VERSION ""

NS_ :

BS_:

BU_:

BO_ 2561146622 AUXIO2: 8 Vector__XXX
 SG_ AuxiliaryIO17 : 6|2@1+ (1,0) [0|3] "" Vector__XXX
 SG_ AuxiliaryIO18 : 4|2@1+ (1,0) [0|3] "" Vector__XXX
 SG_ AuxiliaryIO19 : 2|2@1+ (1,0) [0|3] "" Vector__XXX
 SG_ AuxiliaryIO20 : 0|2@1+ (1,0) [0|3] "" Vector__XXX
 SG_ AuxiliaryIO21 : 14|2@1+ (1,0) [0|3] "" Vector__XXX
 SG_ AuxiliaryIO22 : 12|2@1+ (1,0) [0|3] "" Vector__XXX
 SG_ AuxiliaryIO23 : 10|2@1+ (1,0) [0|3] "" Vector__XXX
 SG_ AuxiliaryIO24 : 8|2@1+ (1,0) [0|3] "" Vector__XXX
 SG_ AuxiliaryIO25 : 22|2@1+ (1,0) [0|3] "" Vector__XXX
 SG_ AuxiliaryIO26 : 20|2@1+ (1,0) [0|3] "" Vector__XXX
 SG_ AuxiliaryIO27 : 18|2@1+ (1,0) [0|3] "" Vector__XXX
 SG_ AuxiliaryIO28 : 16|2@1+ (1,0) [0|3] "" Vector__XXX
 SG_ AuxiliaryIO29 : 30|2@1+ (1,0) [0|3] "" Vector__XXX
 SG_ AuxiliaryIO30 : 28|2@1+ (1,0) [0|3] "" Vector__XXX
 SG_ AuxiliaryIO31 : 26|2@1+ (1,0) [0|3] "" Vector__XXX
 SG_ AuxiliaryIO32 : 24|2@1+ (1,0) [0|3] "" Vector__XXX
 SG_ AuxiliaryIO33 : 38|2@1+ (1,0) [0|3] "" Vector__XXX
 SG_ AuxiliaryIO34 : 36|2@1+ (1,0) [0|3] "" Vector__XXX
 SG_ AuxiliaryIO35 : 34|2@1+ (1,0) [0|3] "" Vector__XXX
 SG_ AuxiliaryIO36 : 32|2@1+ (1,0) [0|3] "" Vector__XXX
 SG_ AuxiliaryIO37 : 46|2@1+ (1,0) [0|3] "" Vector__XXX
 SG_ AuxiliaryIO38 : 44|2@1+ (1,0) [0|3] "" Vector__XXX
 SG_ AuxiliaryIO39 : 42|2@1+ (1,0) [0|3] "" Vector__XXX
 SG_ AuxiliaryIO40 : 40|2@1+ (1,0) [0|3] "" Vector__XXX
 SG_ AuxiliaryIO41 : 54|2@1+ (1,0) [0|3] "" Vector__XXX
 SG_ AuxiliaryIO42 : 52|2@1+ (1,0) [0|3] "" Vector__XXX
 SG_ AuxiliaryIO43 : 50|2@1+ (1,0) [0|3] "" Vector__XXX
 SG_ AuxiliaryIO44 : 48|2@1+ (1,0) [0|3] "" Vector__XXX
 SG_ AuxiliaryIO45 : 62|2@1+ (1,0) [0|3] "" Vector__XXX
 SG_ AuxiliaryIO46 : 60|2@1+ (1,0) [0|3] "" Vector__XXX
 SG_ AuxiliaryIO47 : 58|2@1+ (1,0) [0|3] "" Vector__XXX
 SG_ AuxiliaryIO48 : 56|2@1+ (1,0) [0|3] "" Vector__XXX

BO_ 2561212158 DISP1: 8 Vector__XXX
 SG_ TextDisplayIndex : 16|8@1+ (1,0) [0|250] "count" Vector__XXX
 SG_ TextDisplayInstructions : 0|4@1+ (1,0) [0|15] "" Vector__XXX

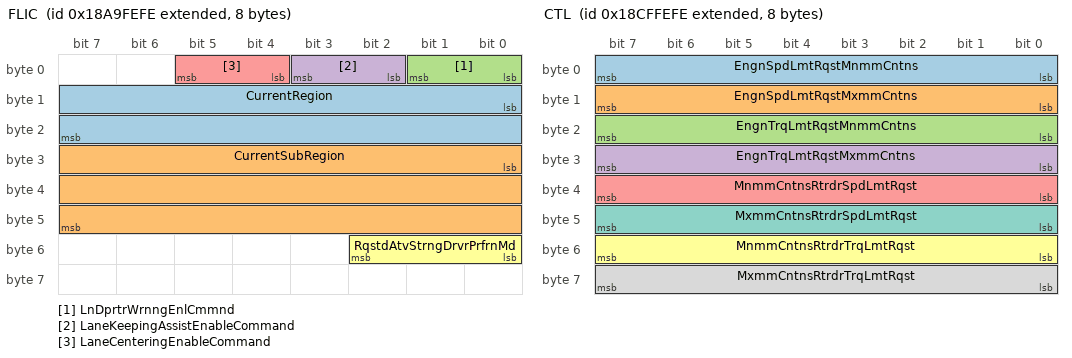
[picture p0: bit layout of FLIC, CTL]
BO_ 2561277694 FLIC: 8 Vector__XXX
 SG_ CurrentRegion : 8|16@1+ (1,0) [0|255] "ASCII" Vector__XXX
 SG_ CurrentSubRegion : 24|24@1+ (1,0) [0|255] "ASCII" Vector__XXX
 SG_ LnDprtrWrnngEnlCmmnd : 0|2@1+ (1,0) [0|3] "" Vector__XXX
 SG_ LaneKeepingAssistEnableCommand : 2|2@1+ (1,0) [0|3] "" Vector__XXX
 SG_ LaneCenteringEnableCommand : 4|2@1+ (1,0) [0|3] "" Vector__XXX
 SG_ RqstdAtvStrngDrvrPrfrnMd : 48|3@1+ (1,0) [0|7] "" Vector__XXX

BO_ 2561605374 TPRS: 8 Vector__XXX
 SG_ ReferenceTirePressureSetting : 8|8@1+ (8,0) [0|2000] "kPa" Vector__XXX
 SG_ TireLocation : 0|8@1+ (1,0) [0|255] "" Vector__XXX

BO_ 2563768062 CTL: 8 Vector__XXX
 SG_ EngnSpdLmtRqstMnmmCntns : 0|8@1+ (32,0) [0|8000] "rpm" Vector__XXX
 SG_ EngnSpdLmtRqstMxmmCntns : 8|8@1+ (32,0) [0|8000] "rpm" Vector__XXX
 SG_ EngnTrqLmtRqstMnmmCntns : 16|8@1+ (1,-125) [-125|125] "%" Vector__XXX
 SG_ EngnTrqLmtRqstMxmmCntns : 24|8@1+ (1,-125) [-125|125] "%" Vector__XXX
 SG_ MnmmCntnsRtrdrSpdLmtRqst : 32|8@1+ (32,0) [0|8000] "rpm" Vector__XXX
 SG_ MnmmCntnsRtrdrTrqLmtRqst : 48|8@1+ (1,-125) [-125|125] "%" Vector__XXX
 SG_ MxmmCntnsRtrdrSpdLmtRqst : 40|8@1+ (32,0) [0|8000] "rpm" Vector__XXX
 SG_ MxmmCntnsRtrdrTrqLmtRqst : 56|8@1+ (1,-125) [-125|125] "%" Vector__XXX

BO_ 2563833598 CL: 8 Vector__XXX
 SG_ IlluminationBrightnessPercent : 0|8@1+ (0.4,0) [0|100] "%" Vector__XXX
 SG_ SwthBklghtIllmntnBrghtnssPrnt : 8|8@1+ (0.4,0) [0|100] "%" Vector__XXX
 SG_ SwthIndtnIllmntnBrghtnssPrnt : 16|8@1+ (0.4,0) [0|100] "%" Vector__XXX

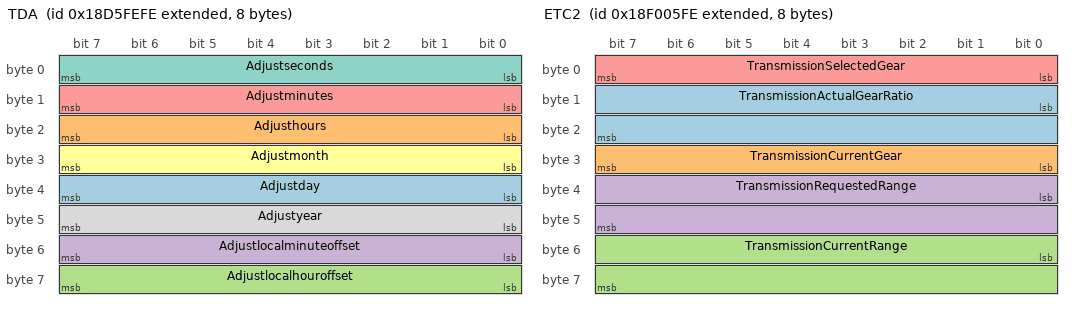
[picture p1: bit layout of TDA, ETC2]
BO_ 2564161278 TDA: 8 Vector__XXX
 SG_ Adjustday : 32|8@1+ (0.25,0) [0|62.5] "days" Vector__XXX
 SG_ Adjusthours : 16|8@1+ (1,0) [0|250] "h" Vector__XXX
 SG_ Adjustlocalhouroffset : 56|8@1+ (1,-125) [-125|125] "h" Vector__XXX
 SG_ Adjustlocalminuteoffset : 48|8@1+ (1,-125) [-125|125] "min" Vector__XXX
 SG_ Adjustminutes : 8|8@1+ (1,0) [0|250] "min" Vector__XXX
 SG_ Adjustmonth : 24|8@1+ (1,0) [0|250] "months" Vector__XXX
 SG_ Adjustseconds : 0|8@1+ (0.25,0) [0|62.5] "s" Vector__XXX
 SG_ Adjustyear : 40|8@1+ (1,1985) [1985|2235] "years" Vector__XXX

BO_ 2564882174 CM1: 8 Vector__XXX
 SG_ AftrtrtmntRgnrtnFrSwth : 42|2@1+ (1,0) [0|3] "" Vector__XXX
 SG_ AftrtrtmntRgnrtnInhtSwth : 40|2@1+ (1,0) [0|3] "" Vector__XXX
 SG_ AtmtGrShftngEnlSwth : 44|2@1+ (1,0) [0|3] "" Vector__XXX
 SG_ AuxiliaryHeaterModeRequest : 48|4@1+ (1,0) [0|15] "" Vector__XXX
 SG_ AxlrHtrClntPmpRqst : 24|2@1+ (1,0) [0|3] "" Vector__XXX
 SG_ BatteryMainSwitchHoldRequest : 26|2@1+ (1,0) [0|3] "" Vector__XXX
 SG_ CabInteriorTemperatureCommand : 8|16@1+ (0.03125,-273) [-273|1734.96875] "degC" Vector__XXX
 SG_ EngineFan1RequestedPercentSpeed : 0|8@1+ (0.4,0) [0|100] "%" Vector__XXX
 SG_ EngnAtmtStrtEnlSwth : 46|2@1+ (1,0) [0|3] "" Vector__XXX
 SG_ OperatorSeatDirectionSwitch : 28|2@1+ (1,0) [0|3] "" Vector__XXX
 SG_ ParkBrakeCommand : 32|2@1+ (1,0) [0|3] "" Vector__XXX
 SG_ RequestCabZoneHeating : 54|2@1+ (1,0) [0|3] "" Vector__XXX
 SG_ RequestEngineZoneHeating : 52|2@1+ (1,0) [0|3] "" Vector__XXX
 SG_ SeatBeltSwitch : 30|2@1+ (1,0) [0|3] "" Vector__XXX
 SG_ SltdMxmmVhlSpdLmt : 56|8@1+ (1,0) [0|250] "count" Vector__XXX
 SG_ VhlLmtngSpdGvrnrDrmntSwth : 34|2@1+ (1,0) [0|3] "" Vector__XXX
 SG_ VhlLmtngSpdGvrnrEnlSwth : 38|2@1+ (1,0) [0|3] "" Vector__XXX
 SG_ VhlLmtngSpdGvrnrInrmntSwth : 36|2@1+ (1,0) [0|3] "" Vector__XXX

BO_ 2565865982 EBC1: 8 Vector__XXX
 SG_ ABSEBSAmrWrnngSgnlPwrdVhl : 44|2@1+ (1,0) [0|3] "" Vector__XXX
 SG_ ABSFullyOperational : 40|2@1+ (1,0) [0|3] "" Vector__XXX
 SG_ ABSOffroadSwitch : 16|2@1+ (1,0) [0|3] "" Vector__XXX
 SG_ AcceleratorInterlockSwitch : 24|2@1+ (1,0) [0|3] "" Vector__XXX
 SG_ AntiLockBrakingABSActive : 4|2@1+ (1,0) [0|3] "" Vector__XXX
 SG_ ASRBrakeControlActive : 2|2@1+ (1,0) [0|3] "" Vector__XXX
 SG_ ASREngineControlActive : 0|2@1+ (1,0) [0|3] "" Vector__XXX
 SG_ ASRHillHolderSwitch : 20|2@1+ (1,0) [0|3] "" Vector__XXX
 SG_ ASROffroadSwitch : 18|2@1+ (1,0) [0|3] "" Vector__XXX
 SG_ ATCASRInformationSignal : 46|2@1+ (1,0) [0|3] "" Vector__XXX
 SG_ BrakePedalPosition : 8|8@1+ (0.4,0) [0|100] "%" Vector__XXX
 SG_ EBSBrakeSwitch : 6|2@1+ (1,0) [0|3] "" Vector__XXX
 SG_ EBSRedWarningSignal : 42|2@1+ (1,0) [0|3] "" Vector__XXX
 SG_ EngineAuxiliaryShutdownSwitch : 28|2@1+ (1,0) [0|3] "" Vector__XXX
 SG_ EngineDerateSwitch : 26|2@1+ (1,0) [0|3] "" Vector__XXX
 SG_ EngineRetarderSelection : 32|8@1+ (0.4,0) [0|100] "%" Vector__XXX
 SG_ Haltbrakeswitch : 58|2@1+ (1,0) [0|3] "" Vector__XXX
 SG_ RailroadModeSwitch : 56|2@1+ (1,0) [0|3] "" Vector__XXX
 SG_ RemoteAcceleratorEnableSwitch : 30|2@1+ (1,0) [0|3] "" Vector__XXX
 SG_ SrAddrssfCntrllngDvfrBrkCntrl : 48|8@1+ (1,0) [0|255] "SA" Vector__XXX
 SG_ TractionControlOverrideSwitch : 22|2@1+ (1,0) [0|3] "" Vector__XXX
 SG_ TrailerABSStatus : 60|2@1+ (1,0) [0|3] "" Vector__XXX
 SG_ TrtrMntdTrlrABSWrnngSgnl : 62|2@1+ (1,0) [0|3] "" Vector__XXX

BO_ 2565867006 ETC2: 8 Vector__XXX
 SG_ TransmissionActualGearRatio : 8|16@1+ (0.001,0) [0|64.255] "Ratio" Vector__XXX
 SG_ TransmissionCurrentGear : 24|8@1+ (1,-125) [-125|125] "gear value" Vector__XXX
 SG_ TransmissionCurrentRange : 48|16@1+ (1,0) [0|255] "ASCII" Vector__XXX
 SG_ TransmissionRequestedRange : 32|16@1+ (1,0) [0|255] "ASCII" Vector__XXX
 SG_ TransmissionSelectedGear : 0|8@1+ (1,-125) [-125|125] "gear value" Vector__XXX

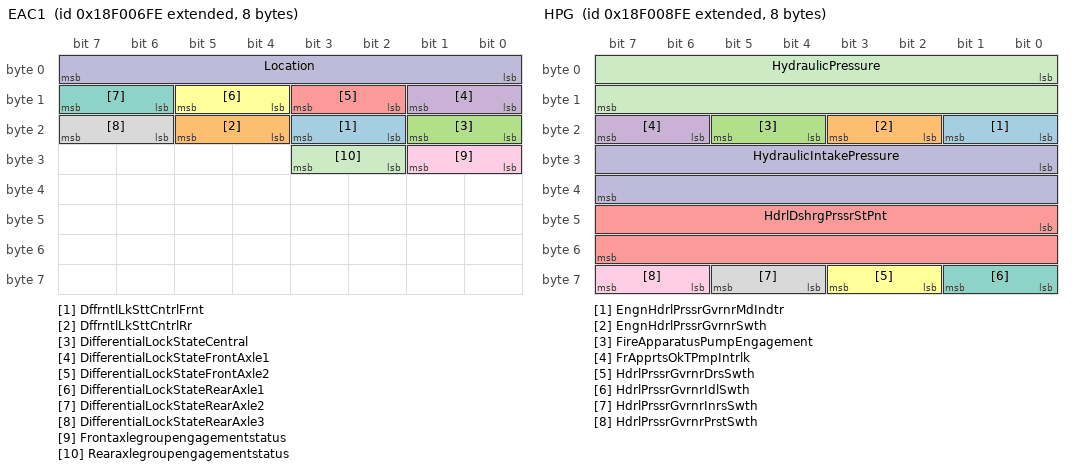
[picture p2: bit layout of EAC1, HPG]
BO_ 2565867262 EAC1: 8 Vector__XXX
 SG_ DffrntlLkSttCntrlFrnt : 18|2@1+ (1,0) [0|3] "" Vector__XXX
 SG_ DffrntlLkSttCntrlRr : 20|2@1+ (1,0) [0|3] "" Vector__XXX
 SG_ DifferentialLockStateCentral : 16|2@1+ (1,0) [0|3] "" Vector__XXX
 SG_ DifferentialLockStateFrontAxle1 : 8|2@1+ (1,0) [0|3] "" Vector__XXX
 SG_ DifferentialLockStateFrontAxle2 : 10|2@1+ (1,0) [0|3] "" Vector__XXX
 SG_ DifferentialLockStateRearAxle1 : 12|2@1+ (1,0) [0|3] "" Vector__XXX
 SG_ DifferentialLockStateRearAxle2 : 14|2@1+ (1,0) [0|3] "" Vector__XXX
 SG_ DifferentialLockStateRearAxle3 : 22|2@1+ (1,0) [0|3] "" Vector__XXX
 SG_ Frontaxlegroupengagementstatus : 24|2@1+ (1,0) [0|3] "" Vector__XXX
 SG_ Location : 0|8@1+ (1,0) [0|255] "" Vector__XXX
 SG_ Rearaxlegroupengagementstatus : 26|2@1+ (1,0) [0|3] "" Vector__XXX

BO_ 2565867774 HPG: 8 Vector__XXX
 SG_ EngnHdrlPrssrGvrnrMdIndtr : 16|2@1+ (1,0) [0|3] "" Vector__XXX
 SG_ EngnHdrlPrssrGvrnrSwth : 18|2@1+ (1,0) [0|3] "" Vector__XXX
 SG_ FireApparatusPumpEngagement : 20|2@1+ (1,0) [0|3] "" Vector__XXX
 SG_ FrApprtsOkTPmpIntrlk : 22|2@1+ (1,0) [0|3] "" Vector__XXX
 SG_ HdrlDshrgPrssrStPnt : 40|16@1+ (2,0) [0|128510] "kPa" Vector__XXX
 SG_ HdrlPrssrGvrnrDrsSwth : 58|2@1+ (1,0) [0|3] "" Vector__XXX
 SG_ HdrlPrssrGvrnrIdlSwth : 56|2@1+ (1,0) [0|3] "" Vector__XXX
 SG_ HdrlPrssrGvrnrInrsSwth : 60|2@1+ (1,0) [0|3] "" Vector__XXX
 SG_ HdrlPrssrGvrnrPrstSwth : 62|2@1+ (1,0) [0|3] "" Vector__XXX
 SG_ HydraulicIntakePressure : 24|16@1+ (0.0001220703125,-1) [-1|6.84362793] "MPa" Vector__XXX
 SG_ HydraulicPressure : 0|16@1+ (2,0) [0|128510] "kPa" Vector__XXX

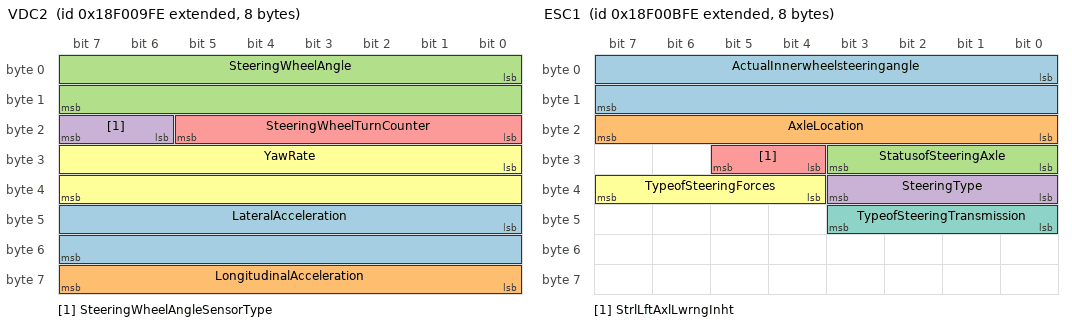
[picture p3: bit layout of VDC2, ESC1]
BO_ 2565868030 VDC2: 8 Vector__XXX
 SG_ LateralAcceleration : 40|16@1+ (0.00048828125,-15.687) [-15.687|15.687] "m/(s*s)" Vector__XXX
 SG_ LongitudinalAcceleration : 56|8@1+ (0.1,-12.5) [-12.5|12.5] "m/(s*s)" Vector__XXX
 SG_ SteeringWheelAngle : 0|16@1+ (0.0009765625,-31.374) [-31.374|31.374] "rad" Vector__XXX
 SG_ SteeringWheelAngleSensorType : 22|2@1+ (1,0) [0|3] "" Vector__XXX
 SG_ SteeringWheelTurnCounter : 16|6@1+ (1,-32) [-32|29] "turns" Vector__XXX
 SG_ YawRate : 24|16@1+ (0.0001220703125,-3.92) [-3.92|3.92] "rad/s" Vector__XXX

BO_ 2565868542 ESC1: 8 Vector__XXX
 SG_ ActualInnerwheelsteeringangle : 0|16@1+ (0.00390625,-125) [-125|125] "deg" Vector__XXX
 SG_ AxleLocation : 16|8@1+ (1,0) [0|255] "" Vector__XXX
 SG_ StatusofSteeringAxle : 24|4@1+ (1,0) [0|15] "" Vector__XXX
 SG_ SteeringType : 32|4@1+ (1,0) [0|15] "" Vector__XXX
 SG_ StrlLftAxlLwrngInht : 28|2@1+ (1,0) [0|3] "" Vector__XXX
 SG_ TypeofSteeringForces : 36|4@1+ (1,0) [0|15] "" Vector__XXX
 SG_ TypeofSteeringTransmission : 40|4@1+ (1,0) [0|15] "" Vector__XXX

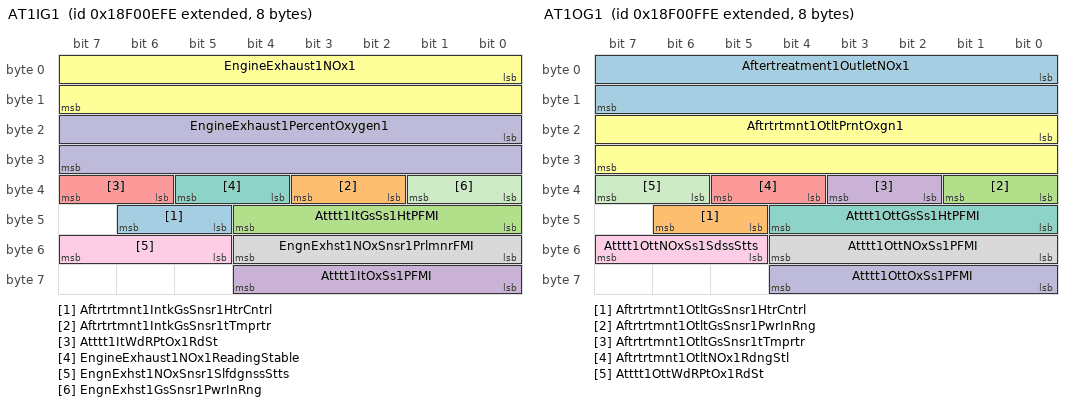
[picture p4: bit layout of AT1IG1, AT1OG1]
BO_ 2565869310 AT1IG1: 8 Vector__XXX
 SG_ Aftrtrtmnt1IntkGsSnsr1HtrCntrl : 45|2@1+ (1,0) [0|3] "" Vector__XXX
 SG_ Aftrtrtmnt1IntkGsSnsr1tTmprtr : 34|2@1+ (1,0) [0|3] "" Vector__XXX
 SG_ Atttt1ItGsSs1HtPFMI : 40|5@1+ (1,0) [0|31] "binary" Vector__XXX
 SG_ Atttt1ItOxSs1PFMI : 56|5@1+ (1,0) [0|31] "binary" Vector__XXX
 SG_ Atttt1ItWdRPtOx1RdSt : 38|2@1+ (1,0) [0|3] "" Vector__XXX
 SG_ EngineExhaust1NOx1 : 0|16@1+ (0.05,-200) [-200|3012.75] "ppm" Vector__XXX
 SG_ EngineExhaust1NOx1ReadingStable : 36|2@1+ (1,0) [0|3] "" Vector__XXX
 SG_ EngnExhst1NOxSnsr1PrlmnrFMI : 48|5@1+ (1,0) [0|31] "binary" Vector__XXX
 SG_ EngnExhst1NOxSnsr1SlfdgnssStts : 53|3@1+ (1,0) [0|7] "" Vector__XXX
 SG_ EngineExhaust1PercentOxygen1 : 16|16@1+ (0.000514,-12) [-12|21.02707] "%" Vector__XXX
 SG_ EngnExhst1GsSnsr1PwrInRng : 32|2@1+ (1,0) [0|3] "" Vector__XXX

BO_ 2565869566 AT1OG1: 8 Vector__XXX
 SG_ Aftertreatment1OutletNOx1 : 0|16@1+ (0.05,-200) [-200|3012.75] "ppm" Vector__XXX
 SG_ Aftrtrtmnt1OtltGsSnsr1HtrCntrl : 45|2@1+ (1,0) [0|3] "" Vector__XXX
 SG_ Aftrtrtmnt1OtltGsSnsr1PwrInRng : 32|2@1+ (1,0) [0|3] "" Vector__XXX
 SG_ Aftrtrtmnt1OtltGsSnsr1tTmprtr : 34|2@1+ (1,0) [0|3] "" Vector__XXX
 SG_ Aftrtrtmnt1OtltNOx1RdngStl : 36|2@1+ (1,0) [0|3] "" Vector__XXX
 SG_ Aftrtrtmnt1OtltPrntOxgn1 : 16|16@1+ (0.000514,-12) [-12|21.02707] "%" Vector__XXX
 SG_ Atttt1OttGsSs1HtPFMI : 40|5@1+ (1,0) [0|31] "binary" Vector__XXX
 SG_ Atttt1OttNOxSs1PFMI : 48|5@1+ (1,0) [0|31] "binary" Vector__XXX
 SG_ Atttt1OttNOxSs1SdssStts : 53|3@1+ (1,0) [0|7] "" Vector__XXX
 SG_ Atttt1OttOxSs1PFMI : 56|5@1+ (1,0) [0|31] "binary" Vector__XXX
 SG_ Atttt1OttWdRPtOx1RdSt : 38|2@1+ (1,0) [0|3] "" Vector__XXX

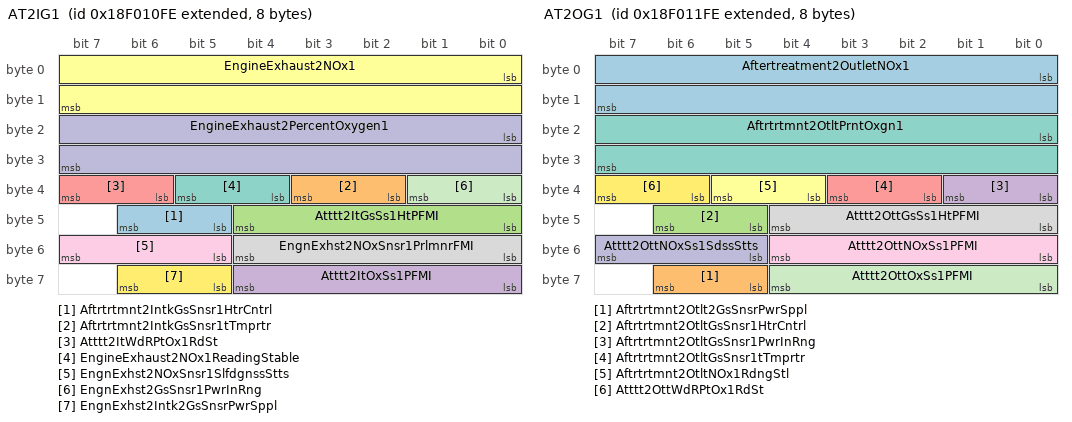
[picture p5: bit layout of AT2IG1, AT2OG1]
BO_ 2565869822 AT2IG1: 8 Vector__XXX
 SG_ Aftrtrtmnt2IntkGsSnsr1HtrCntrl : 45|2@1+ (1,0) [0|3] "" Vector__XXX
 SG_ Aftrtrtmnt2IntkGsSnsr1tTmprtr : 34|2@1+ (1,0) [0|3] "" Vector__XXX
 SG_ Atttt2ItGsSs1HtPFMI : 40|5@1+ (1,0) [0|31] "binary" Vector__XXX
 SG_ Atttt2ItOxSs1PFMI : 56|5@1+ (1,0) [0|31] "binary" Vector__XXX
 SG_ Atttt2ItWdRPtOx1RdSt : 38|2@1+ (1,0) [0|3] "" Vector__XXX
 SG_ EngineExhaust2NOx1 : 0|16@1+ (0.05,-200) [-200|3012.75] "ppm" Vector__XXX
 SG_ EngineExhaust2NOx1ReadingStable : 36|2@1+ (1,0) [0|3] "" Vector__XXX
 SG_ EngnExhst2NOxSnsr1PrlmnrFMI : 48|5@1+ (1,0) [0|31] "binary" Vector__XXX
 SG_ EngnExhst2NOxSnsr1SlfdgnssStts : 53|3@1+ (1,0) [0|7] "" Vector__XXX
 SG_ EngineExhaust2PercentOxygen1 : 16|16@1+ (0.000514,-12) [-12|21.02707] "%" Vector__XXX
 SG_ EngnExhst2GsSnsr1PwrInRng : 32|2@1+ (1,0) [0|3] "" Vector__XXX
 SG_ EngnExhst2Intk2GsSnsrPwrSppl : 61|2@1+ (1,0) [0|3] "" Vector__XXX

BO_ 2565870078 AT2OG1: 8 Vector__XXX
 SG_ Aftertreatment2OutletNOx1 : 0|16@1+ (0.05,-200) [-200|3012.75] "ppm" Vector__XXX
 SG_ Aftrtrtmnt2Otlt2GsSnsrPwrSppl : 61|2@1+ (1,0) [0|3] "" Vector__XXX
 SG_ Aftrtrtmnt2OtltGsSnsr1HtrCntrl : 45|2@1+ (1,0) [0|3] "" Vector__XXX
 SG_ Aftrtrtmnt2OtltGsSnsr1PwrInRng : 32|2@1+ (1,0) [0|3] "" Vector__XXX
 SG_ Aftrtrtmnt2OtltGsSnsr1tTmprtr : 34|2@1+ (1,0) [0|3] "" Vector__XXX
 SG_ Aftrtrtmnt2OtltNOx1RdngStl : 36|2@1+ (1,0) [0|3] "" Vector__XXX
 SG_ Aftrtrtmnt2OtltPrntOxgn1 : 16|16@1+ (0.000514,-12) [-12|21.02707] "%" Vector__XXX
 SG_ Atttt2OttGsSs1HtPFMI : 40|5@1+ (1,0) [0|31] "binary" Vector__XXX
 SG_ Atttt2OttNOxSs1PFMI : 48|5@1+ (1,0) [0|31] "binary" Vector__XXX
 SG_ Atttt2OttNOxSs1SdssStts : 53|3@1+ (1,0) [0|7] "" Vector__XXX
 SG_ Atttt2OttOxSs1PFMI : 56|5@1+ (1,0) [0|31] "binary" Vector__XXX
 SG_ Atttt2OttWdRPtOx1RdSt : 38|2@1+ (1,0) [0|3] "" Vector__XXX

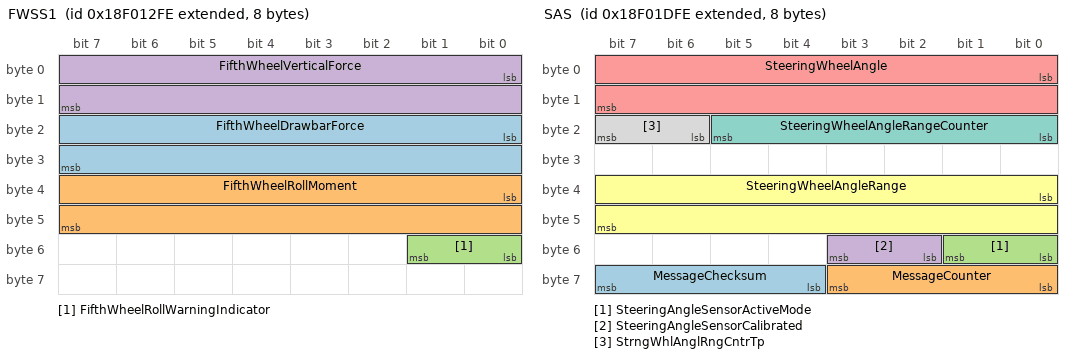
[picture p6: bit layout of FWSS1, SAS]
BO_ 2565870334 FWSS1: 8 Vector__XXX
 SG_ FifthWheelDrawbarForce : 16|16@1+ (10,-320000) [-320000|322550] "N" Vector__XXX
 SG_ FifthWheelRollMoment : 32|16@1+ (10,-320000) [-320000|322550] "N" Vector__XXX
 SG_ FifthWheelRollWarningIndicator : 48|2@1+ (1,0) [0|3] "" Vector__XXX
 SG_ FifthWheelVerticalForce : 0|16@1+ (5,0) [0|321275] "N" Vector__XXX

BO_ 2565873150 SAS: 8 Vector__XXX
 SG_ MessageChecksum : 60|4@1+ (1,0) [0|15] "count" Vector__XXX
 SG_ MessageCounter : 56|4@1+ (1,0) [0|15] "count" Vector__XXX
 SG_ SteeringAngleSensorActiveMode : 48|2@1+ (1,0) [0|3] "" Vector__XXX
 SG_ SteeringAngleSensorCalibrated : 50|2@1+ (1,0) [0|3] "" Vector__XXX
 SG_ SteeringWheelAngle : 0|16@1+ (0.0009765625,-31.374) [-31.374|31.374] "rad" Vector__XXX
 SG_ SteeringWheelAngleRange : 32|16@1+ (0.0009765625,-31.374) [-31.374|31.374] "rad" Vector__XXX
 SG_ SteeringWheelAngleRangeCounter : 16|6@1+ (1,-32) [-32|29] "range" Vector__XXX
 SG_ StrngWhlAnglRngCntrTp : 22|2@1+ (1,0) [0|3] "" Vector__XXX

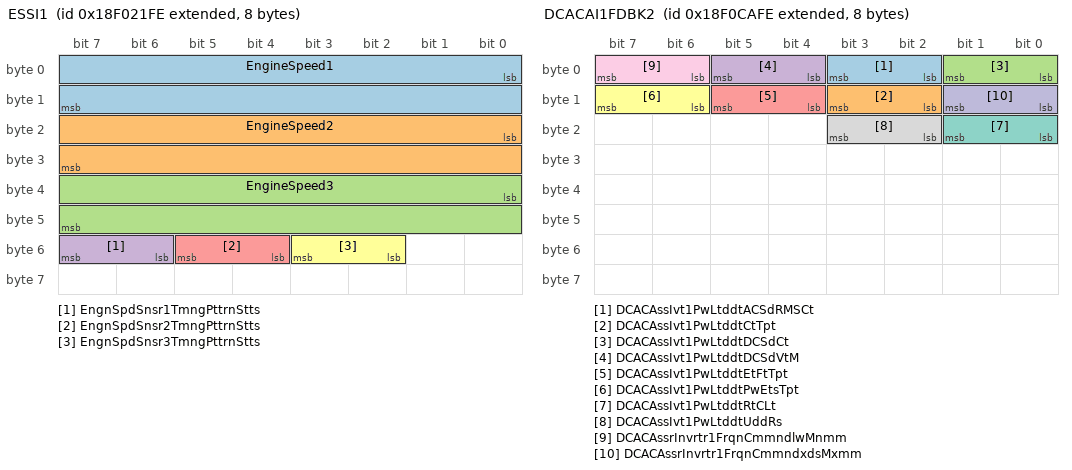
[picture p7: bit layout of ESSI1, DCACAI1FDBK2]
BO_ 2565874174 ESSI1: 8 Vector__XXX
 SG_ EngineSpeed1 : 0|16@1+ (0.5,0) [0|32127.5] "rpm" Vector__XXX
 SG_ EngineSpeed2 : 16|16@1+ (0.5,0) [0|32127.5] "rpm" Vector__XXX
 SG_ EngineSpeed3 : 32|16@1+ (0.5,0) [0|32127.5] "rpm" Vector__XXX
 SG_ EngnSpdSnsr1TmngPttrnStts : 54|2@1+ (1,0) [0|3] "" Vector__XXX
 SG_ EngnSpdSnsr2TmngPttrnStts : 52|2@1+ (1,0) [0|3] "" Vector__XXX
 SG_ EngnSpdSnsr3TmngPttrnStts : 50|2@1+ (1,0) [0|3] "" Vector__XXX

BO_ 2565877502 ETCC: 8 Vector__XXX
 SG_ EExstB1PssRtCtCd : 32|16@1+ (0.0025,0) [0|160.6375] "%" Vector__XXX
 SG_ EngnTrhrgrWstgtAttr1Cmmnd : 0|16@1+ (0.0025,0) [0|160.6375] "%" Vector__XXX
 SG_ EngnTrhrgrWstgtAttr2Cmmnd : 16|16@1+ (0.0025,0) [0|160.6375] "%" Vector__XXX
 SG_ ETCpssBwAtt1Cd : 48|16@1+ (0.0025,0) [0|160.6375] "%" Vector__XXX

BO_ 2565917438 DCACAI1FDBK2: 8 Vector__XXX
 SG_ DCACAssIvt1PwLtddtACSdRMSCt : 2|2@1+ (1,0) [0|3] "" Vector__XXX
 SG_ DCACAssIvt1PwLtddtCtTpt : 10|2@1+ (1,0) [0|3] "" Vector__XXX
 SG_ DCACAssIvt1PwLtddtDCSdCt : 0|2@1+ (1,0) [0|3] "" Vector__XXX
 SG_ DCACAssIvt1PwLtddtDCSdVtM : 4|2@1+ (1,0) [0|3] "" Vector__XXX
 SG_ DCACAssIvt1PwLtddtEtFtTpt : 12|2@1+ (1,0) [0|3] "" Vector__XXX
 SG_ DCACAssIvt1PwLtddtPwEtsTpt : 14|2@1+ (1,0) [0|3] "" Vector__XXX
 SG_ DCACAssIvt1PwLtddtRtCLt : 16|2@1+ (1,0) [0|3] "" Vector__XXX
 SG_ DCACAssIvt1PwLtddtUddRs : 18|2@1+ (1,0) [0|3] "" Vector__XXX
 SG_ DCACAssrInvrtr1FrqnCmmndlwMnmm : 6|2@1+ (1,0) [0|3] "" Vector__XXX
 SG_ DCACAssrInvrtr1FrqnCmmndxdsMxmm : 8|2@1+ (1,0) [0|3] "" Vector__XXX

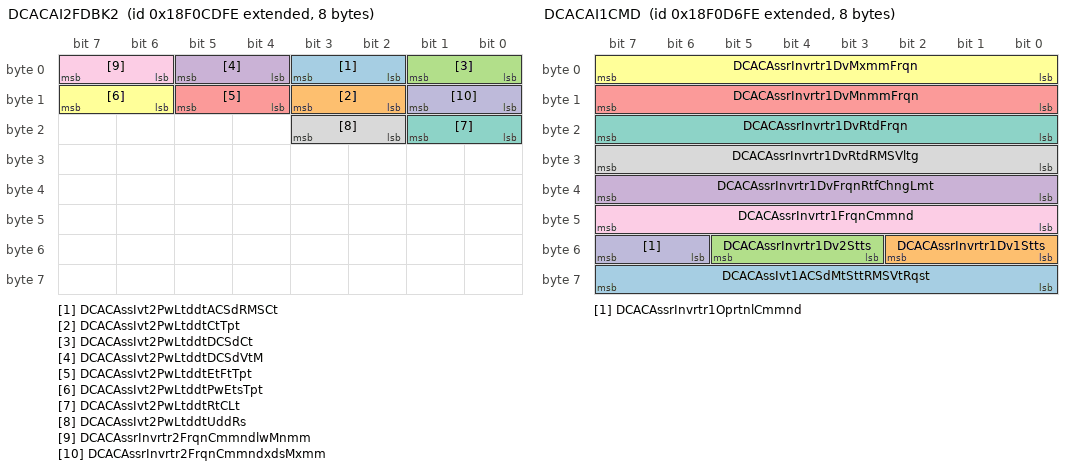
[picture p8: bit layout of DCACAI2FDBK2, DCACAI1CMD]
BO_ 2565918206 DCACAI2FDBK2: 8 Vector__XXX
 SG_ DCACAssIvt2PwLtddtACSdRMSCt : 2|2@1+ (1,0) [0|3] "" Vector__XXX
 SG_ DCACAssIvt2PwLtddtCtTpt : 10|2@1+ (1,0) [0|3] "" Vector__XXX
 SG_ DCACAssIvt2PwLtddtDCSdCt : 0|2@1+ (1,0) [0|3] "" Vector__XXX
 SG_ DCACAssIvt2PwLtddtDCSdVtM : 4|2@1+ (1,0) [0|3] "" Vector__XXX
 SG_ DCACAssIvt2PwLtddtEtFtTpt : 12|2@1+ (1,0) [0|3] "" Vector__XXX
 SG_ DCACAssIvt2PwLtddtPwEtsTpt : 14|2@1+ (1,0) [0|3] "" Vector__XXX
 SG_ DCACAssIvt2PwLtddtRtCLt : 16|2@1+ (1,0) [0|3] "" Vector__XXX
 SG_ DCACAssIvt2PwLtddtUddRs : 18|2@1+ (1,0) [0|3] "" Vector__XXX
 SG_ DCACAssrInvrtr2FrqnCmmndlwMnmm : 6|2@1+ (1,0) [0|3] "" Vector__XXX
 SG_ DCACAssrInvrtr2FrqnCmmndxdsMxmm : 8|2@1+ (1,0) [0|3] "" Vector__XXX

BO_ 2565920510 DCACAI1CMD: 8 Vector__XXX
 SG_ DCACAssIvt1ACSdMtSttRMSVtRqst : 56|8@1+ (2,0) [0|500] "Vrms" Vector__XXX
 SG_ DCACAssrInvrtr1Dv1Stts : 48|3@1+ (1,0) [0|7] "" Vector__XXX
 SG_ DCACAssrInvrtr1Dv2Stts : 51|3@1+ (1,0) [0|7] "" Vector__XXX
 SG_ DCACAssrInvrtr1DvFrqnRtfChngLmt : 32|8@1+ (2,0) [0|500] "Hz/s" Vector__XXX
 SG_ DCACAssrInvrtr1DvMnmmFrqn : 8|8@1+ (1,0) [0|250] "Hz" Vector__XXX
 SG_ DCACAssrInvrtr1DvMxmmFrqn : 0|8@1+ (1,0) [0|250] "Hz" Vector__XXX
 SG_ DCACAssrInvrtr1DvRtdFrqn : 16|8@1+ (1,0) [0|250] "Hz" Vector__XXX
 SG_ DCACAssrInvrtr1DvRtdRMSVltg : 24|8@1+ (2,0) [0|500] "Vrms" Vector__XXX
 SG_ DCACAssrInvrtr1FrqnCmmnd : 40|8@1+ (1,0) [0|250] "Hz" Vector__XXX
 SG_ DCACAssrInvrtr1OprtnlCmmnd : 54|2@1+ (1,0) [0|3] "" Vector__XXX

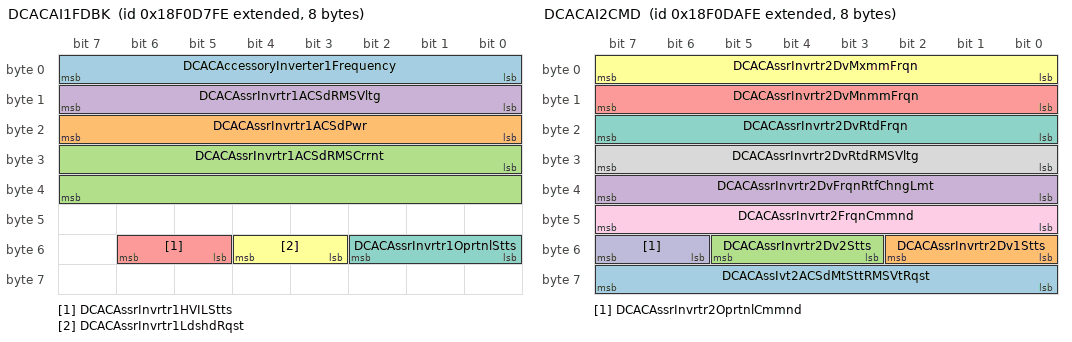
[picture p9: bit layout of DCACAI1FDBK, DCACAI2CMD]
BO_ 2565920766 DCACAI1FDBK: 8 Vector__XXX
 SG_ DCACAccessoryInverter1Frequency : 0|8@1+ (1,0) [0|250] "Hz" Vector__XXX
 SG_ DCACAssrInvrtr1ACSdPwr : 16|8@1+ (0.1,0) [0|25] "kW" Vector__XXX
 SG_ DCACAssrInvrtr1ACSdRMSCrrnt : 24|16@1+ (0.03125,0) [0|2007.96875] "Arms" Vector__XXX
 SG_ DCACAssrInvrtr1ACSdRMSVltg : 8|8@1+ (2,0) [0|500] "Vrms" Vector__XXX
 SG_ DCACAssrInvrtr1HVILStts : 53|2@1+ (1,0) [0|3] "" Vector__XXX
 SG_ DCACAssrInvrtr1LdshdRqst : 51|2@1+ (1,0) [0|3] "" Vector__XXX
 SG_ DCACAssrInvrtr1OprtnlStts : 48|3@1+ (1,0) [0|7] "" Vector__XXX

BO_ 2565921534 DCACAI2CMD: 8 Vector__XXX
 SG_ DCACAssIvt2ACSdMtSttRMSVtRqst : 56|8@1+ (2,0) [0|500] "Vrms" Vector__XXX
 SG_ DCACAssrInvrtr2Dv1Stts : 48|3@1+ (1,0) [0|7] "" Vector__XXX
 SG_ DCACAssrInvrtr2Dv2Stts : 51|3@1+ (1,0) [0|7] "" Vector__XXX
 SG_ DCACAssrInvrtr2DvFrqnRtfChngLmt : 32|8@1+ (2,0) [0|500] "Hz/s" Vector__XXX
 SG_ DCACAssrInvrtr2DvMnmmFrqn : 8|8@1+ (1,0) [0|250] "Hz" Vector__XXX
 SG_ DCACAssrInvrtr2DvMxmmFrqn : 0|8@1+ (1,0) [0|250] "Hz" Vector__XXX
 SG_ DCACAssrInvrtr2DvRtdFrqn : 16|8@1+ (1,0) [0|250] "Hz" Vector__XXX
 SG_ DCACAssrInvrtr2DvRtdRMSVltg : 24|8@1+ (2,0) [0|500] "Vrms" Vector__XXX
 SG_ DCACAssrInvrtr2FrqnCmmnd : 40|8@1+ (1,0) [0|250] "Hz" Vector__XXX
 SG_ DCACAssrInvrtr2OprtnlCmmnd : 54|2@1+ (1,0) [0|3] "" Vector__XXX

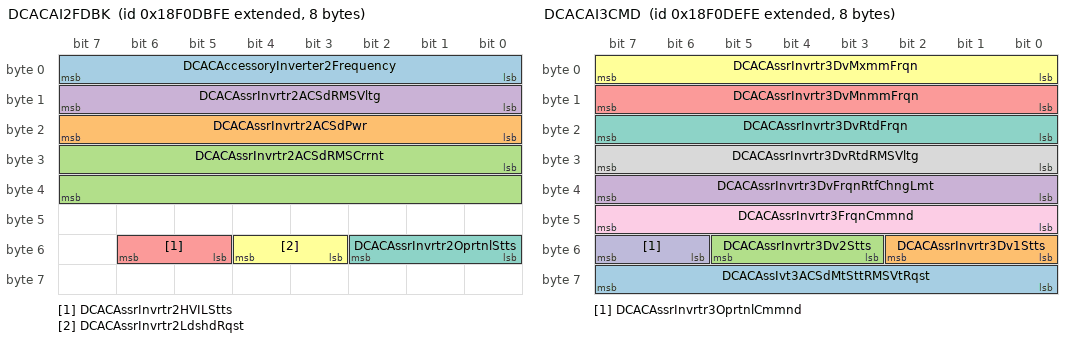
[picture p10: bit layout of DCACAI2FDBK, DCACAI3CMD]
BO_ 2565921790 DCACAI2FDBK: 8 Vector__XXX
 SG_ DCACAccessoryInverter2Frequency : 0|8@1+ (1,0) [0|250] "Hz" Vector__XXX
 SG_ DCACAssrInvrtr2ACSdPwr : 16|8@1+ (0.1,0) [0|25] "kW" Vector__XXX
 SG_ DCACAssrInvrtr2ACSdRMSCrrnt : 24|16@1+ (0.03125,0) [0|2007.96875] "Arms" Vector__XXX
 SG_ DCACAssrInvrtr2ACSdRMSVltg : 8|8@1+ (2,0) [0|500] "Vrms" Vector__XXX
 SG_ DCACAssrInvrtr2HVILStts : 53|2@1+ (1,0) [0|3] "" Vector__XXX
 SG_ DCACAssrInvrtr2LdshdRqst : 51|2@1+ (1,0) [0|3] "" Vector__XXX
 SG_ DCACAssrInvrtr2OprtnlStts : 48|3@1+ (1,0) [0|7] "" Vector__XXX

BO_ 2565922558 DCACAI3CMD: 8 Vector__XXX
 SG_ DCACAssIvt3ACSdMtSttRMSVtRqst : 56|8@1+ (2,0) [0|500] "Vrms" Vector__XXX
 SG_ DCACAssrInvrtr3Dv1Stts : 48|3@1+ (1,0) [0|7] "" Vector__XXX
 SG_ DCACAssrInvrtr3Dv2Stts : 51|3@1+ (1,0) [0|7] "" Vector__XXX
 SG_ DCACAssrInvrtr3DvFrqnRtfChngLmt : 32|8@1+ (2,0) [0|500] "Hz/s" Vector__XXX
 SG_ DCACAssrInvrtr3DvMnmmFrqn : 8|8@1+ (1,0) [0|250] "Hz" Vector__XXX
 SG_ DCACAssrInvrtr3DvMxmmFrqn : 0|8@1+ (1,0) [0|250] "Hz" Vector__XXX
 SG_ DCACAssrInvrtr3DvRtdFrqn : 16|8@1+ (1,0) [0|250] "Hz" Vector__XXX
 SG_ DCACAssrInvrtr3DvRtdRMSVltg : 24|8@1+ (2,0) [0|500] "Vrms" Vector__XXX
 SG_ DCACAssrInvrtr3FrqnCmmnd : 40|8@1+ (1,0) [0|250] "Hz" Vector__XXX
 SG_ DCACAssrInvrtr3OprtnlCmmnd : 54|2@1+ (1,0) [0|3] "" Vector__XXX

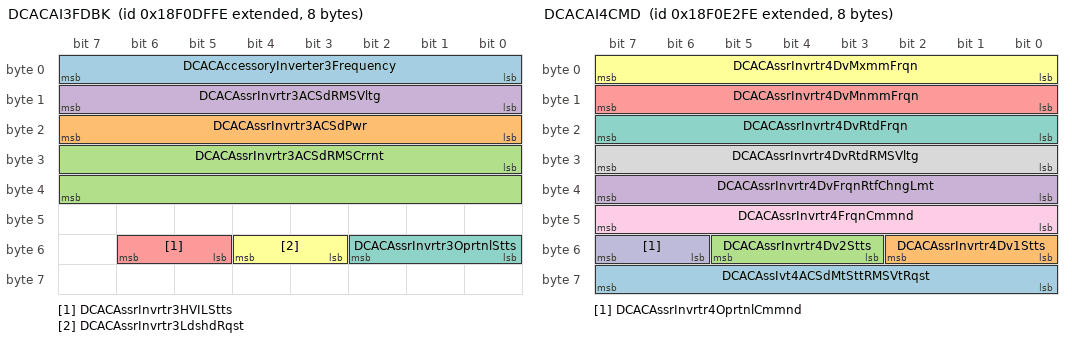
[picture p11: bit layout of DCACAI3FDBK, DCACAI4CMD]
BO_ 2565922814 DCACAI3FDBK: 8 Vector__XXX
 SG_ DCACAccessoryInverter3Frequency : 0|8@1+ (1,0) [0|250] "Hz" Vector__XXX
 SG_ DCACAssrInvrtr3ACSdPwr : 16|8@1+ (0.1,0) [0|25] "kW" Vector__XXX
 SG_ DCACAssrInvrtr3ACSdRMSCrrnt : 24|16@1+ (0.03125,0) [0|2007.96875] "Arms" Vector__XXX
 SG_ DCACAssrInvrtr3ACSdRMSVltg : 8|8@1+ (2,0) [0|500] "Vrms" Vector__XXX
 SG_ DCACAssrInvrtr3HVILStts : 53|2@1+ (1,0) [0|3] "" Vector__XXX
 SG_ DCACAssrInvrtr3LdshdRqst : 51|2@1+ (1,0) [0|3] "" Vector__XXX
 SG_ DCACAssrInvrtr3OprtnlStts : 48|3@1+ (1,0) [0|7] "" Vector__XXX

BO_ 2565923582 DCACAI4CMD: 8 Vector__XXX
 SG_ DCACAssIvt4ACSdMtSttRMSVtRqst : 56|8@1+ (2,0) [0|500] "Vrms" Vector__XXX
 SG_ DCACAssrInvrtr4Dv1Stts : 48|3@1+ (1,0) [0|7] "" Vector__XXX
 SG_ DCACAssrInvrtr4Dv2Stts : 51|3@1+ (1,0) [0|7] "" Vector__XXX
 SG_ DCACAssrInvrtr4DvFrqnRtfChngLmt : 32|8@1+ (2,0) [0|500] "Hz/s" Vector__XXX
 SG_ DCACAssrInvrtr4DvMnmmFrqn : 8|8@1+ (1,0) [0|250] "Hz" Vector__XXX
 SG_ DCACAssrInvrtr4DvMxmmFrqn : 0|8@1+ (1,0) [0|250] "Hz" Vector__XXX
 SG_ DCACAssrInvrtr4DvRtdFrqn : 16|8@1+ (1,0) [0|250] "Hz" Vector__XXX
 SG_ DCACAssrInvrtr4DvRtdRMSVltg : 24|8@1+ (2,0) [0|500] "Vrms" Vector__XXX
 SG_ DCACAssrInvrtr4FrqnCmmnd : 40|8@1+ (1,0) [0|250] "Hz" Vector__XXX
 SG_ DCACAssrInvrtr4OprtnlCmmnd : 54|2@1+ (1,0) [0|3] "" Vector__XXX

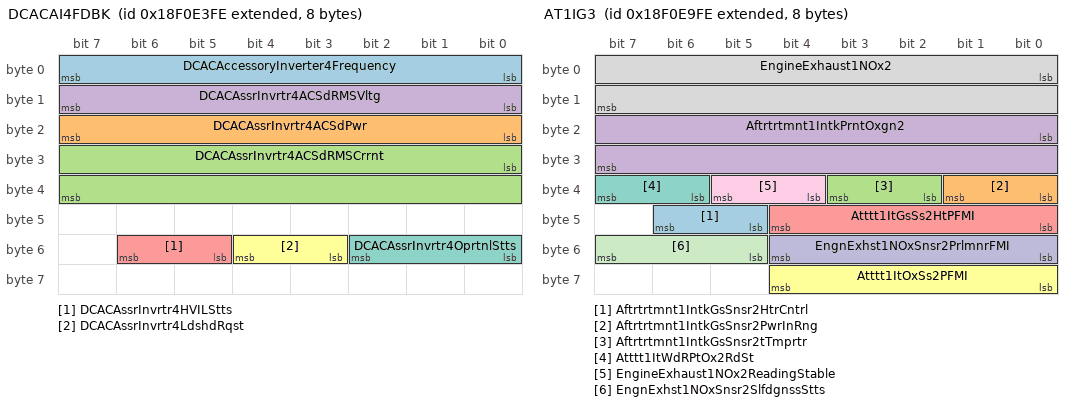
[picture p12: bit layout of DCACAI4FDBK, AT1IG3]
BO_ 2565923838 DCACAI4FDBK: 8 Vector__XXX
 SG_ DCACAccessoryInverter4Frequency : 0|8@1+ (1,0) [0|250] "Hz" Vector__XXX
 SG_ DCACAssrInvrtr4ACSdPwr : 16|8@1+ (0.1,0) [0|25] "kW" Vector__XXX
 SG_ DCACAssrInvrtr4ACSdRMSCrrnt : 24|16@1+ (0.03125,0) [0|2007.96875] "Arms" Vector__XXX
 SG_ DCACAssrInvrtr4ACSdRMSVltg : 8|8@1+ (2,0) [0|500] "Vrms" Vector__XXX
 SG_ DCACAssrInvrtr4HVILStts : 53|2@1+ (1,0) [0|3] "" Vector__XXX
 SG_ DCACAssrInvrtr4LdshdRqst : 51|2@1+ (1,0) [0|3] "" Vector__XXX
 SG_ DCACAssrInvrtr4OprtnlStts : 48|3@1+ (1,0) [0|7] "" Vector__XXX

BO_ 2565925374 AT1IG3: 8 Vector__XXX
 SG_ Aftrtrtmnt1IntkGsSnsr2HtrCntrl : 45|2@1+ (1,0) [0|3] "" Vector__XXX
 SG_ Aftrtrtmnt1IntkGsSnsr2PwrInRng : 32|2@1+ (1,0) [0|3] "" Vector__XXX
 SG_ Aftrtrtmnt1IntkGsSnsr2tTmprtr : 34|2@1+ (1,0) [0|3] "" Vector__XXX
 SG_ Aftrtrtmnt1IntkPrntOxgn2 : 16|16@1+ (0.000514,-12) [-12|21.02707] "%" Vector__XXX
 SG_ Atttt1ItGsSs2HtPFMI : 40|5@1+ (1,0) [0|31] "binary" Vector__XXX
 SG_ Atttt1ItOxSs2PFMI : 56|5@1+ (1,0) [0|31] "binary" Vector__XXX
 SG_ Atttt1ItWdRPtOx2RdSt : 38|2@1+ (1,0) [0|3] "" Vector__XXX
 SG_ EngineExhaust1NOx2 : 0|16@1+ (0.05,-200) [-200|3012.75] "ppm" Vector__XXX
 SG_ EngineExhaust1NOx2ReadingStable : 36|2@1+ (1,0) [0|3] "" Vector__XXX
 SG_ EngnExhst1NOxSnsr2PrlmnrFMI : 48|5@1+ (1,0) [0|31] "binary" Vector__XXX
 SG_ EngnExhst1NOxSnsr2SlfdgnssStts : 53|3@1+ (1,0) [0|7] "" Vector__XXX

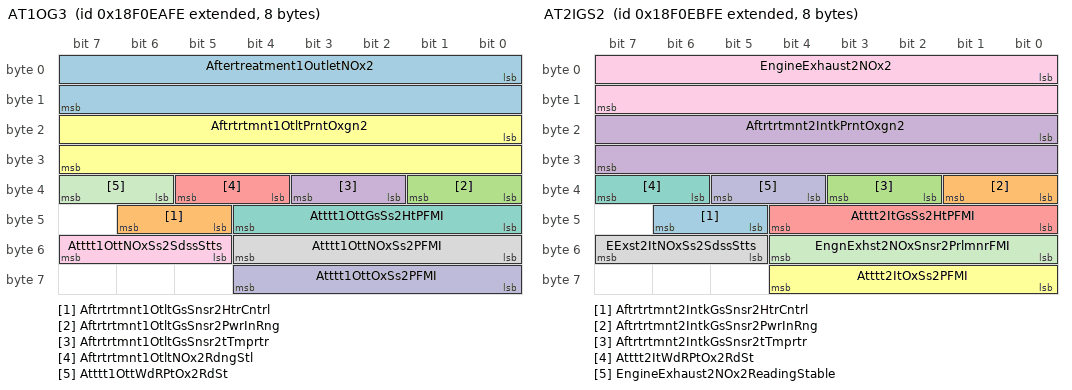
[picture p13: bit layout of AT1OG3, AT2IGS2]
BO_ 2565925630 AT1OG3: 8 Vector__XXX
 SG_ Aftertreatment1OutletNOx2 : 0|16@1+ (0.05,-200) [-200|3012.75] "ppm" Vector__XXX
 SG_ Aftrtrtmnt1OtltGsSnsr2HtrCntrl : 45|2@1+ (1,0) [0|3] "" Vector__XXX
 SG_ Aftrtrtmnt1OtltGsSnsr2PwrInRng : 32|2@1+ (1,0) [0|3] "" Vector__XXX
 SG_ Aftrtrtmnt1OtltGsSnsr2tTmprtr : 34|2@1+ (1,0) [0|3] "" Vector__XXX
 SG_ Aftrtrtmnt1OtltNOx2RdngStl : 36|2@1+ (1,0) [0|3] "" Vector__XXX
 SG_ Aftrtrtmnt1OtltPrntOxgn2 : 16|16@1+ (0.000514,-12) [-12|21.02707] "%" Vector__XXX
 SG_ Atttt1OttGsSs2HtPFMI : 40|5@1+ (1,0) [0|31] "binary" Vector__XXX
 SG_ Atttt1OttNOxSs2PFMI : 48|5@1+ (1,0) [0|31] "binary" Vector__XXX
 SG_ Atttt1OttNOxSs2SdssStts : 53|3@1+ (1,0) [0|7] "" Vector__XXX
 SG_ Atttt1OttOxSs2PFMI : 56|5@1+ (1,0) [0|31] "binary" Vector__XXX
 SG_ Atttt1OttWdRPtOx2RdSt : 38|2@1+ (1,0) [0|3] "" Vector__XXX

BO_ 2565925886 AT2IGS2: 8 Vector__XXX
 SG_ Aftrtrtmnt2IntkGsSnsr2HtrCntrl : 45|2@1+ (1,0) [0|3] "" Vector__XXX
 SG_ Aftrtrtmnt2IntkGsSnsr2PwrInRng : 32|2@1+ (1,0) [0|3] "" Vector__XXX
 SG_ Aftrtrtmnt2IntkGsSnsr2tTmprtr : 34|2@1+ (1,0) [0|3] "" Vector__XXX
 SG_ Aftrtrtmnt2IntkPrntOxgn2 : 16|16@1+ (0.000514,-12) [-12|21.02707] "%" Vector__XXX
 SG_ Atttt2ItGsSs2HtPFMI : 40|5@1+ (1,0) [0|31] "binary" Vector__XXX
 SG_ Atttt2ItOxSs2PFMI : 56|5@1+ (1,0) [0|31] "binary" Vector__XXX
 SG_ Atttt2ItWdRPtOx2RdSt : 38|2@1+ (1,0) [0|3] "" Vector__XXX
 SG_ EExst2ItNOxSs2SdssStts : 53|3@1+ (1,0) [0|7] "" Vector__XXX
 SG_ EngineExhaust2NOx2 : 0|16@1+ (0.05,-200) [-200|3012.75] "ppm" Vector__XXX
 SG_ EngineExhaust2NOx2ReadingStable : 36|2@1+ (1,0) [0|3] "" Vector__XXX
 SG_ EngnExhst2NOxSnsr2PrlmnrFMI : 48|5@1+ (1,0) [0|31] "binary" Vector__XXX

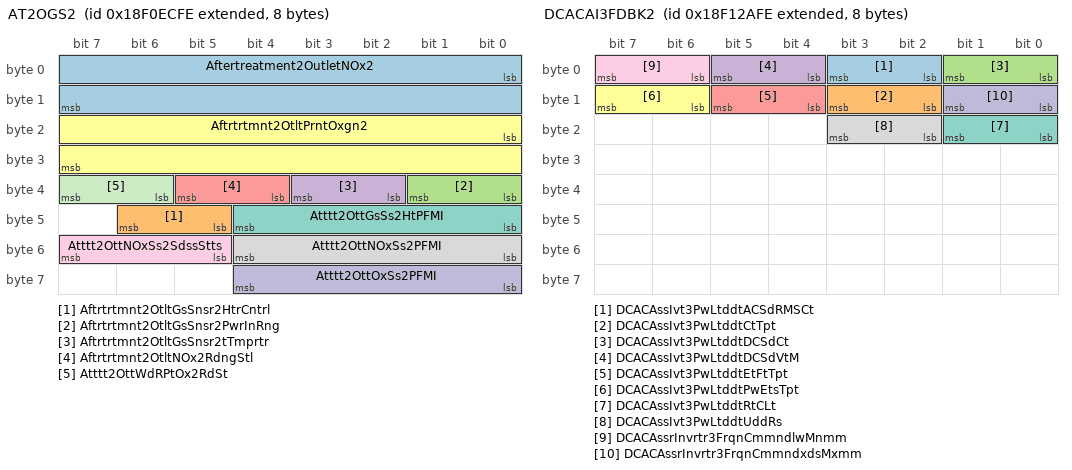
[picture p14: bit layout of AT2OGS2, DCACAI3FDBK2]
BO_ 2565926142 AT2OGS2: 8 Vector__XXX
 SG_ Aftertreatment2OutletNOx2 : 0|16@1+ (0.05,-200) [-200|3012.75] "ppm" Vector__XXX
 SG_ Aftrtrtmnt2OtltGsSnsr2HtrCntrl : 45|2@1+ (1,0) [0|3] "" Vector__XXX
 SG_ Aftrtrtmnt2OtltGsSnsr2PwrInRng : 32|2@1+ (1,0) [0|3] "" Vector__XXX
 SG_ Aftrtrtmnt2OtltGsSnsr2tTmprtr : 34|2@1+ (1,0) [0|3] "" Vector__XXX
 SG_ Aftrtrtmnt2OtltNOx2RdngStl : 36|2@1+ (1,0) [0|3] "" Vector__XXX
 SG_ Aftrtrtmnt2OtltPrntOxgn2 : 16|16@1+ (0.000514,-12) [-12|21.02707] "%" Vector__XXX
 SG_ Atttt2OttGsSs2HtPFMI : 40|5@1+ (1,0) [0|31] "binary" Vector__XXX
 SG_ Atttt2OttNOxSs2PFMI : 48|5@1+ (1,0) [0|31] "binary" Vector__XXX
 SG_ Atttt2OttNOxSs2SdssStts : 53|3@1+ (1,0) [0|7] "" Vector__XXX
 SG_ Atttt2OttOxSs2PFMI : 56|5@1+ (1,0) [0|31] "binary" Vector__XXX
 SG_ Atttt2OttWdRPtOx2RdSt : 38|2@1+ (1,0) [0|3] "" Vector__XXX

BO_ 2565932286 ESSI2: 8 Vector__XXX
 SG_ EngineSpeed4 : 0|16@1+ (0.5,0) [0|32127.5] "rpm" Vector__XXX

BO_ 2565932798 WSP1: 8 Vector__XXX
 SG_ WllStmltnPmpDshrgPrssr : 16|16@1+ (5,0) [0|321275] "kPa" Vector__XXX
 SG_ WllStmltnPmpStnPrssr : 0|16@1+ (0.1,-3212.7) [-3212.7|3212.8] "kPa" Vector__XXX

BO_ 2565933054 WSP2: 8 Vector__XXX
 SG_ WellStimulationPumpSpeed : 24|16@1+ (0.125,0) [0|8031.875] "rpm" Vector__XXX
 SG_ WllStmltnPmpGrBxOlPrssr : 0|16@1+ (0.1,0) [0|6425.5] "kPa" Vector__XXX
 SG_ WllStmltnPmpGrBxOlTmprtr : 16|8@1+ (1,-40) [-40|210] "degC" Vector__XXX

BO_ 2565934590 GFI6: 8 Vector__XXX
 SG_ EngnFlVlv2DffrntlPrssr : 0|16@1+ (0.1,0) [0|6425.5] "kPa" Vector__XXX

BO_ 2565942014 DCACAI3FDBK2: 8 Vector__XXX
 SG_ DCACAssIvt3PwLtddtACSdRMSCt : 2|2@1+ (1,0) [0|3] "" Vector__XXX
 SG_ DCACAssIvt3PwLtddtCtTpt : 10|2@1+ (1,0) [0|3] "" Vector__XXX
 SG_ DCACAssIvt3PwLtddtDCSdCt : 0|2@1+ (1,0) [0|3] "" Vector__XXX
 SG_ DCACAssIvt3PwLtddtDCSdVtM : 4|2@1+ (1,0) [0|3] "" Vector__XXX
 SG_ DCACAssIvt3PwLtddtEtFtTpt : 12|2@1+ (1,0) [0|3] "" Vector__XXX
 SG_ DCACAssIvt3PwLtddtPwEtsTpt : 14|2@1+ (1,0) [0|3] "" Vector__XXX
 SG_ DCACAssIvt3PwLtddtRtCLt : 16|2@1+ (1,0) [0|3] "" Vector__XXX
 SG_ DCACAssIvt3PwLtddtUddRs : 18|2@1+ (1,0) [0|3] "" Vector__XXX
 SG_ DCACAssrInvrtr3FrqnCmmndlwMnmm : 6|2@1+ (1,0) [0|3] "" Vector__XXX
 SG_ DCACAssrInvrtr3FrqnCmmndxdsMxmm : 8|2@1+ (1,0) [0|3] "" Vector__XXX

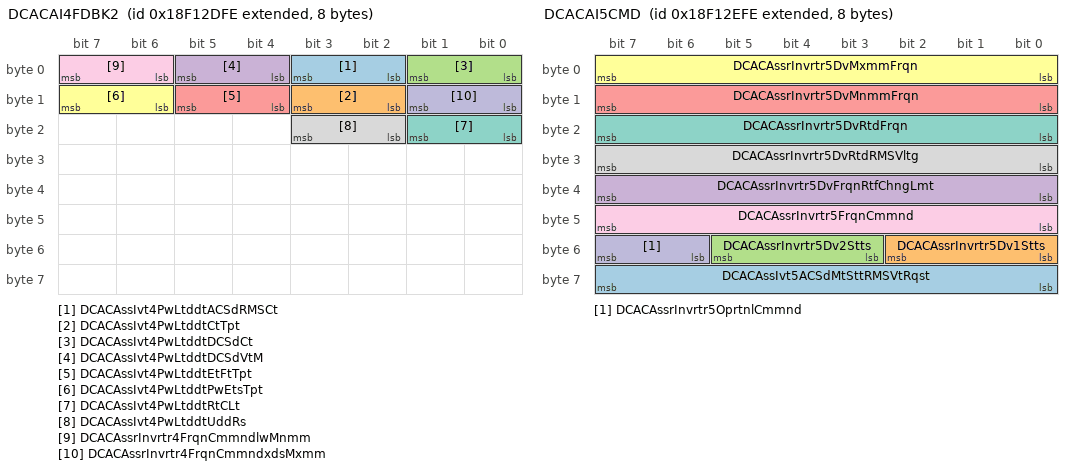
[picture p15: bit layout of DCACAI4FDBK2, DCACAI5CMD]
BO_ 2565942782 DCACAI4FDBK2: 8 Vector__XXX
 SG_ DCACAssIvt4PwLtddtACSdRMSCt : 2|2@1+ (1,0) [0|3] "" Vector__XXX
 SG_ DCACAssIvt4PwLtddtCtTpt : 10|2@1+ (1,0) [0|3] "" Vector__XXX
 SG_ DCACAssIvt4PwLtddtDCSdCt : 0|2@1+ (1,0) [0|3] "" Vector__XXX
 SG_ DCACAssIvt4PwLtddtDCSdVtM : 4|2@1+ (1,0) [0|3] "" Vector__XXX
 SG_ DCACAssIvt4PwLtddtEtFtTpt : 12|2@1+ (1,0) [0|3] "" Vector__XXX
 SG_ DCACAssIvt4PwLtddtPwEtsTpt : 14|2@1+ (1,0) [0|3] "" Vector__XXX
 SG_ DCACAssIvt4PwLtddtRtCLt : 16|2@1+ (1,0) [0|3] "" Vector__XXX
 SG_ DCACAssIvt4PwLtddtUddRs : 18|2@1+ (1,0) [0|3] "" Vector__XXX
 SG_ DCACAssrInvrtr4FrqnCmmndlwMnmm : 6|2@1+ (1,0) [0|3] "" Vector__XXX
 SG_ DCACAssrInvrtr4FrqnCmmndxdsMxmm : 8|2@1+ (1,0) [0|3] "" Vector__XXX

BO_ 2565943038 DCACAI5CMD: 8 Vector__XXX
 SG_ DCACAssIvt5ACSdMtSttRMSVtRqst : 56|8@1+ (2,0) [0|500] "Vrms" Vector__XXX
 SG_ DCACAssrInvrtr5Dv1Stts : 48|3@1+ (1,0) [0|7] "" Vector__XXX
 SG_ DCACAssrInvrtr5Dv2Stts : 51|3@1+ (1,0) [0|7] "" Vector__XXX
 SG_ DCACAssrInvrtr5DvFrqnRtfChngLmt : 32|8@1+ (2,0) [0|500] "Hz/s" Vector__XXX
 SG_ DCACAssrInvrtr5DvMnmmFrqn : 8|8@1+ (1,0) [0|250] "Hz" Vector__XXX
 SG_ DCACAssrInvrtr5DvMxmmFrqn : 0|8@1+ (1,0) [0|250] "Hz" Vector__XXX
 SG_ DCACAssrInvrtr5DvRtdFrqn : 16|8@1+ (1,0) [0|250] "Hz" Vector__XXX
 SG_ DCACAssrInvrtr5DvRtdRMSVltg : 24|8@1+ (2,0) [0|500] "Vrms" Vector__XXX
 SG_ DCACAssrInvrtr5FrqnCmmnd : 40|8@1+ (1,0) [0|250] "Hz" Vector__XXX
 SG_ DCACAssrInvrtr5OprtnlCmmnd : 54|2@1+ (1,0) [0|3] "" Vector__XXX

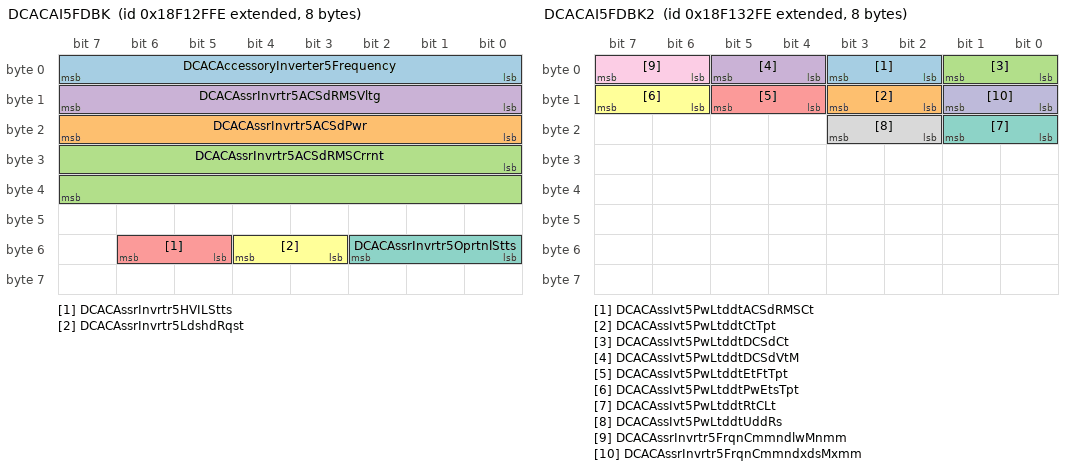
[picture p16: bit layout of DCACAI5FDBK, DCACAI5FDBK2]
BO_ 2565943294 DCACAI5FDBK: 8 Vector__XXX
 SG_ DCACAccessoryInverter5Frequency : 0|8@1+ (1,0) [0|250] "Hz" Vector__XXX
 SG_ DCACAssrInvrtr5ACSdPwr : 16|8@1+ (0.1,0) [0|25] "kW" Vector__XXX
 SG_ DCACAssrInvrtr5ACSdRMSCrrnt : 24|16@1+ (0.03125,0) [0|2007.96875] "Arms" Vector__XXX
 SG_ DCACAssrInvrtr5ACSdRMSVltg : 8|8@1+ (2,0) [0|500] "Vrms" Vector__XXX
 SG_ DCACAssrInvrtr5HVILStts : 53|2@1+ (1,0) [0|3] "" Vector__XXX
 SG_ DCACAssrInvrtr5LdshdRqst : 51|2@1+ (1,0) [0|3] "" Vector__XXX
 SG_ DCACAssrInvrtr5OprtnlStts : 48|3@1+ (1,0) [0|7] "" Vector__XXX

BO_ 2565944062 DCACAI5FDBK2: 8 Vector__XXX
 SG_ DCACAssIvt5PwLtddtACSdRMSCt : 2|2@1+ (1,0) [0|3] "" Vector__XXX
 SG_ DCACAssIvt5PwLtddtCtTpt : 10|2@1+ (1,0) [0|3] "" Vector__XXX
 SG_ DCACAssIvt5PwLtddtDCSdCt : 0|2@1+ (1,0) [0|3] "" Vector__XXX
 SG_ DCACAssIvt5PwLtddtDCSdVtM : 4|2@1+ (1,0) [0|3] "" Vector__XXX
 SG_ DCACAssIvt5PwLtddtEtFtTpt : 12|2@1+ (1,0) [0|3] "" Vector__XXX
 SG_ DCACAssIvt5PwLtddtPwEtsTpt : 14|2@1+ (1,0) [0|3] "" Vector__XXX
 SG_ DCACAssIvt5PwLtddtRtCLt : 16|2@1+ (1,0) [0|3] "" Vector__XXX
 SG_ DCACAssIvt5PwLtddtUddRs : 18|2@1+ (1,0) [0|3] "" Vector__XXX
 SG_ DCACAssrInvrtr5FrqnCmmndlwMnmm : 6|2@1+ (1,0) [0|3] "" Vector__XXX
 SG_ DCACAssrInvrtr5FrqnCmmndxdsMxmm : 8|2@1+ (1,0) [0|3] "" Vector__XXX

BO_ 2566624510 EEC22: 8 Vector__XXX
 SG_ EngnExhstGsRrltn1ClrIntkPrssr : 0|16@1+ (5,0) [0|321275] "kPa" Vector__XXX

BO_ 2566624766 HOURS2: 8 Vector__XXX
 SG_ EngnIdlMngmntAtvTtlTm : 0|32@1+ (0.05,0) [0|210554060.75] "h" Vector__XXX

BO_ 2566625022 EI3: 8 Vector__XXX
 SG_ InstntnsEstmtdEngnPwrRtLmt : 0|16@1+ (0.125,0) [0|8031.875] "kW/s" Vector__XXX

BO_ 2566625278 VEP15: 8 Vector__XXX
 SG_ SLIBttrPk1Bttr1CptSttng : 0|16@1+ (1,0) [0|64255] "Ah" Vector__XXX
 SG_ SLIBttrPk1Bttr2CptSttng : 16|16@1+ (1,0) [0|64255] "Ah" Vector__XXX
 SG_ SLIBttrPk1Bttr3CptSttng : 32|16@1+ (1,0) [0|64255] "Ah" Vector__XXX
 SG_ SLIBttrPk1Bttr4CptSttng : 48|16@1+ (1,0) [0|64255] "Ah" Vector__XXX

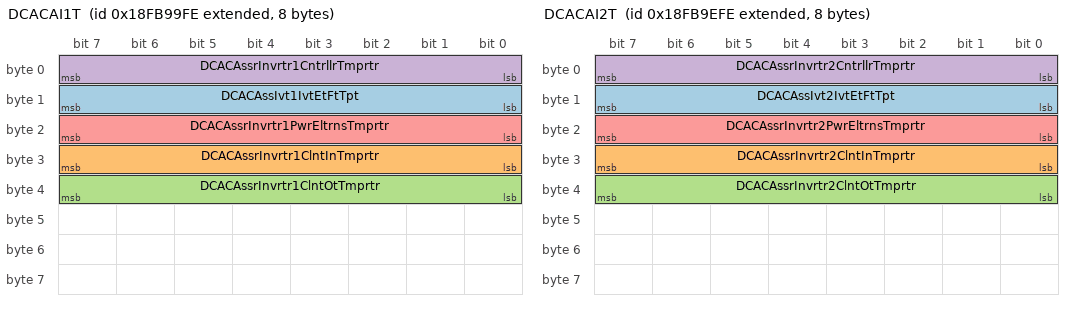
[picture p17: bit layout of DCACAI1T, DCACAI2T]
BO_ 2566625790 DCACAI1T: 8 Vector__XXX
 SG_ DCACAssIvt1IvtEtFtTpt : 8|8@1+ (1,-40) [-40|210] "degC" Vector__XXX
 SG_ DCACAssrInvrtr1ClntInTmprtr : 24|8@1+ (1,-40) [-40|210] "degC" Vector__XXX
 SG_ DCACAssrInvrtr1ClntOtTmprtr : 32|8@1+ (1,-40) [-40|210] "degC" Vector__XXX
 SG_ DCACAssrInvrtr1CntrllrTmprtr : 0|8@1+ (1,-40) [-40|210] "degC" Vector__XXX
 SG_ DCACAssrInvrtr1PwrEltrnsTmprtr : 16|8@1+ (1,-40) [-40|210] "degC" Vector__XXX

BO_ 2566626558 DCACAI1CFG1: 13 Vector__XXX
 SG_ DCACAssIvt1ACSdDtFqCdStt : 96|8@1+ (1,0) [0|250] "Hz" Vector__XXX
 SG_ DCACAssIvt1ACSdRMSCtMxLtStt : 48|16@1+ (0.03125,0) [0|2007.96875] "Arms" Vector__XXX
 SG_ DCACAssIvt1ACSdRMSVtMxLtStt : 32|16@1+ (0.03125,0) [0|2007.96875] "Vrms" Vector__XXX
 SG_ DCACAssIvt1DCSdCtMLtStt : 80|16@1+ (0.05,-3212.75) [-3212.75|0] "A" Vector__XXX
 SG_ DCACAssIvt1DCSdCtMxLtStt : 16|16@1+ (0.05,0) [0|3212.75] "A" Vector__XXX
 SG_ DCACAssIvt1DCSdVtMLtStt : 0|16@1+ (0.05,0) [0|3212.75] "V" Vector__XXX
 SG_ DCACAssIvt1DCSdVtMxLtStt : 64|16@1+ (0.05,0) [0|3212.75] "V" Vector__XXX

BO_ 2566626814 DCACAI1LD: 8 Vector__XXX
 SG_ DCACAssrInvrtr1TtlDCInptChrg : 0|32@1+ (100,0) [0|4E+11] "Ah" Vector__XXX
 SG_ DCACAssrInvrtr1TtlDCInptEnrg : 32|32@1+ (100,0) [0|4E+11] "Watt-hour" Vector__XXX

BO_ 2566627070 DCACAI2T: 8 Vector__XXX
 SG_ DCACAssIvt2IvtEtFtTpt : 8|8@1+ (1,-40) [-40|210] "degC" Vector__XXX
 SG_ DCACAssrInvrtr2ClntInTmprtr : 24|8@1+ (1,-40) [-40|210] "degC" Vector__XXX
 SG_ DCACAssrInvrtr2ClntOtTmprtr : 32|8@1+ (1,-40) [-40|210] "degC" Vector__XXX
 SG_ DCACAssrInvrtr2CntrllrTmprtr : 0|8@1+ (1,-40) [-40|210] "degC" Vector__XXX
 SG_ DCACAssrInvrtr2PwrEltrnsTmprtr : 16|8@1+ (1,-40) [-40|210] "degC" Vector__XXX

BO_ 2566627838 DCACAI2CFG1: 13 Vector__XXX
 SG_ DCACAssIvt2ACSdDtFqCdStt : 96|8@1+ (1,0) [0|250] "Hz" Vector__XXX
 SG_ DCACAssIvt2ACSdRMSCtMxLtStt : 48|16@1+ (0.03125,0) [0|2007.96875] "Arms" Vector__XXX
 SG_ DCACAssIvt2ACSdRMSVtMxLtStt : 32|16@1+ (0.03125,0) [0|2007.96875] "Vrms" Vector__XXX
 SG_ DCACAssIvt2DCSdCtMLtStt : 80|16@1+ (0.05,-3212.75) [-3212.75|0] "A" Vector__XXX
 SG_ DCACAssIvt2DCSdCtMxLtStt : 16|16@1+ (0.05,0) [0|3212.75] "A" Vector__XXX
 SG_ DCACAssIvt2DCSdVtMLtStt : 0|16@1+ (0.05,0) [0|3212.75] "V" Vector__XXX
 SG_ DCACAssIvt2DCSdVtMxLtStt : 64|16@1+ (0.05,0) [0|3212.75] "V" Vector__XXX

BO_ 2566628094 DCACAI2LD: 8 Vector__XXX
 SG_ DCACAssrInvrtr2TtlDCInptChrg : 0|32@1+ (100,0) [0|4E+11] "Ah" Vector__XXX
 SG_ DCACAssrInvrtr2TtlDCInptEnrg : 32|32@1+ (100,0) [0|4E+11] "Watt-hour" Vector__XXX

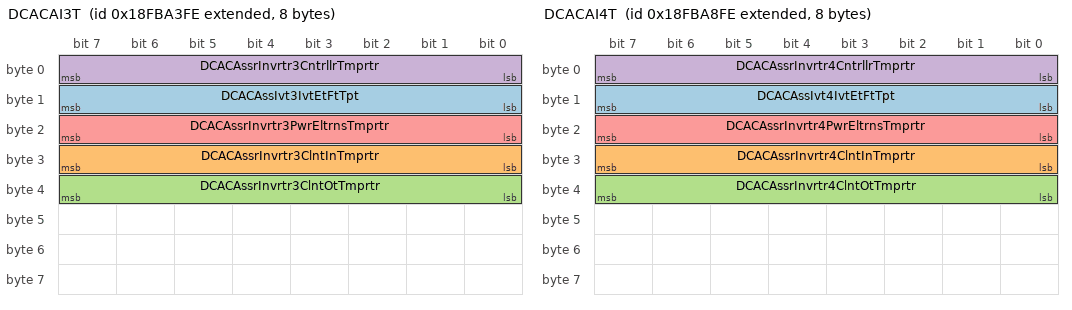
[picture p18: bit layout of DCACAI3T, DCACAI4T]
BO_ 2566628350 DCACAI3T: 8 Vector__XXX
 SG_ DCACAssIvt3IvtEtFtTpt : 8|8@1+ (1,-40) [-40|210] "degC" Vector__XXX
 SG_ DCACAssrInvrtr3ClntInTmprtr : 24|8@1+ (1,-40) [-40|210] "degC" Vector__XXX
 SG_ DCACAssrInvrtr3ClntOtTmprtr : 32|8@1+ (1,-40) [-40|210] "degC" Vector__XXX
 SG_ DCACAssrInvrtr3CntrllrTmprtr : 0|8@1+ (1,-40) [-40|210] "degC" Vector__XXX
 SG_ DCACAssrInvrtr3PwrEltrnsTmprtr : 16|8@1+ (1,-40) [-40|210] "degC" Vector__XXX

BO_ 2566629118 DCACAI3CFG1: 13 Vector__XXX
 SG_ DCACAssIvt3ACSdDtFqCdStt : 96|8@1+ (1,0) [0|250] "Hz" Vector__XXX
 SG_ DCACAssIvt3ACSdRMSCtMxLtStt : 48|16@1+ (0.03125,0) [0|2007.96875] "Arms" Vector__XXX
 SG_ DCACAssIvt3ACSdRMSVtMxLtStt : 32|16@1+ (0.03125,0) [0|2007.96875] "Vrms" Vector__XXX
 SG_ DCACAssIvt3DCSdCtMLtStt : 80|16@1+ (0.05,-3212.75) [-3212.75|0] "A" Vector__XXX
 SG_ DCACAssIvt3DCSdCtMxLtStt : 16|16@1+ (0.05,0) [0|3212.75] "A" Vector__XXX
 SG_ DCACAssIvt3DCSdVtMLtStt : 0|16@1+ (0.05,0) [0|3212.75] "V" Vector__XXX
 SG_ DCACAssIvt3DCSdVtMxLtStt : 64|16@1+ (0.05,0) [0|3212.75] "V" Vector__XXX

BO_ 2566629374 DCACAI3LD: 8 Vector__XXX
 SG_ DCACAssrInvrtr3TtlDCInptChrg : 0|32@1+ (100,0) [0|4E+11] "Ah" Vector__XXX
 SG_ DCACAssrInvrtr3TtlDCInptEnrg : 32|32@1+ (100,0) [0|4E+11] "Watt-hour" Vector__XXX

BO_ 2566629630 DCACAI4T: 8 Vector__XXX
 SG_ DCACAssIvt4IvtEtFtTpt : 8|8@1+ (1,-40) [-40|210] "degC" Vector__XXX
 SG_ DCACAssrInvrtr4ClntInTmprtr : 24|8@1+ (1,-40) [-40|210] "degC" Vector__XXX
 SG_ DCACAssrInvrtr4ClntOtTmprtr : 32|8@1+ (1,-40) [-40|210] "degC" Vector__XXX
 SG_ DCACAssrInvrtr4CntrllrTmprtr : 0|8@1+ (1,-40) [-40|210] "degC" Vector__XXX
 SG_ DCACAssrInvrtr4PwrEltrnsTmprtr : 16|8@1+ (1,-40) [-40|210] "degC" Vector__XXX

BO_ 2566630398 DCACAI4CFG1: 13 Vector__XXX
 SG_ DCACAssIvt4ACSdDtFqCdStt : 96|8@1+ (1,0) [0|250] "Hz" Vector__XXX
 SG_ DCACAssIvt4ACSdRMSCtMxLtStt : 48|16@1+ (0.03125,0) [0|2007.96875] "Arms" Vector__XXX
 SG_ DCACAssIvt4ACSdRMSVtMxLtStt : 32|16@1+ (0.03125,0) [0|2007.96875] "Vrms" Vector__XXX
 SG_ DCACAssIvt4DCSdCtMLtStt : 80|16@1+ (0.05,-3212.75) [-3212.75|0] "A" Vector__XXX
 SG_ DCACAssIvt4DCSdCtMxLtStt : 16|16@1+ (0.05,0) [0|3212.75] "A" Vector__XXX
 SG_ DCACAssIvt4DCSdVtMLtStt : 0|16@1+ (0.05,0) [0|3212.75] "V" Vector__XXX
 SG_ DCACAssIvt4DCSdVtMxLtStt : 64|16@1+ (0.05,0) [0|3212.75] "V" Vector__XXX

BO_ 2566630654 DCACAI4LD: 8 Vector__XXX
 SG_ DCACAssrInvrtr4TtlDCInptChrg : 0|32@1+ (100,0) [0|4E+11] "Ah" Vector__XXX
 SG_ DCACAssrInvrtr4TtlDCInptEnrg : 32|32@1+ (100,0) [0|4E+11] "Watt-hour" Vector__XXX

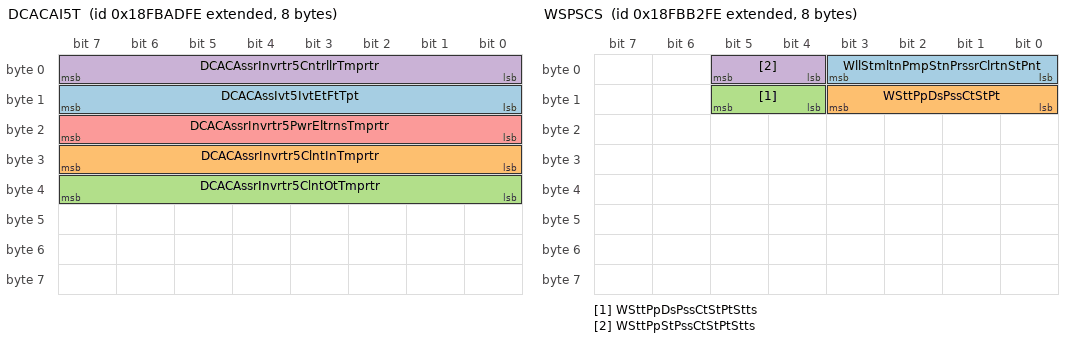
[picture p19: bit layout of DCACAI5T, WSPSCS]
BO_ 2566630910 DCACAI5T: 8 Vector__XXX
 SG_ DCACAssIvt5IvtEtFtTpt : 8|8@1+ (1,-40) [-40|210] "degC" Vector__XXX
 SG_ DCACAssrInvrtr5ClntInTmprtr : 24|8@1+ (1,-40) [-40|210] "degC" Vector__XXX
 SG_ DCACAssrInvrtr5ClntOtTmprtr : 32|8@1+ (1,-40) [-40|210] "degC" Vector__XXX
 SG_ DCACAssrInvrtr5CntrllrTmprtr : 0|8@1+ (1,-40) [-40|210] "degC" Vector__XXX
 SG_ DCACAssrInvrtr5PwrEltrnsTmprtr : 16|8@1+ (1,-40) [-40|210] "degC" Vector__XXX

BO_ 2566631678 DCACAI5CFG1: 13 Vector__XXX
 SG_ DCACAssIvt5ACSdDtFqCdStt : 96|8@1+ (1,0) [0|250] "Hz" Vector__XXX
 SG_ DCACAssIvt5ACSdRMSCtMxLtStt : 48|16@1+ (0.03125,0) [0|2007.96875] "Arms" Vector__XXX
 SG_ DCACAssIvt5ACSdRMSVtMxLtStt : 32|16@1+ (0.03125,0) [0|2007.96875] "Vrms" Vector__XXX
 SG_ DCACAssIvt5DCSdCtMLtStt : 80|16@1+ (0.05,-3212.75) [-3212.75|0] "A" Vector__XXX
 SG_ DCACAssIvt5DCSdCtMxLtStt : 16|16@1+ (0.05,0) [0|3212.75] "A" Vector__XXX
 SG_ DCACAssIvt5DCSdVtMLtStt : 0|16@1+ (0.05,0) [0|3212.75] "V" Vector__XXX
 SG_ DCACAssIvt5DCSdVtMxLtStt : 64|16@1+ (0.05,0) [0|3212.75] "V" Vector__XXX

BO_ 2566631934 DCACAI5LD: 8 Vector__XXX
 SG_ DCACAssrInvrtr5TtlDCInptChrg : 0|32@1+ (100,0) [0|4E+11] "Ah" Vector__XXX
 SG_ DCACAssrInvrtr5TtlDCInptEnrg : 32|32@1+ (100,0) [0|4E+11] "Watt-hour" Vector__XXX

BO_ 2566632190 WSPSCS: 8 Vector__XXX
 SG_ WllStmltnPmpStnPrssrClrtnStPnt : 0|4@1+ (1,0) [0|15] "" Vector__XXX
 SG_ WSttPpDsPssCtStPt : 8|4@1+ (1,0) [0|15] "" Vector__XXX
 SG_ WSttPpDsPssCtStPtStts : 12|2@1+ (1,0) [0|3] "" Vector__XXX
 SG_ WSttPpStPssCtStPtStts : 4|2@1+ (1,0) [0|3] "" Vector__XXX

BO_ 2566632446 WSPFV: 8 Vector__XXX
 SG_ WllStmltnPmpTrpFldPmpd : 32|32@1+ (0.5,0) [0|2105540607.5] "l" Vector__XXX
 SG_ WllStmltnPmpTtlFldPmpd : 0|32@1+ (0.5,0) [0|2105540607.5] "l" Vector__XXX

BO_ 2566632702 WSPSN: 200 Vector__XXX
 SG_ WllStmltnPmpFldEndSrlNmr : 8|8@1+ (1,0) [0|255] "ASCII" Vector__XXX
 SG_ WllStmltnPmpPwrEndSrlNmr : 0|8@1+ (1,0) [0|255] "ASCII" Vector__XXX

BO_ 2566632958 WSPH2: 8 Vector__XXX
 SG_ WllStmltnPmpFldEndTrpHrs : 0|32@1+ (1,0) [0|4.21108E+09] "s" Vector__XXX
 SG_ WllStmltnPmpPwrEndTrpHrs : 32|32@1+ (1,0) [0|4.21108E+09] "s" Vector__XXX

BO_ 2566633214 AT1OG4: 8 Vector__XXX
 SG_ Aftrtrtmnt1OtltOxgnPmpngCrrnt : 0|16@1+ (0.001,-32.127) [-32.127|32.128] "mA" Vector__XXX

BO_ 2566633470 AT1IG4: 8 Vector__XXX
 SG_ Aftrtrtmnt1IntkOxgnPmpngCrrnt : 0|16@1+ (0.001,-32.127) [-32.127|32.128] "mA" Vector__XXX

BO_ 2566633726 DCDC4LD: 16 Vector__XXX
 SG_ DCDC4TotalHighSideCharge : 64|32@1+ (100,0) [0|4E+11] "Ah" Vector__XXX
 SG_ DCDC4TotalHighSideEnergy : 0|32@1+ (100,0) [0|4E+11] "Watt-hour" Vector__XXX
 SG_ DCDC4TotalLowSideCharge : 96|32@1+ (100,0) [0|4E+11] "Ah" Vector__XXX
 SG_ DCDC4TotalLowSideEnergy : 32|32@1+ (100,0) [0|4E+11] "Watt-hour" Vector__XXX

BO_ 2566633982 DCDC4CFG1: 19 Vector__XXX
 SG_ DCDC4HghSdCrrntMxmmLmtSttng : 32|16@1+ (0.05,0) [0|3212.75] "A" Vector__XXX
 SG_ DCDC4HghSdVltgMnmmLmtSttng : 0|16@1+ (0.05,0) [0|3212.75] "V" Vector__XXX
 SG_ DCDC4HghSdVltgMxmmLmtSttng : 16|16@1+ (0.05,0) [0|3212.75] "V" Vector__XXX
 SG_ DCDC4LwSdCrrntMxmmLmtSttng : 80|16@1+ (0.05,0) [0|3212.75] "A" Vector__XXX
 SG_ DCDC4LwSdVltgBkDfltSttng : 136|16@1+ (0.01,0) [0|642.55] "V" Vector__XXX
 SG_ DCDC4LwSdVltgMnmmLmtSttng : 48|16@1+ (0.01,0) [0|642.55] "V" Vector__XXX
 SG_ DCDC4LwSdVltgMxmmLmtSttng : 64|16@1+ (0.01,0) [0|642.55] "V" Vector__XXX
 SG_ DCDC4SLIBttrTmprtrMxmmLmtSttng : 128|8@1+ (1,-40) [-40|210] "degC" Vector__XXX
 SG_ DCDC4SLIBttTCCtMxLtStt : 112|16@1+ (0.05,0) [0|3212.75] "A" Vector__XXX
 SG_ DCDC4SLIBttTVtMxLtStt : 96|16@1+ (0.01,0) [0|642.55] "V" Vector__XXX

BO_ 2566635262 DCDC3LD: 16 Vector__XXX
 SG_ DCDC3TotalHighSideCharge : 64|32@1+ (100,0) [0|4E+11] "Ah" Vector__XXX
 SG_ DCDC3TotalHighSideEnergy : 0|32@1+ (100,0) [0|4E+11] "Watt-hour" Vector__XXX
 SG_ DCDC3TotalLowSideCharge : 96|32@1+ (100,0) [0|4E+11] "Ah" Vector__XXX
 SG_ DCDC3TotalLowSideEnergy : 32|32@1+ (100,0) [0|4E+11] "Watt-hour" Vector__XXX

BO_ 2566635518 DCDC3CFG1: 19 Vector__XXX
 SG_ DCDC3HghSdCrrntMxmmLmtSttng : 32|16@1+ (0.05,0) [0|3212.75] "A" Vector__XXX
 SG_ DCDC3HghSdVltgMnmmLmtSttng : 0|16@1+ (0.05,0) [0|3212.75] "V" Vector__XXX
 SG_ DCDC3HghSdVltgMxmmLmtSttng : 16|16@1+ (0.05,0) [0|3212.75] "V" Vector__XXX
 SG_ DCDC3LwSdCrrntMxmmLmtSttng : 80|16@1+ (0.05,0) [0|3212.75] "A" Vector__XXX
 SG_ DCDC3LwSdVltgBkDfltSttng : 136|16@1+ (0.01,0) [0|642.55] "V" Vector__XXX
 SG_ DCDC3LwSdVltgMnmmLmtSttng : 48|16@1+ (0.01,0) [0|642.55] "V" Vector__XXX
 SG_ DCDC3LwSdVltgMxmmLmtSttng : 64|16@1+ (0.01,0) [0|642.55] "V" Vector__XXX
 SG_ DCDC3SLIBttrTmprtrMxmmLmtSttng : 128|8@1+ (1,-40) [-40|210] "degC" Vector__XXX
 SG_ DCDC3SLIBttTCCtMxLtStt : 112|16@1+ (0.05,0) [0|3212.75] "A" Vector__XXX
 SG_ DCDC3SLIBttTVtMxLtStt : 96|16@1+ (0.01,0) [0|642.55] "V" Vector__XXX

BO_ 2566636798 DCDC2LD: 16 Vector__XXX
 SG_ DCDC2TotalHighSideCharge : 64|32@1+ (100,0) [0|4E+11] "Ah" Vector__XXX
 SG_ DCDC2TotalHighSideEnergy : 0|32@1+ (100,0) [0|4E+11] "Watt-hour" Vector__XXX
 SG_ DCDC2TotalLowSideCharge : 96|32@1+ (100,0) [0|4E+11] "Ah" Vector__XXX
 SG_ DCDC2TotalLowSideEnergy : 32|32@1+ (100,0) [0|4E+11] "Watt-hour" Vector__XXX

BO_ 2566637054 DCDC2CFG1: 19 Vector__XXX
 SG_ DCDC2HghSdCrrntMxmmLmtSttng : 32|16@1+ (0.05,0) [0|3212.75] "A" Vector__XXX
 SG_ DCDC2HghSdVltgMnmmLmtSttng : 0|16@1+ (0.05,0) [0|3212.75] "V" Vector__XXX
 SG_ DCDC2HghSdVltgMxmmLmtSttng : 16|16@1+ (0.05,0) [0|3212.75] "V" Vector__XXX
 SG_ DCDC2LwSdCrrntMxmmLmtSttng : 80|16@1+ (0.05,0) [0|3212.75] "A" Vector__XXX
 SG_ DCDC2LwSdVltgBkDfltSttng : 136|16@1+ (0.01,0) [0|642.55] "V" Vector__XXX
 SG_ DCDC2LwSdVltgMnmmLmtSttng : 48|16@1+ (0.01,0) [0|642.55] "V" Vector__XXX
 SG_ DCDC2LwSdVltgMxmmLmtSttng : 64|16@1+ (0.01,0) [0|642.55] "V" Vector__XXX
 SG_ DCDC2SLIBttrTmprtrMxmmLmtSttng : 128|8@1+ (1,-40) [-40|210] "degC" Vector__XXX
 SG_ DCDC2SLIBttTCCtMxLtStt : 112|16@1+ (0.05,0) [0|3212.75] "A" Vector__XXX
 SG_ DCDC2SLIBttTVtMxLtStt : 96|16@1+ (0.01,0) [0|642.55] "V" Vector__XXX

BO_ 2566638590 EEPCSI: 8 Vector__XXX
 SG_ ExhstPrtltCntrlSstmDgnstCnt : 32|32@1+ (1,0) [0|4.21108E+09] "count" Vector__XXX
 SG_ ExhstPrtltCntrlSstmDgnstTm : 0|32@1+ (1,0) [0|4.21108E+09] "s" Vector__XXX

BO_ 2566638846 WSPH: 16 Vector__XXX
 SG_ WllStmltnPmpMntnnIntrvlHrs : 0|32@1+ (1,0) [0|4.21108E+09] "s" Vector__XXX
 SG_ WllStmltnPmpPkngOprtnHrs : 64|32@1+ (1,0) [0|4.21108E+09] "s" Vector__XXX
 SG_ WllStmltnPmpVlvOprtnHrs : 32|32@1+ (1,0) [0|4.21108E+09] "s" Vector__XXX
 SG_ WllStmltnPmpVlvStOprtnHrs : 96|32@1+ (1,0) [0|4.21108E+09] "s" Vector__XXX

BO_ 2566639102 WSPT2: 19 Vector__XXX
 SG_ WllStmltnPmpPlngrFrngOrdrSttng : 144|4@1+ (1,0) [0|15] "" Vector__XXX
 SG_ WllStmltnPmpRdLdHghThrshldSttng : 128|16@1+ (5,0) [0|321275] "kN" Vector__XXX
 SG_ WSttPpCstSpdHTsdStt : 112|16@1+ (0.125,0) [0|8031.875] "rpm" Vector__XXX
 SG_ WSttPpCstSpdLwTsdStt : 96|16@1+ (0.125,0) [0|8031.875] "rpm" Vector__XXX
 SG_ WSttPpDsPssHTsdStt : 80|16@1+ (5,0) [0|321275] "kPa" Vector__XXX
 SG_ WSttPpGBxOPssHTsdStt : 16|16@1+ (0.1,0) [0|6425.5] "kPa" Vector__XXX
 SG_ WSttPpGBxOPssLwTsdStt : 0|16@1+ (0.1,0) [0|6425.5] "kPa" Vector__XXX
 SG_ WSttPpGBxOTptHTsdStt : 40|8@1+ (1,-40) [-40|210] "degC" Vector__XXX
 SG_ WSttPpGBxOTptLwTsdStt : 32|8@1+ (1,-40) [-40|210] "degC" Vector__XXX
 SG_ WSttPpStPssHTsdStt : 64|16@1+ (0.1,-3212.7) [-3212.7|3212.8] "kPa" Vector__XXX
 SG_ WSttPpStPssLwTsdStt : 48|16@1+ (0.1,-3212.7) [-3212.7|3212.8] "kPa" Vector__XXX

BO_ 2566639614 DCDC1LD: 16 Vector__XXX
 SG_ DCDC1TotalHighSideCharge : 64|32@1+ (100,0) [0|4E+11] "Ah" Vector__XXX
 SG_ DCDC1TotalHighSideEnergy : 0|32@1+ (100,0) [0|4E+11] "Watt-hour" Vector__XXX
 SG_ DCDC1TotalLowSideCharge : 96|32@1+ (100,0) [0|4E+11] "Ah" Vector__XXX
 SG_ DCDC1TotalLowSideEnergy : 32|32@1+ (100,0) [0|4E+11] "Watt-hour" Vector__XXX

BO_ 2566639870 DCDC1CFG1: 19 Vector__XXX
 SG_ DCDC1HghSdCrrntMxmmLmtSttng : 32|16@1+ (0.05,0) [0|3212.75] "A" Vector__XXX
 SG_ DCDC1HghSdVltgMnmmLmtSttng : 0|16@1+ (0.05,0) [0|3212.75] "V" Vector__XXX
 SG_ DCDC1HghSdVltgMxmmLmtSttng : 16|16@1+ (0.05,0) [0|3212.75] "V" Vector__XXX
 SG_ DCDC1LwSdCrrntMxmmLmtSttng : 80|16@1+ (0.05,0) [0|3212.75] "A" Vector__XXX
 SG_ DCDC1LwSdVltgBkDfltSttng : 136|16@1+ (0.01,0) [0|642.55] "V" Vector__XXX
 SG_ DCDC1LwSdVltgMnmmLmtSttng : 48|16@1+ (0.01,0) [0|642.55] "V" Vector__XXX
 SG_ DCDC1LwSdVltgMxmmLmtSttng : 64|16@1+ (0.01,0) [0|642.55] "V" Vector__XXX
 SG_ DCDC1SLIBttrTmprtrMxmmLmtSttng : 128|8@1+ (1,-40) [-40|210] "degC" Vector__XXX
 SG_ DCDC1SLIBttTCCtMxLtStt : 112|16@1+ (0.05,0) [0|3212.75] "A" Vector__XXX
 SG_ DCDC1SLIBttTVtMxLtStt : 96|16@1+ (0.01,0) [0|642.55] "V" Vector__XXX

BO_ 2566640382 POM: 8 Vector__XXX
 SG_ WellStimulationPumpOilDensity : 16|16@1+ (0.00003052,0) [0|1.961] "g/cc" Vector__XXX
 SG_ WellStimulationPumpOilViscosity : 0|16@1+ (0.015625,0) [0|1003.984375] "Cp" Vector__XXX
 SG_ WllStmltnPmpOlRltvDltrt : 32|16@1+ (0.0001220703125,0) [0|7.844] "" Vector__XXX
 SG_ WllStmltnPmpOlTmprtr : 48|16@1+ (0.03125,-273) [-273|1734.96875] "degC" Vector__XXX

BO_ 2566641150 ACOCF2: 8 Vector__XXX
 SG_ AltrntrBrngHdrIntkPrssr : 0|8@1+ (2,0) [0|500] "kPa" Vector__XXX
 SG_ AltrntrOlClrDshrgPmpPrssr : 8|8@1+ (2,0) [0|500] "kPa" Vector__XXX
 SG_ EngnOlClrDshrgPmpPrssr : 16|8@1+ (2,0) [0|500] "kPa" Vector__XXX
 SG_ EngnOlClrIntkTmprtr : 24|8@1+ (1,-40) [-40|210] "degC" Vector__XXX

BO_ 2566641406 EEC21: 8 Vector__XXX
 SG_ EngnExhstMnfldAsltPrssr1 : 0|16@1+ (0.1,0) [0|6425.5] "kPa" Vector__XXX
 SG_ EngnExhstMnfldAsltPrssr2 : 16|16@1+ (0.1,0) [0|6425.5] "kPa" Vector__XXX

CM_ BO_ 2561146622 "Auxiliary Input/Output Status 2";
CM_ SG_ 2561146622 AuxiliaryIO17 "Identifies the current status of auxiliary input/output functions that are configured uniquely per application.00b = Auxiliary channel off01b = Auxiliary channe…";
CM_ SG_ 2561146622 AuxiliaryIO18 "Identifies the current status of auxiliary input/output functions that are configured uniquely per application.00b = Auxiliary channel off01b = Auxiliary channe…";
CM_ SG_ 2561146622 AuxiliaryIO19 "Identifies the current status of auxiliary input/output functions that are configured uniquely per application.00b = Auxiliary channel off01b = Auxiliary channe…";
CM_ SG_ 2561146622 AuxiliaryIO20 "Identifies the current status of auxiliary input/output functions that are configured uniquely per application.00b = Auxiliary channel off01b = Auxiliary channe…";
CM_ SG_ 2561146622 AuxiliaryIO21 "Identifies the current status of auxiliary input/output functions that are configured uniquely per application.00b = Auxiliary channel off01b = Auxiliary channe…";
CM_ SG_ 2561146622 AuxiliaryIO22 "Identifies the current status of auxiliary input/output functions that are configured uniquely per application.00b = Auxiliary channel off01b = Auxiliary channe…";
CM_ SG_ 2561146622 AuxiliaryIO23 "Identifies the current status of auxiliary input/output functions that are configured uniquely per application.00b = Auxiliary channel off01b = Auxiliary channe…";
CM_ SG_ 2561146622 AuxiliaryIO24 "Identifies the current status of auxiliary input/output functions that are configured uniquely per application.00b = Auxiliary channel off01b = Auxiliary channe…";
CM_ SG_ 2561146622 AuxiliaryIO25 "Identifies the current status of auxiliary input/output functions that are configured uniquely per application.00b = Auxiliary channel off01b = Auxiliary channe…";
CM_ SG_ 2561146622 AuxiliaryIO26 "Identifies the current status of auxiliary input/output functions that are configured uniquely per application.00b = Auxiliary channel off01b = Auxiliary channe…";
CM_ SG_ 2561146622 AuxiliaryIO27 "Identifies the current status of auxiliary input/output functions that are configured uniquely per application.00b = Auxiliary channel off01b = Auxiliary channe…";
CM_ SG_ 2561146622 AuxiliaryIO28 "Identifies the current status of auxiliary input/output functions that are configured uniquely per application.00b = Auxiliary channel off01b = Auxiliary channe…";
CM_ SG_ 2561146622 AuxiliaryIO29 "Identifies the current status of auxiliary input/output functions that are configured uniquely per application.00b = Auxiliary channel off01b = Auxiliary channe…";
CM_ SG_ 2561146622 AuxiliaryIO30 "Identifies the current status of auxiliary input/output functions that are configured uniquely per application.00b = Auxiliary channel off01b = Auxiliary channe…";
CM_ SG_ 2561146622 AuxiliaryIO31 "Identifies the current status of auxiliary input/output functions that are configured uniquely per application.00b = Auxiliary channel off01b = Auxiliary channe…";
CM_ SG_ 2561146622 AuxiliaryIO32 "Identifies the current status of auxiliary input/output functions that are configured uniquely per application.00b = Auxiliary channel off01b = Auxiliary channe…";
CM_ SG_ 2561146622 AuxiliaryIO33 "Identifies the current status of auxiliary input/output functions that are configured uniquely per application.00b = Auxiliary channel off01b = Auxiliary channe…";
CM_ SG_ 2561146622 AuxiliaryIO34 "Identifies the current status of auxiliary input/output functions that are configured uniquely per application.00b = Auxiliary channel off01b = Auxiliary channe…";
CM_ SG_ 2561146622 AuxiliaryIO35 "Identifies the current status of auxiliary input/output functions that are configured uniquely per application.00b = Auxiliary channel off01b = Auxiliary channe…";
CM_ SG_ 2561146622 AuxiliaryIO36 "Identifies the current status of auxiliary input/output functions that are configured uniquely per application.00b = Auxiliary channel off01b = Auxiliary channe…";
CM_ SG_ 2561146622 AuxiliaryIO37 "Identifies the current status of auxiliary input/output functions that are configured uniquely per application.00b = Auxiliary channel off01b = Auxiliary channe…";
CM_ SG_ 2561146622 AuxiliaryIO38 "Identifies the current status of auxiliary input/output functions that are configured uniquely per application.00b = Auxiliary channel off01b = Auxiliary channe…";
CM_ SG_ 2561146622 AuxiliaryIO39 "Identifies the current status of auxiliary input/output functions that are configured uniquely per application.00b = Auxiliary channel off01b = Auxiliary channe…";
CM_ SG_ 2561146622 AuxiliaryIO40 "Identifies the current status of auxiliary input/output functions that are configured uniquely per application.00b = Auxiliary channel off01b = Auxiliary channe…";
CM_ SG_ 2561146622 AuxiliaryIO41 "Identifies the current status of auxiliary input/output functions that are configured uniquely per application.00b = Auxiliary channel off01b = Auxiliary channe…";
CM_ SG_ 2561146622 AuxiliaryIO42 "Identifies the current status of auxiliary input/output functions that are configured uniquely per application.00b = Auxiliary channel off01b = Auxiliary channe…";
CM_ SG_ 2561146622 AuxiliaryIO43 "Identifies the current status of auxiliary input/output functions that are configured uniquely per application.00b = Auxiliary channel off01b = Auxiliary channe…";
CM_ SG_ 2561146622 AuxiliaryIO44 "Identifies the current status of auxiliary input/output functions that are configured uniquely per application.00b = Auxiliary channel off01b = Auxiliary channe…";
CM_ SG_ 2561146622 AuxiliaryIO45 "Identifies the current status of auxiliary input/output functions that are configured uniquely per application.00b = Auxiliary channel off01b = Auxiliary channe…";
CM_ SG_ 2561146622 AuxiliaryIO46 "Identifies the current status of auxiliary input/output functions that are configured uniquely per application.00b = Auxiliary channel off01b = Auxiliary channe…";
CM_ SG_ 2561146622 AuxiliaryIO47 "Identifies the current status of auxiliary input/output functions that are configured uniquely per application.00b = Auxiliary channel off01b = Auxiliary channe…";
CM_ SG_ 2561146622 AuxiliaryIO48 "Identifies the current status of auxiliary input/output functions that are configured uniquely per application.00b = Auxiliary channel off01b = Auxiliary channe…";
CM_ BO_ 2561212158 "Text Display";
CM_ SG_ 2561212158 TextDisplayIndex "Used for overwriting consecutive bytes of a displayed string when byte 1 Text Display Instructions state is set for overwrite substring mode.  When used, this b…";
CM_ SG_ 2561212158 TextDisplayInstructions "This parameter describes the status for the display how to show the information.0000b = Clear display - The displayed information should be deleted or not displ…";
CM_ BO_ 2561277694 "Forward Lane Image Command";
CM_ SG_ 2561277694 CurrentRegion "Command sent to forward imager which specifies the operator's desired region to assist with object recognition.Message shall use the 2-character string country …";
CM_ SG_ 2561277694 CurrentSubRegion "Command sent to all Forward Imager which specifies the operator's desired sub-region to assist with object recognition.This signal will be dependent on Current …";
CM_ SG_ 2561277694 LnDprtrWrnngEnlCmmnd "Command to enable/disable Lane Departure Indication00b = Disable Lane Departure Warning01b = Enable Lane Departure Warning10b = Reserved11b = Don´t care…";
CM_ SG_ 2561277694 LaneKeepingAssistEnableCommand "Command to enable/disable lane keeping assist system.00b = Disable lane keeping assist01b = Enable lane keeping assist10b = Reserved11b = Don´t care…";
CM_ SG_ 2561277694 LaneCenteringEnableCommand "Command to enable/disable lane centering system.00b = Disable lane centering01b = Enable lane centering10b = Reserved11b = Don´t care…";
CM_ SG_ 2561277694 RqstdAtvStrngDrvrPrfrnMd "The requested active steering mode to the active steering system from the operators interface. This parameter is the driver's request, the state is shown in SPN…";
CM_ BO_ 2561605374 "Tire Pressure Reference Setting";
CM_ SG_ 2561605374 ReferenceTirePressureSetting "Reference value of the tire pressure setting as basis for the tire pressure monitoring…";
CM_ SG_ 2561605374 TireLocation "Identifies which tire is associated with the parametric data in this PGN.The low order 4 bits represent a position number, counting left to right when facing in…";
CM_ BO_ 2563768062 "Continuous Torque & Speed Limit Request";
CM_ SG_ 2563768062 EngnSpdLmtRqstMnmmCntns "Requested minimum continuous engine speed…";
CM_ SG_ 2563768062 EngnSpdLmtRqstMxmmCntns "Requested maximum continuous engine speed…";
CM_ SG_ 2563768062 EngnTrqLmtRqstMnmmCntns "Requested minimum continuous engine torque (operating range: 0 to 125%)…";
CM_ SG_ 2563768062 EngnTrqLmtRqstMxmmCntns "Requested maximum continuous engine torque (operating range: 0 to 125%)…";
CM_ SG_ 2563768062 MnmmCntnsRtrdrSpdLmtRqst "Requested minimum continuous retarder speed…";
CM_ SG_ 2563768062 MnmmCntnsRtrdrTrqLmtRqst "Requested minimum continuous retarder torque (operating range: -125 to 0%)…";
CM_ SG_ 2563768062 MxmmCntnsRtrdrSpdLmtRqst "Requested maximum continuous retarder speed…";
CM_ SG_ 2563768062 MxmmCntnsRtrdrTrqLmtRqst "Requested maximum continuous retarder torque (operating range: -125 to 0%)…";
CM_ BO_ 2563833598 "Cab Illumination Message";
CM_ SG_ 2563833598 IlluminationBrightnessPercent "Commanded backlight brightness level for all cab displays.  Note:  If a separate device is used to independently control the switch backlight brightness level, …";
CM_ SG_ 2563833598 SwthBklghtIllmntnBrghtnssPrnt "Commanded switch backlight brightness level for all operator control switches.  This is separate from the cab display illumination Brightness Percent parameter.…";
CM_ SG_ 2563833598 SwthIndtnIllmntnBrghtnssPrnt "Commanded switch indication illumination brightness level for all operator control switches. This is separate from the cab display illumination Brightness Perce…";
CM_ BO_ 2564161278 "Time/Date Adjust";
CM_ SG_ 2564161278 Adjustday "The day component for setting the current calendar date.  This should be reported as the day component of the current date according to the calendar date standa…";
CM_ SG_ 2564161278 Adjusthours "The hours component for setting the current time of day.  This should be reported as the hours component of the current time according to the time of day standa…";
CM_ SG_ 2564161278 Adjustlocalhouroffset "The hour component for setting the offset between the UTC (Universal Time Coordinate) time and date and a the local time zone time and date.  This is the number…";
CM_ SG_ 2564161278 Adjustlocalminuteoffset "The minute component for setting the offset between the UTC (Universal Time Coordinate) time and date and a the local time zone time and date.  This is the numb…";
CM_ SG_ 2564161278 Adjustminutes "The minutes component for setting the current time of day.  This should be reported as the minutes component of the current time according to the time of day st…";
CM_ SG_ 2564161278 Adjustmonth "The month component for setting the current calendar date.  This should be reported as the month component of the current date according to the calendar date st…";
CM_ SG_ 2564161278 Adjustseconds "The seconds component for setting the current time of day.  This should be reported as the seconds component of the current time according to the time of day st…";
CM_ SG_ 2564161278 Adjustyear "The year component for setting the current calendar date.  This should be reported as the year component of the current date according to the calendar date stan…";
CM_ BO_ 2564882174 "Cab Message 1";
CM_ SG_ 2564882174 AftrtrtmntRgnrtnFrSwth "Indicates the state of a switch available to the operator that forces aftertreatment regeneration. 00b = not active 01b = active 10b = error 11b = not available…";
CM_ SG_ 2564882174 AftrtrtmntRgnrtnInhtSwth "Indicates the state of a switch available to the operator that inhibits aftertreatment regeneration. 00b = not active 01b = active 10b = error 11b = not availab…";
CM_ SG_ 2564882174 AtmtGrShftngEnlSwth "Indicates that automated gear shifting is enabled via a switch00b = Automated Gear Shifting is disabled01b = Automated Gear Shifting is enabled10b = Error11b = …";
CM_ SG_ 2564882174 AuxiliaryHeaterModeRequest "Request to activate the auxiliary heater.0000b = De-activate auxiliary heater0001b = Off due to ADR per European Regulations for Transport of hazardous material…";
CM_ SG_ 2564882174 AxlrHtrClntPmpRqst "Indicates whether to activate the auxiliary heater coolant water pump.00b = Deactivate water pump01b = Activate water pump10b = Reserved11b = Don't care/take no…";
CM_ SG_ 2564882174 BatteryMainSwitchHoldRequest "Request to hold the battery main switch.00b = Release Battery Main Switch01b = Hold Battery Main Switch10b = undefined11b = Don't care/take no action…";
CM_ SG_ 2564882174 CabInteriorTemperatureCommand "Parameter used to command a certain cab interior temperature.Note: See also SPN 170.  SPN 1662 is an additional diagnostic SPN associated with cab temperature.…";
CM_ SG_ 2564882174 EngineFan1RequestedPercentSpeed "Fan speed of the first or only fan in the system as a ratio of the actual fan drive (current speed) to the fully engaged fan drive (maximum fan speed). A two st…";
CM_ SG_ 2564882174 EngnAtmtStrtEnlSwth "Switch signal which enables the idle management system to be enabled. When this system is enabled with the engine in an idle mode and safe operating conditions …";
CM_ SG_ 2564882174 OperatorSeatDirectionSwitch "Senses whether the operator seat is in the forward driving position00b = Operator seat not facing forward01b = Operator seat is facing forward10b = Error11b = N…";
CM_ SG_ 2564882174 ParkBrakeCommand "Request by a secondary device to command the Park Brake.  The Park Brake controller should treat this as a request and should apply the Park Brake as determined…";
CM_ SG_ 2564882174 RequestCabZoneHeating "Request to activate cab zone heating.00b = Do not heat cab engine zone01b = Heat cab zone10b = Reserved11b = Don't care/take no action…";
CM_ SG_ 2564882174 RequestEngineZoneHeating "Request to activate engine zone heating.00b = Do not heat engine zone01b = Heat engine zone10b = Reserved11b = Don't care/take no action…";
CM_ SG_ 2564882174 SeatBeltSwitch "State of switch used to determine if Seat Belt is buckled00b = NOT Buckled01b = OK - Seat Belt is buckled10b = Error - Switch state cannot be determined11b = No…";
CM_ SG_ 2564882174 SltdMxmmVhlSpdLmt "User selected maximum vehicle speed.  If one is selected, then this SPN must equal one of the maximum vehicle speeds #1-#7 from PGN 64997 - Maximum Vehicle Spee…";
CM_ SG_ 2564882174 VhlLmtngSpdGvrnrDrmntSwth "Switch signal which decreases the Vehicle Limiting Speed Governor (VLSG).00b = Switch in the off state01b = Switch in the on state - decrease10b = Error11b = No…";
CM_ SG_ 2564882174 VhlLmtngSpdGvrnrEnlSwth "Switch signal which enables the Vehicle Limiting Speed Governor (VLSG) such that the vehicle speed may be either increased or decreased when the engine is off i…";
CM_ SG_ 2564882174 VhlLmtngSpdGvrnrInrmntSwth "Switch signal which increases the Vehicle Limiting Speed Governor (VLSG).00b = Switch in the off state01b = Switch in the on state - increase10b = Error11b = No…";
CM_ BO_ 2565865982 "Electronic Brake Controller 1";
CM_ SG_ 2565865982 ABSEBSAmrWrnngSgnlPwrdVhl "This parameter commands the ABS/EBS amber/yellow optical warning signal00b = Off01b = On10b = Reserved11b = Take no action…";
CM_ SG_ 2565865982 ABSFullyOperational "Signal which indicates whether an ABS system is fully operational or whether its functionality is reduced by a defect or by an intended action (e.g., by activat…";
CM_ SG_ 2565865982 ABSOffroadSwitch "Switch signal which indicates the position of the ABS off-road switch.00b = ABS off-road switch passive01b = ABS off-road switch active10b = Error11b = Not avai…";
CM_ SG_ 2565865982 AcceleratorInterlockSwitch "Switch signal used to disable the accelerator and remote accelerator inputs, causing the engine to return to idle.00b = Off01b = On10b = Error11b = Not availabl…";
CM_ SG_ 2565865982 AntiLockBrakingABSActive "State signal which indicates that the ABS is active.  The signal is set active when wheel brake pressure actually starts to be modulated by ABS and is reset to …";
CM_ SG_ 2565865982 ASRBrakeControlActive "State signal which indicates that ASR brake control is active. Active means that ASR actually controls wheel brake pressure at one or more wheels of the driven …";
CM_ SG_ 2565865982 ASREngineControlActive "State signal which indicates that ASR engine control has been commanded to be active. Active means that ASR actually tries to control the engine. This state sig…";
CM_ SG_ 2565865982 ASRHillHolderSwitch "Switch signal which indicates the position of the ASR hill holder switch.00b = ASR hill holder switch passive01b = ASR hill holder switch active10b = Error11b =…";
CM_ SG_ 2565865982 ASROffroadSwitch "Switch signal which indicates the position of the ASR off-road switch.00b = ASR off-road switch passive01b = ASR off-road switch active10b = Error11b = Not avai…";
CM_ SG_ 2565865982 ATCASRInformationSignal "This parameter commands the ATC/ASR driver information signal, for example a dash lamp.00b = Off01b = On 10b = Reserved11b = Take no action…";
CM_ SG_ 2565865982 BrakePedalPosition "Ratio of brake pedal position to maximum pedal position.  Used for electric brake applications. 0% means no braking. Also when there are two brake pedals on the…";
CM_ SG_ 2565865982 EBSBrakeSwitch "Switch signal which indicates that the brake pedal is being pressed.  The EBS brake switch is independent of the brake light switch and has no provisions for ex…";
CM_ SG_ 2565865982 EBSRedWarningSignal "This parameter commands the EBS red optical warning signal00b = Off01b = On10b = Reserved11b = Take no action…";
CM_ SG_ 2565865982 EngineAuxiliaryShutdownSwitch "Switch signal which requests that all engine fueling stop.00b = Off01b = On10b = Error11b = Not available…";
CM_ SG_ 2565865982 EngineDerateSwitch "Switch signal used to activate the torque limiting feature of the engine.  The specific nature of torque limiting should be verified with the manufacturer.00b =…";
CM_ SG_ 2565865982 EngineRetarderSelection "The position of the operator controlled selector, expressed as a percentage and determined by the ratio of the current position of the selector to its maximum p…";
CM_ SG_ 2565865982 Haltbrakeswitch "Switch signal which indicates the position of the halt brake switch.00b = Halt brake switch passive01b = Halt brake switch active10b = Error11b = Not available…";
CM_ SG_ 2565865982 RailroadModeSwitch "Switch signal which indicates the position of the Railroad mode switch.00b = Railroad mode switch passive (City/Highway mode)01b = Railroad mode switch active (…";
CM_ SG_ 2565865982 RemoteAcceleratorEnableSwitch "Switch signal which indicates that the remote accelerator has been enabled and controls the engine.  00b = Off01b = On10b = Error11b = Not availableNOTE—The acc…";
CM_ SG_ 2565865982 SrAddrssfCntrllngDvfrBrkCntrl "The source address of the SAE J1939 device currently controlling the brake system. Its value may be the source address of the ECU transmitting the message (whic…";
CM_ SG_ 2565865982 TractionControlOverrideSwitch "Switch signal which indicates the position of the traction control override switch.  The traction control override signal disables the automatic traction contro…";
CM_ SG_ 2565865982 TrailerABSStatus "State signal which indicates that ABS in the trailer is actively controlling the brakes.  A message is sent to the tractor from the trailer (i.e. by PLC). The r…";
CM_ SG_ 2565865982 TrtrMntdTrlrABSWrnngSgnl "This parameter commands the tractor-mounted trailer ABS optical warning signal.00b = Off01b = On 10b = Reserved11b = Take no action…";
CM_ BO_ 2565867006 "Electronic Transmission Controller 2";
CM_ SG_ 2565867006 TransmissionActualGearRatio "Actual ratio of input shaft speed to output shaft speed.…";
CM_ SG_ 2565867006 TransmissionCurrentGear "The gear currently engaged in the transmission or the last gear engaged while the transmission is in the process of shifting to the new or selected gear.  Trans…";
CM_ SG_ 2565867006 TransmissionCurrentRange "Range currently being commanded by the transmission control system. Characters may include P, Rx, Rx-1...R2, R1, R, Nx, Nx-1...N2, N1, N, D, D1, D2..., Dx, L, L…";
CM_ SG_ 2565867006 TransmissionRequestedRange "Range selected by the operator.  Characters may include P, Rx, Rx-1...R2, R1, R, Nx, Nx-1...N2, N1, N, D, D1, D2..., Dx, L, L1, L2..., Lx-1, 1, 2, 3,...  If onl…";
CM_ SG_ 2565867006 TransmissionSelectedGear "The gear that the transmission will attempt to achieve during the current shift if a shift is in progress, or the next shift if one is pending (i.e., waiting fo…";
CM_ BO_ 2565867262 "Electronic Axle Controller 1";
CM_ SG_ 2565867262 DffrntlLkSttCntrlFrnt "State used which indicates the condition of the central front differential lock.  The differential locks are located as defined in figure SPN564_A.00b = Differe…";
CM_ SG_ 2565867262 DffrntlLkSttCntrlRr "State used which indicates the condition of the central rear differential lock.  The differential locks are located as defined in figure SPN564_A.00b = Differen…";
CM_ SG_ 2565867262 DifferentialLockStateCentral "State used which indicates the condition of the central differential lock.  The differential locks are located as defined in attached figure SPN564_A.00b = Diff…";
CM_ SG_ 2565867262 DifferentialLockStateFrontAxle1 "State used which indicates the condition of the front axle 1 differential lock.  The differential locks are located as defined in figure SPN564_A.00b = Differen…";
CM_ SG_ 2565867262 DifferentialLockStateFrontAxle2 "State used which indicates the condition of the front axle 2 differential lock. The differential locks are located as defined in figure SPN 564_A.00b = Differen…";
CM_ SG_ 2565867262 DifferentialLockStateRearAxle1 "State used which indicates the condition of the rear axle 1 differential lock.  The differential locks are located as defined in figure SPN 564_A.00b = Differen…";
CM_ SG_ 2565867262 DifferentialLockStateRearAxle2 "State used which indicates the condition of the rear axle 2 differential lock.  The differential locks are located as defined in figure SPN 564_A.00b = Differen…";
CM_ SG_ 2565867262 DifferentialLockStateRearAxle3 "State used which indicates the condition of the rear axle 3 differential lock. The differential locks are located as defined in figure SPN 564_A.00b = Different…";
CM_ SG_ 2565867262 Frontaxlegroupengagementstatus "Front axle group engagement status 00b = front axle group disengaged 01b = front axle group engaged10b = error11b = not available…";
CM_ SG_ 2565867262 Location "To identify to which of several similar devices (such as tires or fuel tanks) the information applies.The low order 4 bits represent a position number, counting…";
CM_ SG_ 2565867262 Rearaxlegroupengagementstatus "Rear axle group engagement status00b = rear axle group disengaged 01b = rear axle group engaged10b = error11b = not available…";
CM_ BO_ 2565867774 "Hydraulic Pressure Governor Info";
CM_ SG_ 2565867774 EngnHdrlPrssrGvrnrMdIndtr "Mode for governor operation is hydraulic pressure control.00b = Disabled01b = Enabled10b = Error Indicator11b = Not Available…";
CM_ SG_ 2565867774 EngnHdrlPrssrGvrnrSwth "Switch that sets the  mode of hydraulic governor00b = Pressure Mode Inactive01b = Pressure Mode Active10b = Error Indicator11b = Not Available…";
CM_ SG_ 2565867774 FireApparatusPumpEngagement "The measured status of the pump used to provide water in fire fighting apparatus for distribution of water through water cannons or fire hoses.00b = Pump not en…";
CM_ SG_ 2565867774 FrApprtsOkTPmpIntrlk "The measured state of the Okay To Pump interlock of the fire apparatus.00b = Okay to Pump Interlock Inactive01b = Okay to Pump Interlock Active10b = Error11b = …";
CM_ SG_ 2565867774 HdrlDshrgPrssrStPnt "Hydraulic pressure governing system discharge pressure set point.…";
CM_ SG_ 2565867774 HdrlPrssrGvrnrDrsSwth "Switch that commands hydraulic pressure governor to decrease engine rpm resulting in expected decrease of hydraulic discharge pressure.00b = Decrease Switch Ina…";
CM_ SG_ 2565867774 HdrlPrssrGvrnrIdlSwth "Switch that commands hydraulic pressure governor to decrease engine rpm to its idle position.00b = Idle Switch Inactive01b = Idle Switch Active10b = Error11b = …";
CM_ SG_ 2565867774 HdrlPrssrGvrnrInrsSwth "Switch that commands hydraulic pressure governor to increase engine rpm resulting in expected increase of hydraulic discharge pressure.00b = Increase Switch Ina…";
CM_ SG_ 2565867774 HdrlPrssrGvrnrPrstSwth "Switch that commands hydraulic pressure governor to increase or decrease engine rpm to achieve a predefined discharge pressure.00b = Preset Switch Inactive01b =…";
CM_ SG_ 2565867774 HydraulicIntakePressure "Hydraulic pressure measured at the intake of the hydraulic pump.…";
CM_ SG_ 2565867774 HydraulicPressure "Hydraulic pressure measured at the output of the hydraulic pump.…";
CM_ BO_ 2565868030 "Vehicle Dynamic Stability Control 2";
CM_ SG_ 2565868030 LateralAcceleration "Indicates a lateral acceleration of the vehicle (the component of vehicle acceleration vector along the Y-axis). A positive lateral acceleration signal results …";
CM_ SG_ 2565868030 LongitudinalAcceleration "Indicates the longitudinal acceleration of the vehicle. A positive longitudinal acceleration signal results when the vehicle speed increases, regardless of driv…";
CM_ SG_ 2565868030 SteeringWheelAngle "The main operator`s steering wheel angle (on the steering column, not the actual wheel angle).  The vehicle being steered to the left (counterclockwise) results…";
CM_ SG_ 2565868030 SteeringWheelAngleSensorType "Indicates whether the steering wheel angle sensor is capable of absolute measuring of the number of steering wheel turns or not (relative measuring to position …";
CM_ SG_ 2565868030 SteeringWheelTurnCounter "Indicates number of steering wheel turns, absolute position or relative position at ignition on. Positive values indicate left turns.…";
CM_ SG_ 2565868030 YawRate "Indicates the rate of rotation about the vertical axis (i.e. the z-axis).  A positive yaw rate signal results when the vehicle turns counter-clockwise.   This p…";
CM_ BO_ 2565868542 "Electronic Steering Control";
CM_ SG_ 2565868542 ActualInnerwheelsteeringangle "Signal which indicates the actual inner wheel steering angle.  The steering angle is the angle of wheel turn relative to the vehicle x-axis (yaw angle of inner …";
CM_ SG_ 2565868542 AxleLocation "To identify to which of several similar devices (such as tires or fuel tanks) the information applies.The low order 4 bits represent a position number, counting…";
CM_ SG_ 2565868542 StatusofSteeringAxle "A signal which indicates different states of the steering axle0000b = Axle steering not active (adhesion steering)0001b = Axle steering active0010b = Axle cente…";
CM_ SG_ 2565868542 SteeringType "Indicates the different types of steering systems (ref. ECE Regulation 79 paragraph 2.5)0000b = Main steering system0001b = Auxiliary steering equipment0010b to…";
CM_ SG_ 2565868542 StrlLftAxlLwrngInht "A signal which indicates if lowering of lifted axle is allowed or inhibited.00b = Lowering allowed01b = Lowering inhibited10b = Reserved11b = Not available…";
CM_ SG_ 2565868542 TypeofSteeringForces "Type of Steering Forces (Ref. ECE Regulation 79 paragraph 2.5)0000b = Manual steering equipment0001b = Power assisted steering equipment0010b = Full power steer…";
CM_ SG_ 2565868542 TypeofSteeringTransmission "Type of Steering Transmission (Ref. ECE Regulation 79 paragraph 2.6)0000b = Purely mechanical steering transmission0001b = Purely hydraulic steering transmissio…";
CM_ BO_ 2565869310 "Aftertreatment 1 Intake Gas 1";
CM_ SG_ 2565869310 Aftrtrtmnt1IntkGsSnsr1HtrCntrl "Indicates the heater status in the warm-up process.  Upon receiving a power-up command, the gas sensor ramps up according to a manufacturer defined profile.  Th…";
CM_ SG_ 2565869310 Aftrtrtmnt1IntkGsSnsr1tTmprtr "Indicates that the heater element of the aftertreatment intake gas sensor, either NOx or O2, is within the manufacturer's specified range for accurate measureme…";
CM_ SG_ 2565869310 Atttt1ItGsSs1HtPFMI "Used to identify the applicable J1939-73 FMI detected in the heater of the intake exhaust gas sensor, either NOx or O2, by the manufacturer’s sensor control sof…";
CM_ SG_ 2565869310 Atttt1ItOxSs1PFMI "Used to identify the applicable J1939-73 FMI detected in the aftertreatment intake oxygen sensor by the manufacturer’s sensor control software in exhaust bank 1…";
CM_ SG_ 2565869310 Atttt1ItWdRPtOx1RdSt "Indicates that the percent oxygen reading of the aftertreatment intake gas sensor, either NOx or O2, is stable as determined by the manufacturer's control softw…";
CM_ SG_ 2565869310 EngineExhaust1NOx1 "The amount of combined NO and NO2 in the exhaust, represented in NOx molecule parts per million non-NOx molecules, in exhaust bank 1.  This sensor is located at…";
CM_ SG_ 2565869310 EngineExhaust1NOx1ReadingStable "Indicates that the NOx reading of the first NOx sensor is stable as determined by the manufacturer's control software in exhaust bank 1.  This sensor is located…";
CM_ SG_ 2565869310 EngnExhst1NOxSnsr1PrlmnrFMI "Used to identify the applicable J1939-73 FMI detected in the first NOx sensor by the manufacturer’s sensor control software in exhaust bank 1.  This sensor is l…";
CM_ SG_ 2565869310 EngnExhst1NOxSnsr1SlfdgnssStts "Self-diagnosis result status for the first NOx sensor in Engine Exhaust Bank 1 (EEB1h).  This sensor is located at the intake of the aftertreatment system if an…";
CM_ SG_ 2565869310 EngineExhaust1PercentOxygen1 "The actual oxidation factor (Percent Oxygen) of the gas within the exhaust stream. For positive values, the parameter represents the percent oxygen in excess of…";
CM_ SG_ 2565869310 EngnExhst1GsSnsr1PwrInRng "Indicates that the power supplied to the aftertreatment intake gas sensor, either NOx or O2, is within the manufacturer's specification in exhaust bank 1.  This…";
CM_ BO_ 2565869566 "Aftertreatment 1 Outlet Gas 1";
CM_ SG_ 2565869566 Aftertreatment1OutletNOx1 "The amount of combined NO and NO2 in the exhaust exiting the aftertreatment system measured by a NOx sensor at the aftertreatment outlet, represented in NOx mol…";
CM_ SG_ 2565869566 Aftrtrtmnt1OtltGsSnsr1HtrCntrl "Indicates the heater status in the warm-up process.  Upon receiving a power-up command, the gas sensor ramps up according to a manufacturer defined profile.  Th…";
CM_ SG_ 2565869566 Aftrtrtmnt1OtltGsSnsr1PwrInRng "Indicates that the power supplied to the aftertreatment outlet gas sensor, either NOx or O2, is within the manufacturer's specification in exhaust bank 1. This …";
CM_ SG_ 2565869566 Aftrtrtmnt1OtltGsSnsr1tTmprtr "Indicates that the heater element of the aftertreatment outlet gas sensor, either NOx or O2, is within the manufacturer's specified range for accurate measureme…";
CM_ SG_ 2565869566 Aftrtrtmnt1OtltNOx1RdngStl "Indicates that the NOx reading of the aftertreatment outlet NOx sensor is stable as determined by the manufacturer's control software in exhaust bank 1.00b = No…";
CM_ SG_ 2565869566 Aftrtrtmnt1OtltPrntOxgn1 "The actual oxidation factor (percent oxygen) of the gas within the exhaust stream.  For positive values, the parameter represents the percent oxygen in excess o…";
CM_ SG_ 2565869566 Atttt1OttGsSs1HtPFMI "Used to identify the applicable J1939-73 FMI detected in the heater of the outlet exhaust gas sensor, either NOx or O2, by the manufacturer’s sensor control sof…";
CM_ SG_ 2565869566 Atttt1OttNOxSs1PFMI "Used to identify the applicable J1939-73 FMI detected in the aftertreatment outlet NOx sensor by the manufacturer’s sensor control software in exhaust bank 1.  …";
CM_ SG_ 2565869566 Atttt1OttNOxSs1SdssStts "Self-diagnosis result status for NOx sensor ATO1 (Aftertreatment Outlet Bank 1)000b = Diagnosis not active001b = NOx Sensor ATO1 Self Diagnosis active flag010b …";
CM_ SG_ 2565869566 Atttt1OttOxSs1PFMI "Used to identify the applicable J1939-73 FMI detected in the aftertreatment outlet oxygen sensor by the manufacturer’s sensor control software in exhaust bank 1…";
CM_ SG_ 2565869566 Atttt1OttWdRPtOx1RdSt "Indicates that the percent oxygen reading of the aftertreatment outlet gas sensor, either NOx or O2, is stable as determined by the manufacturer's control softw…";
CM_ BO_ 2565869822 "Aftertreatment 2 Intake Gas 1";
CM_ SG_ 2565869822 Aftrtrtmnt2IntkGsSnsr1HtrCntrl "Indicates the heater status in the warm-up process.  Upon receiving a power-up command, the gas sensor ramps up according to a manufacturer defined profile.  Th…";
CM_ SG_ 2565869822 Aftrtrtmnt2IntkGsSnsr1tTmprtr "Indicates that the heater element of the aftertreatment intake gas sensor, either NOx or O2, is within the manufacturer's specified range for accurate measureme…";
CM_ SG_ 2565869822 Atttt2ItGsSs1HtPFMI "Used to identify the applicable J1939-73 FMI detected in the heater of the intake exhaust gas sensor, either NOx or O2, by the manufacturer’s sensor control sof…";
CM_ SG_ 2565869822 Atttt2ItOxSs1PFMI "Used to identify the applicable J1939-73 FMI detected in the aftertreatment intake oxygen sensor by the manufacturer’s sensor control software in exhaust bank 2…";
CM_ SG_ 2565869822 Atttt2ItWdRPtOx1RdSt "Indicates that the percent oxygen reading of the aftertreatment intake gas sensor, either NOx or O2, is stable as determined by the manufacturer's control softw…";
CM_ SG_ 2565869822 EngineExhaust2NOx1 "The amount of combined NO and NO2 in the exhaust, represented in NOx molecule parts per million non-NOx molecules, in exhaust bank 2.  This sensor is located at…";
CM_ SG_ 2565869822 EngineExhaust2NOx1ReadingStable "Indicates that the NOx reading of the first NOx sensor is stable as determined by the manufacturer's control software in exhaust bank 2.  This sensor is located…";
CM_ SG_ 2565869822 EngnExhst2NOxSnsr1PrlmnrFMI "Used to identify the applicable J1939-73 FMI detected in the NOx sensor by the manufacturer’s sensor control software in exhaust bank 2.  This sensor is located…";
CM_ SG_ 2565869822 EngnExhst2NOxSnsr1SlfdgnssStts "Self-diagnosis result status for NOx sensor EEB2h (Engine Exhaust Bank 2).  This sensor is located at the intake of the aftertreatment system if an aftertreatme…";
CM_ SG_ 2565869822 EngineExhaust2PercentOxygen1 "The actual oxidation factor (percent oxygen) of the gas within the exhaust stream.  For positive values, the parameter represents the percent oxygen in excess o…";
CM_ SG_ 2565869822 EngnExhst2GsSnsr1PwrInRng "Indicates that the power supplied to the intake gas sensor, either NOx or O2, is within the manufacturer's specification in exhaust bank 2. This parameter repor…";
CM_ SG_ 2565869822 EngnExhst2Intk2GsSnsrPwrSppl "State signal which indicates when the Engine Exhaust 2 Intake 2 Gas Sensor driver output is being driven.  On means the ECU is powering the Engine Exhaust 2 Int…";
CM_ BO_ 2565870078 "Aftertreatment 2 Outlet Gas 1";
CM_ SG_ 2565870078 Aftertreatment2OutletNOx1 "The amount of combined NO and NO2 in the exhaust entering the aftertreatment system measured by a NOx sensor at the aftertreatment outlet, represented in NOx mo…";
CM_ SG_ 2565870078 Aftrtrtmnt2Otlt2GsSnsrPwrSppl "State signal which indicates when the Aftertreatment 2 Outlet 2 Gas Sensor driver output is being driven.  On means the ECU is powering the Aftertreatment 2 Out…";
CM_ SG_ 2565870078 Aftrtrtmnt2OtltGsSnsr1HtrCntrl "Indicates the heater status in the warm-up process.  Upon receiving a power-up command, the gas sensor ramps up according to a manufacturer defined profile.  Th…";
CM_ SG_ 2565870078 Aftrtrtmnt2OtltGsSnsr1PwrInRng " Indicates that the power supplied to the aftertreatment outlet gas sensor, either NOx or O2, is within the manufacturer's specification in exhaust bank 2.For a…";
CM_ SG_ 2565870078 Aftrtrtmnt2OtltGsSnsr1tTmprtr "Indicates that the heater element of the aftertreatment outlet gas sensor, either NOx or O2, is within the manufacturer's specified range for accurate measureme…";
CM_ SG_ 2565870078 Aftrtrtmnt2OtltNOx1RdngStl "Indicates that the NOx reading of the aftertreatment outlet NOx sensor is stable as determined by the manufacturer's control software in exhaust bank 2.For a si…";
CM_ SG_ 2565870078 Aftrtrtmnt2OtltPrntOxgn1 "The actual oxidation factor (percent oxygen) of the gas within the exhaust stream.  For positive values, the parameter represents the percent oxygen in excess o…";
CM_ SG_ 2565870078 Atttt2OttGsSs1HtPFMI "Used to identify the applicable J1939-73 FMI detected in the heater of the outlet exhaust gas sensor, either NOx or O2, by the manufacturer’s sensor control sof…";
CM_ SG_ 2565870078 Atttt2OttNOxSs1PFMI "Used to identify the applicable J1939-73 FMI detected in the aftertreatment outlet NOx sensor by the manufacturer’s sensor control software in exhaust bank 2.  …";
CM_ SG_ 2565870078 Atttt2OttNOxSs1SdssStts "Self-diagnosis result status for NOx sensor ATO2 (Aftertreatment Outlet Bank 2)000b = Diagnosis not active001b = NOx Sensor ATO2 Self Diagnosis active flag010b …";
CM_ SG_ 2565870078 Atttt2OttOxSs1PFMI "Used to identify the applicable J1939-73 FMI detected in the aftertreatment outlet oxygen sensor by the manufacturer’s sensor control software in exhaust bank 2…";
CM_ SG_ 2565870078 Atttt2OttWdRPtOx1RdSt "Indicates that the percent oxygen reading of the aftertreatment outlet gas sensor, either NOx or O2, is stable as determined by the manufacturer's control softw…";
CM_ BO_ 2565870334 "Fifth Wheel Smart Systems 1";
CM_ SG_ 2565870334 FifthWheelDrawbarForce "Fifth wheel drawbar force, with the trailer held stationary a positive force is generated by the vehicle pulling forward.…";
CM_ SG_ 2565870334 FifthWheelRollMoment "Fifth wheel roll moment force - If the moment is positive, the trailer is rolling clockwise relative to the normal vehicle forward motion.…";
CM_ SG_ 2565870334 FifthWheelRollWarningIndicator "Indicates to the vehicle operator that the roll moment has exceeded a preset limit. 00b = Limit not exceeded01b = Limit exceeded10b = error11b = Not Available…";
CM_ SG_ 2565870334 FifthWheelVerticalForce "The amount of load being applied to the fifth wheel by the trailer. Zero load is indicated without a trailer.…";
CM_ BO_ 2565873150 "Steering Angle Sensor Information";
CM_ SG_ 2565873150 MessageChecksum "The message checksum is used to verify the signal path from the demanding device to the steering controller.  The support of this parameter is mandatory if PGN …";
CM_ SG_ 2565873150 MessageCounter "The message counter is to verify the signal path from the demanding device to the steering controller.  The support of this parameter is mandatory.Note:  The in…";
CM_ SG_ 2565873150 SteeringAngleSensorActiveMode "This signal indicates the operational mode of the steering angle sensor.00b = Programming mode active01b = Normal mode active10b = Reserved11b = Not available…";
CM_ SG_ 2565873150 SteeringAngleSensorCalibrated "This signal indicates the calibration status of the steering angle sensor.00b = SAS not calibrated01b = SAS calibrated10b = Reserved11b = Not available…";
CM_ SG_ 2565873150 SteeringWheelAngle "The main operator`s steering wheel angle (on the steering column, not the actual wheel angle). The vehicle being steered to the left (counterclockwise) results …";
CM_ SG_ 2565873150 SteeringWheelAngleRange "The signal indicates the range of  the steering wheel angle the sensor element is capable to measure. The steering wheel angle signal ranges between the negativ…";
CM_ SG_ 2565873150 SteeringWheelAngleRangeCounter "The signal indicates the number of steering wheel angle range overflows if the operating range of steering wheel is greater than the measuring range of sensor e…";
CM_ SG_ 2565873150 StrngWhlAnglRngCntrTp "The signal indicates whether the steering wheel angle sensor is capable of absolute measuring of the number of steering wheel angle ranges or not.  Absolute mea…";
CM_ BO_ 2565874174 "Engine Speed Sensor Information 1";
CM_ SG_ 2565874174 EngineSpeed1 "The engine speed as measured by speed sensor 1.Note:  This is for the engine speed from the 1st engine speed sensor.  This may be different than SPN 190 when us…";
CM_ SG_ 2565874174 EngineSpeed2 "The engine speed as measured by speed sensor 2Note:  This is for the engine speed from the 2nd engine speed sensor.  This may be different than SPN 190 when use…";
CM_ SG_ 2565874174 EngineSpeed3 "The engine speed as measured by speed sensor 3.Note:  This is for the engine speed from the 3rd engine speed sensor.  This may be different than SPN 190 when us…";
CM_ SG_ 2565874174 EngnSpdSnsr1TmngPttrnStts "This is the timing pattern status of the engine speed sensor signal for sensor 1.   The sensor may be sending a speed signal but the pattern may not be valid.  …";
CM_ SG_ 2565874174 EngnSpdSnsr2TmngPttrnStts "This is the timing pattern status of the engine speed sensor signal for sensor 2.  The sensor may be sending a speed signal but the pattern may not be valid.  S…";
CM_ SG_ 2565874174 EngnSpdSnsr3TmngPttrnStts "This is the timing pattern status of the engine speed sensor signal for sensor 3.  The sensor may be sending a speed signal but the pattern may not be valid.  S…";
CM_ BO_ 2565877502 "Engine Turbocharger Control";
CM_ SG_ 2565877502 EExstB1PssRtCtCd "The control command to the Engine Exhaust Pressure Regulator in bank 1, normalized to percent.  100 percent means the regulator is fully closed, providing the m…";
CM_ SG_ 2565877502 EngnTrhrgrWstgtAttr1Cmmnd "The command to a Turbocharger Wastegate actuator 1, normalized to percent, where 0% nominally represents fully closed (No Flow) and 100% represents fully open (…";
CM_ SG_ 2565877502 EngnTrhrgrWstgtAttr2Cmmnd "The command to a Turbocharger Wastegate actuator 2, normalized to percent, where 0% nominally represents fully closed (No Flow) and 100% represents fully open (…";
CM_ SG_ 2565877502 ETCpssBwAtt1Cd "The command to blow off actuator 1, normalized to percent, where 0% nominally represents fully closed (No Flow) and 100% represents fully open (Max Flow). The p…";
CM_ BO_ 2565917438 "DC/AC Accessory Inverter 1 Feedback 2";
CM_ SG_ 2565917438 DCACAssIvt1PwLtddtACSdRMSCt "AC Side Output power is being limited due to AC Side output RMS current (see SPN 9200) approaching or exceeding the maximum limit (See SPN 9228).00b = No power …";
CM_ SG_ 2565917438 DCACAssIvt1PwLtddtCtTpt "Output power is being limited due to the controller temperature (see SPN 9204) approaching or exceeding the maximum limit.00b = No power limit for this reason01…";
CM_ SG_ 2565917438 DCACAssIvt1PwLtddtDCSdCt "Output power is being limited due to DC Side input current (see SPN 8891) approaching or exceeding the maximum limit (See SPN 9226).00b = No power limit for thi…";
CM_ SG_ 2565917438 DCACAssIvt1PwLtddtDCSdVtM "Output power is being limited due to DC Side input voltage (see SPN 8890) approaching or falling below the minimum limit (SPN 9225).00b = No power limit for thi…";
CM_ SG_ 2565917438 DCACAssIvt1PwLtddtEtFtTpt "Output power is being limited due to electronic filter temperature (see SPN 9205) approaching or exceeding the maximum limit.00b = No frequency limit for this r…";
CM_ SG_ 2565917438 DCACAssIvt1PwLtddtPwEtsTpt "Output power is being limited due to power electronics temperature (see SPN 9206) approaching or exceeding the maximum limit.00b = No frequency limit for this r…";
CM_ SG_ 2565917438 DCACAssIvt1PwLtddtRtCLt "Output power is being limited due to the frequency approaching or exceeding the rate of change limit (see SPN 8332).00b = No frequency limit for this reason01b …";
CM_ SG_ 2565917438 DCACAssIvt1PwLtddtUddRs "Output power is being limited due to an undefined reason.00b = No power limit for this reason01b = Power limited for this reason10b = Error11b = Not Available…";
CM_ SG_ 2565917438 DCACAssrInvrtr1FrqnCmmndlwMnmm "Output frequency is being limited due to frequency command (see SPN 8333) approaching or falling below the minimum limit (SPN 8329).00b = No frequency limit for…";
CM_ SG_ 2565917438 DCACAssrInvrtr1FrqnCmmndxdsMxmm "Output frequency is being limited due to frequency command (see SPN 8333) approaching or exceeding the maximum limit (SPN 8328).00b = No frequency limit for thi…";
CM_ BO_ 2565918206 "DC/AC Accessory Inverter 2 Feedback 2";
CM_ SG_ 2565918206 DCACAssIvt2PwLtddtACSdRMSCt "AC Side Output power is being limited due to AC Side output RMS current (see SPN 9201) approaching or exceeding the maximum limit (See SPN 9258).00b = No power …";
CM_ SG_ 2565918206 DCACAssIvt2PwLtddtCtTpt "Output power is being limited due to the controller temperature (see SPN 9231) approaching or exceeding the maximum limit.00b = No power limit for this reason01…";
CM_ SG_ 2565918206 DCACAssIvt2PwLtddtDCSdCt "Output power is being limited due to DC Side input current (see SPN 9238) approaching or exceeding the maximum limit (See SPN 9256).00b = No power limit for thi…";
CM_ SG_ 2565918206 DCACAssIvt2PwLtddtDCSdVtM "Output power is being limited due to DC Side input voltage (see SPN 9237) approaching or falling below the minimum limit (SPN 9255).00b = No power limit for thi…";
CM_ SG_ 2565918206 DCACAssIvt2PwLtddtEtFtTpt "Output power is being limited due to electronic filter temperature (see SPN 9232) approaching or exceeding the maximum limit.00b = No frequency limit for this r…";
CM_ SG_ 2565918206 DCACAssIvt2PwLtddtPwEtsTpt "Output power is being limited due to power electronics temperature (see SPN 9233) approaching or exceeding the maximum limit.00b = No frequency limit for this r…";
CM_ SG_ 2565918206 DCACAssIvt2PwLtddtRtCLt "Output power is being limited due to the frequency approaching or exceeding the rate of change limit (see SPN 8346).00b = No frequency limit for this reason01b …";
CM_ SG_ 2565918206 DCACAssIvt2PwLtddtUddRs "Output power is being limited due to an undefined reason.00b = No power limit for this reason01b = Power limited for this reason10b = Error11b = Not Available…";
CM_ SG_ 2565918206 DCACAssrInvrtr2FrqnCmmndlwMnmm "Output frequency is being limited due to frequency command (see SPN 8347) approaching or falling below the minimum limit (SPN 8343).00b = No frequency limit for…";
CM_ SG_ 2565918206 DCACAssrInvrtr2FrqnCmmndxdsMxmm "Output frequency is being limited due to frequency command (see SPN 8347) approaching or exceeding the maximum limit (SPN 8342).00b = No frequency limit for thi…";
CM_ BO_ 2565920510 "DC/AC Accessory Inverter 1 Command";
CM_ SG_ 2565920510 DCACAssIvt1ACSdMtSttRMSVtRqst "Signal to the DC/AC Accessory Inverter indicating the requested AC side RMS voltage for starting the attached accessory motor.   In a V/Hz variable speed motor …";
CM_ SG_ 2565920510 DCACAssrInvrtr1Dv1Stts "Signal to the DC/AC Accessory Inverter indicating the state of the device attached to the inverter output.  Each output may control multiple devices (e.g. elect…";
CM_ SG_ 2565920510 DCACAssrInvrtr1Dv2Stts "Signal to the DC/AC Accessory Inverter indicating the state of the device attached to the inverter output.  Each output may control multiple devices (e.g. elect…";
CM_ SG_ 2565920510 DCACAssrInvrtr1DvFrqnRtfChngLmt "Signal to the DC/AC Accessory Inverter indicating the frequency rate of change limit of the device(s) attached to the inverter output (Note: Increasing and decr…";
CM_ SG_ 2565920510 DCACAssrInvrtr1DvMnmmFrqn "Signal to the DC/AC Accessory Inverter indicating the minimum frequency of the device(s) attached to the inverter output.  Each output may control multiple devi…";
CM_ SG_ 2565920510 DCACAssrInvrtr1DvMxmmFrqn "Signal to the DC/AC Accessory Inverter indicating the maximum frequency of the devices(s) attached to the inverter output.  Each output may control multiple dev…";
CM_ SG_ 2565920510 DCACAssrInvrtr1DvRtdFrqn "Signal to the DC/AC Accessory Inverter indicating the rated frequency of the device(s) attached to the inverter output.  Each output may control multiple device…";
CM_ SG_ 2565920510 DCACAssrInvrtr1DvRtdRMSVltg "Signal to the DC/AC Accessory Inverter indicating the rated RMS voltage of the device(s) attached to the inverter output.   Each output may control multiple dev…";
CM_ SG_ 2565920510 DCACAssrInvrtr1FrqnCmmnd "Command to the DC/AC Accessory Inverter indicating the Inverter frequency desired for the device(s) attached to the inverter output.  Each output may control mu…";
CM_ SG_ 2565920510 DCACAssrInvrtr1OprtnlCmmnd "Command to the DC/AC Accessory Inverter to enable this output.  Each output may control multiple devices (e.g. electric motors) if they all operate at the same …";
CM_ BO_ 2565920766 "DC/AC Accessory Inverter 1 Feedback";
CM_ SG_ 2565920766 DCACAccessoryInverter1Frequency "Present operating frequency of this DC/AC Accessory Inverter output.…";
CM_ SG_ 2565920766 DCACAssrInvrtr1ACSdPwr "Present operating AC Side power of this DC/AC Accessory Inverter output.…";
CM_ SG_ 2565920766 DCACAssrInvrtr1ACSdRMSCrrnt "Present operating AC Side output RMS line Current of this DC/AC Accessory Inverter.  When connected to a balanced three phase motor, this would be the current i…";
CM_ SG_ 2565920766 DCACAssrInvrtr1ACSdRMSVltg "Present operating AC Side line to line RMS voltage of this DC/AC Accessory Inverter output.  In a three phase balanced motor, this is the RMS voltage across one…";
CM_ SG_ 2565920766 DCACAssrInvrtr1HVILStts "High Voltage Interlock Loop (HVIL) state of the DC/AC Accessory Inverter 1.00b = HVIL Closed01b = HVIL Open10b = Error11b = Not Available…";
CM_ SG_ 2565920766 DCACAssrInvrtr1LdshdRqst "Loadshed Request from this DC/AC Accessory Inverter output.  The Loadshed Requested state is an indication that the inverter output powering this device has a m…";
CM_ SG_ 2565920766 DCACAssrInvrtr1OprtnlStts "Operating Status of this DC/AC Accessory Inverter output. The Inverter Output Faulted state will be communicated when the inverter output has shutdown due to an…";
CM_ BO_ 2565921534 "DC/AC Accessory Inverter 2 Command";
CM_ SG_ 2565921534 DCACAssIvt2ACSdMtSttRMSVtRqst "Signal to the DC/AC Accessory Inverter indicating the requested AC side RMS voltage for starting the attached accessory motor.   In a V/Hz variable speed motor …";
CM_ SG_ 2565921534 DCACAssrInvrtr2Dv1Stts "Signal to the DC/AC Accessory Inverter indicating the state of the device attached to the inverter output.  Each output may control multiple devices (e.g. elect…";
CM_ SG_ 2565921534 DCACAssrInvrtr2Dv2Stts "Signal to the DC/AC Accessory Inverter indicating the state of the device attached to the inverter output.  Each output may control multiple devices (e.g. elect…";
CM_ SG_ 2565921534 DCACAssrInvrtr2DvFrqnRtfChngLmt "Signal to the DC/AC Accessory Inverter indicating the frequency rate of change limit of the device(s) attached to the inverter output (Note: Increasing and decr…";
CM_ SG_ 2565921534 DCACAssrInvrtr2DvMnmmFrqn "Signal to the DC/AC Accessory Inverter indicating the minimum frequency of the device(s) attached to the inverter output.  Each output may control multiple devi…";
CM_ SG_ 2565921534 DCACAssrInvrtr2DvMxmmFrqn "Signal to the DC/AC Accessory Inverter indicating the maximum frequency of the devices(s) attached to the inverter output.  Each output may control multiple dev…";
CM_ SG_ 2565921534 DCACAssrInvrtr2DvRtdFrqn "Signal to the DC/AC Accessory Inverter indicating the rated frequency of the device(s) attached to the inverter output.  Each output may control multiple device…";
CM_ SG_ 2565921534 DCACAssrInvrtr2DvRtdRMSVltg "Signal to the DC/AC Accessory Inverter indicating the rated RMS voltage of the device(s) attached to the inverter output.   Each output may control multiple dev…";
CM_ SG_ 2565921534 DCACAssrInvrtr2FrqnCmmnd "Command to the DC/AC Accessory Inverter indicating the Inverter frequency desired for the device(s) attached to the inverter output.  Each output may control mu…";
CM_ SG_ 2565921534 DCACAssrInvrtr2OprtnlCmmnd "Command to the DC/AC Accessory Inverter to enable this output.  Each output may control multiple devices (e.g. electric motors) if they all operate at the same …";
CM_ BO_ 2565921790 "DC/AC Accessory Inverter 2 Feedback";
CM_ SG_ 2565921790 DCACAccessoryInverter2Frequency "Present operating frequency of this DC/AC Accessory Inverter output.…";
CM_ SG_ 2565921790 DCACAssrInvrtr2ACSdPwr "Present operating AC Side power of this DC/AC Accessory Inverter output.…";
CM_ SG_ 2565921790 DCACAssrInvrtr2ACSdRMSCrrnt "Present operating AC Side output RMS line Current of this DC/AC Accessory Inverter.  When connected to a balanced three phase motor, this would be the current i…";
CM_ SG_ 2565921790 DCACAssrInvrtr2ACSdRMSVltg "Present operating AC Side line to line RMS voltage of this DC/AC Accessory Inverter output.  In a three phase balanced motor, this is the RMS voltage across one…";
CM_ SG_ 2565921790 DCACAssrInvrtr2HVILStts "High Voltage Interlock Loop (HVIL) state of the DC/AC Accessory Inverter 2.00b = HVIL Closed01b = HVIL Open10b = Error11b = Not Available…";
CM_ SG_ 2565921790 DCACAssrInvrtr2LdshdRqst "Loadshed Request from this DC/AC Accessory Inverter output.  The Loadshed Requested state is an indication that the inverter output powering this device has a m…";
CM_ SG_ 2565921790 DCACAssrInvrtr2OprtnlStts "Operating Status of this DC/AC Accessory Inverter output. The Inverter Output Faulted state will be communicated when the inverter output has shutdown due to an…";
CM_ BO_ 2565922558 "DC/AC Accessory Inverter 3 Command";
CM_ SG_ 2565922558 DCACAssIvt3ACSdMtSttRMSVtRqst "Signal to the DC/AC Accessory Inverter indicating the requested AC side RMS voltage for starting the attached accessory motor.   In a V/Hz variable speed motor …";
CM_ SG_ 2565922558 DCACAssrInvrtr3Dv1Stts "Signal to the DC/AC Accessory Inverter indicating the state of the device attached to the inverter output.  Each output may control multiple devices (e.g. elect…";
CM_ SG_ 2565922558 DCACAssrInvrtr3Dv2Stts "Signal to the DC/AC Accessory Inverter indicating the state of the device attached to the inverter output.  Each output may control multiple devices (e.g. elect…";
CM_ SG_ 2565922558 DCACAssrInvrtr3DvFrqnRtfChngLmt "Signal to the DC/AC Accessory Inverter indicating the frequency rate of change limit of the device(s) attached to the inverter output (Note: Increasing and decr…";
CM_ SG_ 2565922558 DCACAssrInvrtr3DvMnmmFrqn "Signal to the DC/AC Accessory Inverter indicating the minimum frequency of the device(s) attached to the inverter output.  Each output may control multiple devi…";
CM_ SG_ 2565922558 DCACAssrInvrtr3DvMxmmFrqn "Signal to the DC/AC Accessory Inverter indicating the maximum frequency of the devices(s) attached to the inverter output.  Each output may control multiple dev…";
CM_ SG_ 2565922558 DCACAssrInvrtr3DvRtdFrqn "Signal to the DC/AC Accessory Inverter indicating the rated frequency of the device(s) attached to the inverter output.  Each output may control multiple device…";
CM_ SG_ 2565922558 DCACAssrInvrtr3DvRtdRMSVltg "Signal to the DC/AC Accessory Inverter indicating the rated RMS voltage of the device(s) attached to the inverter output.   Each output may control multiple dev…";
CM_ SG_ 2565922558 DCACAssrInvrtr3FrqnCmmnd "Command to the DC/AC Accessory Inverter indicating the Inverter frequency desired for the device(s) attached to the inverter output.  Each output may control mu…";
CM_ SG_ 2565922558 DCACAssrInvrtr3OprtnlCmmnd "Command to the DC/AC Accessory Inverter to enable this output.  Each output may control multiple devices (e.g. electric motors) if they all operate at the same …";
CM_ BO_ 2565922814 "DC/AC Accessory Inverter 3 Feedback";
CM_ SG_ 2565922814 DCACAccessoryInverter3Frequency "Present operating frequency of this DC/AC Accessory Inverter output.…";
CM_ SG_ 2565922814 DCACAssrInvrtr3ACSdPwr "Present operating AC Side power of this DC/AC Accessory Inverter output.…";
CM_ SG_ 2565922814 DCACAssrInvrtr3ACSdRMSCrrnt "Present operating AC Side output RMS line Current of this DC/AC Accessory Inverter.  When connected to a balanced three phase motor, this would be the current i…";
CM_ SG_ 2565922814 DCACAssrInvrtr3ACSdRMSVltg "Present operating AC Side line to line RMS voltage of this DC/AC Accessory Inverter output.  In a three phase balanced motor, this is the RMS voltage across one…";
CM_ SG_ 2565922814 DCACAssrInvrtr3HVILStts "High Voltage Interlock Loop (HVIL) state of the DC/AC Accessory Inverter 3.00b = HVIL Closed01b = HVIL Open10b = Error11b = Not Available…";
CM_ SG_ 2565922814 DCACAssrInvrtr3LdshdRqst "Loadshed Request from this DC/AC Accessory Inverter output.  The Loadshed Requested state is an indication that the inverter output powering this device has a m…";
CM_ SG_ 2565922814 DCACAssrInvrtr3OprtnlStts "Operating Status of this DC/AC Accessory Inverter output. The Inverter Output Faulted state will be communicated when the inverter output has shutdown due to an…";
CM_ BO_ 2565923582 "DC/AC Accessory Inverter 4 Command";
CM_ SG_ 2565923582 DCACAssIvt4ACSdMtSttRMSVtRqst "Signal to the DC/AC Accessory Inverter indicating the requested AC side RMS voltage for starting the attached accessory motor.   In a V/Hz variable speed motor …";
CM_ SG_ 2565923582 DCACAssrInvrtr4Dv1Stts "Signal to the DC/AC Accessory Inverter indicating the state of the device attached to the inverter output.  Each output may control multiple devices (e.g. elect…";
CM_ SG_ 2565923582 DCACAssrInvrtr4Dv2Stts "Signal to the DC/AC Accessory Inverter indicating the state of the device attached to the inverter output.  Each output may control multiple devices (e.g. elect…";
CM_ SG_ 2565923582 DCACAssrInvrtr4DvFrqnRtfChngLmt "Signal to the DC/AC Accessory Inverter indicating the frequency rate of change limit of the device(s) attached to the inverter output (Note: Increasing and decr…";
CM_ SG_ 2565923582 DCACAssrInvrtr4DvMnmmFrqn "Signal to the DC/AC Accessory Inverter indicating the minimum frequency of the device(s) attached to the inverter output.  Each output may control multiple devi…";
CM_ SG_ 2565923582 DCACAssrInvrtr4DvMxmmFrqn "Signal to the DC/AC Accessory Inverter indicating the maximum frequency of the devices(s) attached to the inverter output.  Each output may control multiple dev…";
CM_ SG_ 2565923582 DCACAssrInvrtr4DvRtdFrqn "Signal to the DC/AC Accessory Inverter indicating the rated frequency of the device(s) attached to the inverter output.  Each output may control multiple device…";
CM_ SG_ 2565923582 DCACAssrInvrtr4DvRtdRMSVltg "Signal to the DC/AC Accessory Inverter indicating the rated RMS voltage of the device(s) attached to the inverter output.   Each output may control multiple dev…";
CM_ SG_ 2565923582 DCACAssrInvrtr4FrqnCmmnd "Command to the DC/AC Accessory Inverter indicating the Inverter frequency desired for the device(s) attached to the inverter output.  Each output may control mu…";
CM_ SG_ 2565923582 DCACAssrInvrtr4OprtnlCmmnd "Command to the DC/AC Accessory Inverter to enable this output.  Each output may control multiple devices (e.g. electric motors) if they all operate at the same …";
CM_ BO_ 2565923838 "DC/AC Accessory Inverter 4 Feedback";
CM_ SG_ 2565923838 DCACAccessoryInverter4Frequency "Present operating frequency of this DC/AC Accessory Inverter output.…";
CM_ SG_ 2565923838 DCACAssrInvrtr4ACSdPwr "Present operating AC Side power of this DC/AC Accessory Inverter output.…";
CM_ SG_ 2565923838 DCACAssrInvrtr4ACSdRMSCrrnt "Present operating AC Side output RMS line Current of this DC/AC Accessory Inverter.  When connected to a balanced three phase motor, this would be the current i…";
CM_ SG_ 2565923838 DCACAssrInvrtr4ACSdRMSVltg "Present operating AC Side line to line RMS voltage of this DC/AC Accessory Inverter output.  In a three phase balanced motor, this is the RMS voltage across one…";
CM_ SG_ 2565923838 DCACAssrInvrtr4HVILStts "High Voltage Interlock Loop (HVIL) state of the DC/AC Accessory Inverter 4.00b = HVIL Closed01b = HVIL Open10b = Error11b = Not Available…";
CM_ SG_ 2565923838 DCACAssrInvrtr4LdshdRqst "Loadshed Request from this DC/AC Accessory Inverter output.  The Loadshed Requested state is an indication that the inverter output powering this device has a m…";
CM_ SG_ 2565923838 DCACAssrInvrtr4OprtnlStts "Operating Status of this DC/AC Accessory Inverter output. The Inverter Output Faulted state will be communicated when the inverter output has shutdown due to an…";
CM_ BO_ 2565925374 "Aftertreatment 1 Intake Gas 3";
CM_ SG_ 2565925374 Aftrtrtmnt1IntkGsSnsr2HtrCntrl "Indicates the heater status in the warm-up process.  Upon receiving a power-up command, the second gas sensor ramps up according to a manufacturer defined profi…";
CM_ SG_ 2565925374 Aftrtrtmnt1IntkGsSnsr2PwrInRng "Indicates that the second measurement of power supplied to the aftertreatment intake gas sensor, either NOx or O2, is within the manufacturer's specification in…";
CM_ SG_ 2565925374 Aftrtrtmnt1IntkGsSnsr2tTmprtr "Indicates that the heater element of the aftertreatment intake gas second sensor, either NOx or O2, is within the manufacturer's specified range for accurate me…";
CM_ SG_ 2565925374 Aftrtrtmnt1IntkPrntOxgn2 "The second measurement of the actual oxidation factor (Percent Oxygen) of the gas within the exhaust stream. For positive values, the parameter represents the p…";
CM_ SG_ 2565925374 Atttt1ItGsSs2HtPFMI "Used to identify the second applicable J1939-73 FMI detected in the heater of the intake exhaust gas sensor, either NOx or O2, by the manufacturer’s sensor cont…";
CM_ SG_ 2565925374 Atttt1ItOxSs2PFMI "Used to identify the second applicable J1939-73 FMI detected in the aftertreatment intake oxygen sensor by the manufacturer’s sensor control software in exhaust…";
CM_ SG_ 2565925374 Atttt1ItWdRPtOx2RdSt "Indicates that the second measurement of the percent oxygen reading of the aftertreatment intake gas sensor, either NOx or O2, is stable as determined by the ma…";
CM_ SG_ 2565925374 EngineExhaust1NOx2 "The second measurement of the amount of combined NO and NO2 in the exhaust, represented in NOx molecule parts per million non-NOx molecules in exhaust bank 1.  …";
CM_ SG_ 2565925374 EngineExhaust1NOx2ReadingStable "Indicates that the NOx reading of the second NOx sensor is stable as determined by the manufacturer's control software in exhaust bank 1.  This sensor is locate…";
CM_ SG_ 2565925374 EngnExhst1NOxSnsr2PrlmnrFMI "Used to identify the applicable J1939-73 FMI detected in the second NOx sensor by the manufacturer’s sensor control software in exhaust bank 1.  In the case of …";
CM_ SG_ 2565925374 EngnExhst1NOxSnsr2SlfdgnssStts "Self-diagnosis result status for the second NOx sensor in Engine Exhaust Bank 1 (EEB1h).  This sensor is located at the intake of the aftertreatment system if a…";
CM_ BO_ 2565925630 "Aftertreatment 1 Outlet Gas 3";
CM_ SG_ 2565925630 Aftertreatment1OutletNOx2 "The second measurement of the amount of combined NO and NO2 in the exhaust exiting the aftertreatment system measured by a NOx sensor at the aftertreatment outl…";
CM_ SG_ 2565925630 Aftrtrtmnt1OtltGsSnsr2HtrCntrl "Indicates the heater status in the warm-up process.  Upon receiving a power-up command, the gas second sensor ramps up according to a manufacturer defined profi…";
CM_ SG_ 2565925630 Aftrtrtmnt1OtltGsSnsr2PwrInRng "Indicates that the second measurement of power supplied to the aftertreatment outlet gas sensor, either NOx or O2, is within the manufacturer's specification in…";
CM_ SG_ 2565925630 Aftrtrtmnt1OtltGsSnsr2tTmprtr "Indicates that the heater element of the aftertreatment outlet gas second sensor, either NOx or O2, is within the manufacturer's specified range for accurate me…";
CM_ SG_ 2565925630 Aftrtrtmnt1OtltNOx2RdngStl "Indicates that the NOx reading of the aftertreatment outlet NOx second sensor is stable as determined by the manufacturer's control software in exhaust bank 1.0…";
CM_ SG_ 2565925630 Aftrtrtmnt1OtltPrntOxgn2 "The second measurement of the actual oxidation factor (percent oxygen) of the gas within the exhaust stream.  For positive values, the parameter represents the …";
CM_ SG_ 2565925630 Atttt1OttGsSs2HtPFMI "Used to identify the applicable J1939-73 FMI detected in the heater of the outlet exhaust gas second sensor, either NOx or O2, by the manufacturer’s sensor cont…";
CM_ SG_ 2565925630 Atttt1OttNOxSs2PFMI "Used to identify the applicable J1939-73 FMI detected in the aftertreatment outlet NOx second sensor by the manufacturer’s sensor control software in exhaust ba…";
CM_ SG_ 2565925630 Atttt1OttNOxSs2SdssStts "Self-diagnosis result status for NOx second sensor ATO1 (Aftertreatment Outlet Bank 1)000b = Diagnosis not active001b = NOx Sensor ATO1 Self Diagnosis active fl…";
CM_ SG_ 2565925630 Atttt1OttOxSs2PFMI "Used to identify the applicable J1939-73 FMI detected in the aftertreatment outlet oxygen second sensor by the manufacturer’s sensor control software in exhaust…";
CM_ SG_ 2565925630 Atttt1OttWdRPtOx2RdSt "Indicates that the percent oxygen reading of the aftertreatment outlet gas second sensor, either NOx or O2, is stable as determined by the manufacturer's contro…";
CM_ BO_ 2565925886 "Aftertreatment 2 Intake Gas Sensor 2";
CM_ SG_ 2565925886 Aftrtrtmnt2IntkGsSnsr2HtrCntrl "Indicates the heater status in the warm-up process.  Upon receiving a power-up command, the second gas sensor ramps up according to a manufacturer defined profi…";
CM_ SG_ 2565925886 Aftrtrtmnt2IntkGsSnsr2PwrInRng "Indicates that the power supplied to the aftertreatment intake gas second sensor, either NOx or O2, is within the manufacturer's specification in exhaust bank 2…";
CM_ SG_ 2565925886 Aftrtrtmnt2IntkGsSnsr2tTmprtr "Indicates that the heater element of the aftertreatment intake gas second sensor, either NOx or O2, is within the manufacturer's specified range for accurate me…";
CM_ SG_ 2565925886 Aftrtrtmnt2IntkPrntOxgn2 "The actual oxidation factor (percent oxygen) of the gas within the exhaust stream.  For positive values, the parameter represents the percent oxygen in excess o…";
CM_ SG_ 2565925886 Atttt2ItGsSs2HtPFMI "Used to identify the applicable J1939-73 FMI detected in the heater of the intake exhaust gas second sensor, either NOx or O2, by the manufacturer’s sensor cont…";
CM_ SG_ 2565925886 Atttt2ItOxSs2PFMI "Used to identify the applicable J1939-73 FMI detected in the aftertreatment intake oxygen second sensor by the manufacturer’s sensor control software in exhaust…";
CM_ SG_ 2565925886 Atttt2ItWdRPtOx2RdSt "Indicates that the percent oxygen reading of the aftertreatment intake gas second sensor, either NOx or O2, is stable as determined by the manufacturer's contro…";
CM_ SG_ 2565925886 EExst2ItNOxSs2SdssStts "Self-diagnosis result status for NOx second sensor EEB2h (Engine Exhaust Bank 2).  This sensor is located at the intake of the aftertreatment system if an after…";
CM_ SG_ 2565925886 EngineExhaust2NOx2 "The amount of combined NO and NO2 in the exhaust measured by the second NOx sensor at the aftertreatment intake, represented in NOx molecule parts per million n…";
CM_ SG_ 2565925886 EngineExhaust2NOx2ReadingStable "Indicates that the NOx reading of the second NOx sensor is stable as determined by the manufacturer's control software in exhaust bank 2.  This sensor is locate…";
CM_ SG_ 2565925886 EngnExhst2NOxSnsr2PrlmnrFMI "Used to identify the applicable J1939-73 FMI detected in the second NOx sensor by the manufacturer’s sensor control software in exhaust bank 2.  This sensor is …";
CM_ BO_ 2565926142 "Aftertreatment 2 Outlet Gas Sensor 2";
CM_ SG_ 2565926142 Aftertreatment2OutletNOx2 "The amount of combined NO and NO2 in the exhaust entering the aftertreatment system measured by the second NOx sensor at the aftertreatment outlet, represented …";
CM_ SG_ 2565926142 Aftrtrtmnt2OtltGsSnsr2HtrCntrl "Indicates the heater status in the warm-up process.  Upon receiving a power-up command, the gas second sensor ramps up according to a manufacturer defined profi…";
CM_ SG_ 2565926142 Aftrtrtmnt2OtltGsSnsr2PwrInRng " Indicates that the power supplied to the aftertreatment outlet gas second sensor, either NOx or O2, is within the manufacturer's specification in exhaust bank …";
CM_ SG_ 2565926142 Aftrtrtmnt2OtltGsSnsr2tTmprtr "Indicates that the heater element of the aftertreatment outlet gas second sensor, either NOx or O2, is within the manufacturer's specified range for accurate me…";
CM_ SG_ 2565926142 Aftrtrtmnt2OtltNOx2RdngStl "Indicates that the NOx reading of the aftertreatment outlet NOx second sensor is stable as determined by the manufacturer's control software in exhaust bank 2.F…";
CM_ SG_ 2565926142 Aftrtrtmnt2OtltPrntOxgn2 "The actual oxidation factor (percent oxygen) of the gas within the exhaust stream.  For positive values, the parameter represents the percent oxygen in excess o…";
CM_ SG_ 2565926142 Atttt2OttGsSs2HtPFMI "Used to identify the applicable J1939-73 FMI detected in the heater of the outlet exhaust gas second sensor, either NOx or O2, by the manufacturer’s sensor cont…";
CM_ SG_ 2565926142 Atttt2OttNOxSs2PFMI "Used to identify the applicable J1939-73 FMI detected in the aftertreatment outlet NOx second sensor by the manufacturer’s sensor control software in exhaust ba…";
CM_ SG_ 2565926142 Atttt2OttNOxSs2SdssStts "Self-diagnosis result status for second NOx sensor ATO2 (Aftertreatment Outlet Bank 2)000b = Diagnosis not active001b = NOx Sensor ATO2 Self Diagnosis active fl…";
CM_ SG_ 2565926142 Atttt2OttOxSs2PFMI "Used to identify the applicable J1939-73 FMI detected in the aftertreatment outlet oxygen second sensor by the manufacturer’s sensor control software in exhaust…";
CM_ SG_ 2565926142 Atttt2OttWdRPtOx2RdSt "Indicates that the percent oxygen reading of the aftertreatment outlet gas second sensor, either NOx or O2, is stable as determined by the manufacturer's contro…";
CM_ BO_ 2565932286 "Engine Speed Sensor Information 2";
CM_ SG_ 2565932286 EngineSpeed4 "The engine speed as measured by speed sensor 4.Notes: This is for the engine speed from the 4th engine speed sensor. This may be different than SPN 190 when use…";
CM_ BO_ 2565932798 "Well Stimulation Pump System 1";
CM_ SG_ 2565932798 WllStmltnPmpDshrgPrssr "The pressure on the discharge side of the well stimulation pump.…";
CM_ SG_ 2565932798 WllStmltnPmpStnPrssr "The pressure on the suction side of the well stimulation pump.…";
CM_ BO_ 2565933054 "Well Stimulation Pump System 2";
CM_ SG_ 2565933054 WellStimulationPumpSpeed "The operating speed of the well stimulation pump.…";
CM_ SG_ 2565933054 WllStmltnPmpGrBxOlPrssr "The oil pressure measured in the well stimulation pump gear box.…";
CM_ SG_ 2565933054 WllStmltnPmpGrBxOlTmprtr "Temperature of the oil in the well stimulation pump gear box.…";
CM_ BO_ 2565934590 "Fuel Information 6 (Gaseous)";
CM_ SG_ 2565934590 EngnFlVlv2DffrntlPrssr "The differential pressure between the intake and the outlet of the second gaseous fuel valve.…";
CM_ BO_ 2565942014 "DC/AC Accessory Inverter 3 Feedback 2";
CM_ SG_ 2565942014 DCACAssIvt3PwLtddtACSdRMSCt "AC Side Output power is being limited due to AC Side output RMS current (see SPN 9202) approaching or exceeding the maximum limit (See SPN 9288).00b = No power …";
CM_ SG_ 2565942014 DCACAssIvt3PwLtddtCtTpt "Output power is being limited due to the controller temperature (see SPN 9261) approaching or exceeding the maximum limit.00b = No power limit for this reason01…";
CM_ SG_ 2565942014 DCACAssIvt3PwLtddtDCSdCt "Output power is being limited due to DC Side input current (see SPN 9268) approaching or exceeding the maximum limit (See SPN 9286).00b = No power limit for thi…";
CM_ SG_ 2565942014 DCACAssIvt3PwLtddtDCSdVtM "Output power is being limited due to DC Side input voltage (see SPN 9267) approaching or falling below the minimum limit  (SPN 9285).00b = No power limit for th…";
CM_ SG_ 2565942014 DCACAssIvt3PwLtddtEtFtTpt "Output power is being limited due to electronic filter temperature (see SPN 9262) approaching or exceeding the maximum limit.00b = No frequency limit for this r…";
CM_ SG_ 2565942014 DCACAssIvt3PwLtddtPwEtsTpt "Output power is being limited due to power electronics temperature (see SPN 9263) approaching or exceeding the maximum limit.00b = No frequency limit for this r…";
CM_ SG_ 2565942014 DCACAssIvt3PwLtddtRtCLt "Output power is being limited due to the frequency approaching or exceeding the rate of change limit (see SPN 8360).00b = No frequency limit for this reason01b …";
CM_ SG_ 2565942014 DCACAssIvt3PwLtddtUddRs "Output power is being limited due to an undefined reason.00b = No power limit for this reason01b = Power limited for this reason10b = Error11b = Not Available…";
CM_ SG_ 2565942014 DCACAssrInvrtr3FrqnCmmndlwMnmm "Output frequency is being limited due to frequency command (see SPN 8361) approaching or falling below the minimum limit (SPN 8357).00b = No frequency limit for…";
CM_ SG_ 2565942014 DCACAssrInvrtr3FrqnCmmndxdsMxmm "Output frequency is being limited due to frequency command (see SPN 8361) approaching or exceeding the maximum limit (SPN 8356).00b = No frequency limit for thi…";
CM_ BO_ 2565942782 "DC/AC Accessory Inverter 4 Feedback 2";
CM_ SG_ 2565942782 DCACAssIvt4PwLtddtACSdRMSCt "AC Side Output power is being limited due to AC Side output RMS current (see SPN 9203) approaching or exceeding the maximum limit (See SPN 9318).00b = No power …";
CM_ SG_ 2565942782 DCACAssIvt4PwLtddtCtTpt "Output power is being limited due to the controller temperature (see SPN 9291) approaching or exceeding the maximum limit.00b = No power limit for this reason01…";
CM_ SG_ 2565942782 DCACAssIvt4PwLtddtDCSdCt "Output power is being limited due to DC Side input current (see SPN 9298) approaching or exceeding the maximum limit (See SPN 9316).00b = No power limit for thi…";
CM_ SG_ 2565942782 DCACAssIvt4PwLtddtDCSdVtM "Output power is being limited due to DC Side input voltage (see SPN 9297) approaching or falling below the minimum limit (SPN 9315).00b = No power limit for thi…";
CM_ SG_ 2565942782 DCACAssIvt4PwLtddtEtFtTpt "Output power is being limited due to electronic filter temperature (see SPN 9292) approaching or exceeding the maximum limit.00b = No frequency limit for this r…";
CM_ SG_ 2565942782 DCACAssIvt4PwLtddtPwEtsTpt "Output power is being limited due to power electronics temperature (see SPN 9293) approaching or exceeding the maximum limit.00b = No frequency limit for this r…";
CM_ SG_ 2565942782 DCACAssIvt4PwLtddtRtCLt "Output power is being limited due to the frequency approaching or exceeding the rate of change limit (see SPN 8374).00b = No frequency limit for this reason01b …";
CM_ SG_ 2565942782 DCACAssIvt4PwLtddtUddRs "Output power is being limited due to an undefined reason.00b = No power limit for this reason01b = Power limited for this reason10b = Error11b = Not Available…";
CM_ SG_ 2565942782 DCACAssrInvrtr4FrqnCmmndlwMnmm "Output frequency is being limited due to frequency command (see SPN 8375) approaching or falling below the minimum limit (SPN 8371).00b = No frequency limit for…";
CM_ SG_ 2565942782 DCACAssrInvrtr4FrqnCmmndxdsMxmm "Output frequency is being limited due to frequency command (see SPN 8375) approaching or exceeding the maximum limit (SPN 8370).00b = No frequency limit for thi…";
CM_ BO_ 2565943038 "DC/AC Accessory Inverter 5 Command";
CM_ SG_ 2565943038 DCACAssIvt5ACSdMtSttRMSVtRqst "Signal to the DC/AC Accessory Inverter indicating the requested AC side RMS voltage for starting the attached accessory motor.   In a V/Hz variable speed motor …";
CM_ SG_ 2565943038 DCACAssrInvrtr5Dv1Stts "Signal to the DC/AC Accessory Inverter indicating the state of the device attached to the inverter output.  Each output may control multiple devices (e.g. elect…";
CM_ SG_ 2565943038 DCACAssrInvrtr5Dv2Stts "Signal to the DC/AC Accessory Inverter indicating the state of the device attached to the inverter output.  Each output may control multiple devices (e.g. elect…";
CM_ SG_ 2565943038 DCACAssrInvrtr5DvFrqnRtfChngLmt "Signal to the DC/AC Accessory Inverter indicating the frequency rate of change limit of the device(s) attached to the inverter output (Note: Increasing and decr…";
CM_ SG_ 2565943038 DCACAssrInvrtr5DvMnmmFrqn "Signal to the DC/AC Accessory Inverter indicating the minimum frequency of the device(s) attached to the inverter output.  Each output may control multiple devi…";
CM_ SG_ 2565943038 DCACAssrInvrtr5DvMxmmFrqn "Signal to the DC/AC Accessory Inverter indicating the maximum frequency of the devices(s) attached to the inverter output.  Each output may control multiple dev…";
CM_ SG_ 2565943038 DCACAssrInvrtr5DvRtdFrqn "Signal to the DC/AC Accessory Inverter indicating the rated frequency of the device(s) attached to the inverter output.  Each output may control multiple device…";
CM_ SG_ 2565943038 DCACAssrInvrtr5DvRtdRMSVltg "Signal to the DC/AC Accessory Inverter indicating the rated RMS voltage of the device(s) attached to the inverter output.   Each output may control multiple dev…";
CM_ SG_ 2565943038 DCACAssrInvrtr5FrqnCmmnd "Command to the DC/AC Accessory Inverter indicating the Inverter frequency desired for the device(s) attached to the inverter output.  Each output may control mu…";
CM_ SG_ 2565943038 DCACAssrInvrtr5OprtnlCmmnd "Command to the DC/AC Accessory Inverter to enable this output.  Each output may control multiple devices (e.g. electric motors) if they all operate at the same …";
CM_ BO_ 2565943294 "DC/AC Accessory Inverter 5 Feedback";
CM_ SG_ 2565943294 DCACAccessoryInverter5Frequency "Present operating frequency of this DC/AC Accessory Inverter output.…";
CM_ SG_ 2565943294 DCACAssrInvrtr5ACSdPwr "Present operating AC Side power of this DC/AC Accessory Inverter output.…";
CM_ SG_ 2565943294 DCACAssrInvrtr5ACSdRMSCrrnt "Present operating AC Side output RMS line Current of this DC/AC Accessory Inverter.  When connected to a balanced three phase motor, this would be the current i…";
CM_ SG_ 2565943294 DCACAssrInvrtr5ACSdRMSVltg "Present operating AC Side line to line RMS voltage of this DC/AC Accessory Inverter output.  In a three phase balanced motor, this is the RMS voltage across one…";
CM_ SG_ 2565943294 DCACAssrInvrtr5HVILStts "High Voltage Interlock Loop (HVIL) state of the DC/AC Accessory Inverter 5.00b = HVIL Closed01b = HVIL Open10b = Error11b = Not Available…";
CM_ SG_ 2565943294 DCACAssrInvrtr5LdshdRqst "Loadshed Request from this DC/AC Accessory Inverter output.  The Loadshed Requested state is an indication that the inverter output powering this device has a m…";
CM_ SG_ 2565943294 DCACAssrInvrtr5OprtnlStts "Operating Status of this DC/AC Accessory Inverter output. The Inverter Output Faulted state will be communicated when the inverter output has shutdown due to an…";
CM_ BO_ 2565944062 "DC/AC Accessory Inverter 5 Feedback 2";
CM_ SG_ 2565944062 DCACAssIvt5PwLtddtACSdRMSCt "AC Side Output power is being limited due to AC Side output RMS current (see SPN 9333) approaching or exceeding the maximum limit (See SPN 9364).00b = No power …";
CM_ SG_ 2565944062 DCACAssIvt5PwLtddtCtTpt "Output power is being limited due to the controller temperature (see SPN 9337) approaching or exceeding the maximum limit.00b = No power limit for this reason01…";
CM_ SG_ 2565944062 DCACAssIvt5PwLtddtDCSdCt "Output power is being limited due to DC Side input current (see SPN 9344) approaching or exceeding the maximum limit (See SPN 9362).00b = No power limit for thi…";
CM_ SG_ 2565944062 DCACAssIvt5PwLtddtDCSdVtM "Output power is being limited due to DC Side input voltage (see SPN 9343) approaching or falling below the minimum limit (SPN 9361).00b = No power limit for thi…";
CM_ SG_ 2565944062 DCACAssIvt5PwLtddtEtFtTpt "Output power is being limited due to electronic filter temperature (see SPN 9338) approaching or exceeding the maximum limit.00b = No frequency limit for this r…";
CM_ SG_ 2565944062 DCACAssIvt5PwLtddtPwEtsTpt "Output power is being limited due to power electronics temperature (see SPN 9339) approaching or exceeding the maximum limit.00b = No frequency limit for this r…";
CM_ SG_ 2565944062 DCACAssIvt5PwLtddtRtCLt "Output power is being limited due to the frequency approaching or exceeding the rate of change limit (see SPN 9325).00b = No frequency limit for this reason01b …";
CM_ SG_ 2565944062 DCACAssIvt5PwLtddtUddRs "Output power is being limited due to an undefined reason.00b = No power limit for this reason01b = Power limited for this reason10b = Error11b = Not Available…";
CM_ SG_ 2565944062 DCACAssrInvrtr5FrqnCmmndlwMnmm "Output frequency is being limited due to frequency command (see SPN 9326) approaching or falling below the minimum limit (SPN 9322).00b = No frequency limit for…";
CM_ SG_ 2565944062 DCACAssrInvrtr5FrqnCmmndxdsMxmm "Output frequency is being limited due to frequency command (see SPN 9326) approaching or exceeding the maximum limit (SPN 9321).00b = No frequency limit for thi…";
CM_ BO_ 2566624510 "Electronic Engine Controller 22";
CM_ SG_ 2566624510 EngnExhstGsRrltn1ClrIntkPrssr "Exhaust gas recirculation gage pressure is measured at the EGR cooler intake.…";
CM_ BO_ 2566624766 "Engine Hours 2";
CM_ SG_ 2566624766 EngnIdlMngmntAtvTtlTm "Total accumulated time the engine is off due to the engine idle management system.…";
CM_ BO_ 2566625022 "Engine Information 3";
CM_ SG_ 2566625022 InstntnsEstmtdEngnPwrRtLmt "Estimate of the maximum power load rate the engine can sustain at that moment in time.…";
CM_ BO_ 2566625278 "Vehicle Electrical Power 15";
CM_ SG_ 2566625278 SLIBttrPk1Bttr1CptSttng "Informs the battery controller of the capacity of its associated battery.  This parameter applies to the first battery in the first set of batteries (battery pa…";
CM_ SG_ 2566625278 SLIBttrPk1Bttr2CptSttng "Informs the battery controller of the capacity of its associated battery.  This parameter applies to the second battery in the first set of batteries (battery p…";
CM_ SG_ 2566625278 SLIBttrPk1Bttr3CptSttng "Informs the battery controller of the capacity of its associated battery.  This parameter applies to the third battery in the first set of batteries (battery pa…";
CM_ SG_ 2566625278 SLIBttrPk1Bttr4CptSttng "Informs the battery controller of the capacity of its associated battery.  This parameter applies to the fourth battery in the first set of batteries (battery p…";
CM_ BO_ 2566625790 "DC/AC Accessory Inverter 1 Temperatures";
CM_ SG_ 2566625790 DCACAssIvt1IvtEtFtTpt "Temperature of the electronic components that make up the DC/AC Accessory Inverter filter.…";
CM_ SG_ 2566625790 DCACAssrInvrtr1ClntInTmprtr "Temperature of the DC/AC Accessory Inverter Coolant measured at the input of the accessory inverter.…";
CM_ SG_ 2566625790 DCACAssrInvrtr1ClntOtTmprtr "Temperature of the DC/AC Accessory Inverter Coolant measured at the output of the accessory inverter.…";
CM_ SG_ 2566625790 DCACAssrInvrtr1CntrllrTmprtr "Temperature of the DC/AC Accessory Inverter (e.g, controller, circuit board, enclosure).…";
CM_ SG_ 2566625790 DCACAssrInvrtr1PwrEltrnsTmprtr "Temperature of the DC/AC Accessory Inverter power electronics components (e.g, switch or heatsink).…";
CM_ BO_ 2566626558 "DC/AC Accessory Inverter 1 Configuration 1";
CM_ SG_ 2566626558 DCACAssIvt1ACSdDtFqCdStt "Reports the active AC Side Default Frequency Command Setting of the DC/AC Accessory Inverter.  The setting may be requested by a separate device (via SPN 9523).…";
CM_ SG_ 2566626558 DCACAssIvt1ACSdRMSCtMxLtStt "Reports the active maximum limit on the AC side output RMS line current of the DC/AC Accessory Inverter.  The setting may be requested by a separate device (via…";
CM_ SG_ 2566626558 DCACAssIvt1ACSdRMSVtMxLtStt "Reports the active maximum limit on the AC Side output line to line RMS voltage of the DC/AC Accessory Inverter.  The setting may be requested by a separate dev…";
CM_ SG_ 2566626558 DCACAssIvt1DCSdCtMLtStt "Reports the active minimum limit on the DC Side input current of the DC/AC Accessory Inverter.  The setting may be requested by a separate device (via SPN 9530)…";
CM_ SG_ 2566626558 DCACAssIvt1DCSdCtMxLtStt "Reports the active maximum limit on the DC Side input current of the DC/AC Accessory Inverter.  The setting may be requested by a separate device (via SPN 9222)…";
CM_ SG_ 2566626558 DCACAssIvt1DCSdVtMLtStt "Reports the active minimum limit on the DC Side input voltage of the DC/AC Accessory Inverter.  The setting may be requested by a separate device (via SPN 9221)…";
CM_ SG_ 2566626558 DCACAssIvt1DCSdVtMxLtStt "Reports the active maximum limit on the DC Side input voltage of the DC/AC Accessory Inverter.  The setting may be requested by a separate device (via SPN 9529)…";
CM_ BO_ 2566626814 "DC/AC Accessory Inverter 1 Lifetime Data";
CM_ SG_ 2566626814 DCACAssrInvrtr1TtlDCInptChrg "Total lifetime charge converted by the DC/AC from the DC Side.  …";
CM_ SG_ 2566626814 DCACAssrInvrtr1TtlDCInptEnrg "Total lifetime energy converted by the DC/AC from the DC Side.…";
CM_ BO_ 2566627070 "DC/AC Accessory Inverter 2 Temperatures";
CM_ SG_ 2566627070 DCACAssIvt2IvtEtFtTpt "Temperature of the electronic components that make up the DC/AC Accessory Inverter filter.…";
CM_ SG_ 2566627070 DCACAssrInvrtr2ClntInTmprtr "Temperature of the DC/AC Accessory Inverter Coolant measured at the input of the accessory inverter.…";
CM_ SG_ 2566627070 DCACAssrInvrtr2ClntOtTmprtr "Temperature of the DC/AC Accessory Inverter Coolant measured at the output of the accessory inverter.…";
CM_ SG_ 2566627070 DCACAssrInvrtr2CntrllrTmprtr "Temperature of the DC/AC Accessory Inverter (e.g, controller, circuit board, enclosure).…";
CM_ SG_ 2566627070 DCACAssrInvrtr2PwrEltrnsTmprtr "Temperature of the DC/AC Accessory Inverter power electronics components (e.g, switch or heatsink).…";
CM_ BO_ 2566627838 "DC/AC Accessory Inverter 2 Configuration 1";
CM_ SG_ 2566627838 DCACAssIvt2ACSdDtFqCdStt "Reports the active AC Side Default Frequency Command Setting of the DC/AC Accessory Inverter.  The setting may be requested by a separate device (via SPN 9524).…";
CM_ SG_ 2566627838 DCACAssIvt2ACSdRMSCtMxLtStt "Reports the active maximum limit on the AC side output RMS line current of the DC/AC Accessory Inverter.  The setting may be requested by a separate device (via…";
CM_ SG_ 2566627838 DCACAssIvt2ACSdRMSVtMxLtStt "Reports the active maximum limit on the AC Side output line to line RMS voltage of the DC/AC Accessory Inverter.  The setting may be requested by a separate dev…";
CM_ SG_ 2566627838 DCACAssIvt2DCSdCtMLtStt "Reports the active minimum limit on the DC Side input current of the DC/AC Accessory Inverter.  The setting may be requested by a separate device (via SPN 9536)…";
CM_ SG_ 2566627838 DCACAssIvt2DCSdCtMxLtStt "Reports the active maximum limit on the DC Side input current of the DC/AC Accessory Inverter.  The setting may be requested by a separate device (via SPN 9252)…";
CM_ SG_ 2566627838 DCACAssIvt2DCSdVtMLtStt "Reports the active minimum limit on the DC Side input voltage of the DC/AC Accessory Inverter.  The setting may be requested by a separate device (via SPN 9251)…";
CM_ SG_ 2566627838 DCACAssIvt2DCSdVtMxLtStt "Reports the active maximum limit on the DC Side input voltage of the DC/AC Accessory Inverter.  The setting may be requested by a separate device (via SPN 9535)…";
CM_ BO_ 2566628094 "DC/AC Accessory Inverter 2 Lifetime Data";
CM_ SG_ 2566628094 DCACAssrInvrtr2TtlDCInptChrg "Total lifetime charge converted by the DC/AC from the DC Side.  …";
CM_ SG_ 2566628094 DCACAssrInvrtr2TtlDCInptEnrg "Total lifetime energy converted by the DC/AC from the DC Side.…";
CM_ BO_ 2566628350 "DC/AC Accessory Inverter 3 Temperatures";
CM_ SG_ 2566628350 DCACAssIvt3IvtEtFtTpt "Temperature of the electronic components that make up the DC/AC Accessory Inverter filter.…";
CM_ SG_ 2566628350 DCACAssrInvrtr3ClntInTmprtr "Temperature of the DC/AC Accessory Inverter Coolant measured at the input of the accessory inverter.…";
CM_ SG_ 2566628350 DCACAssrInvrtr3ClntOtTmprtr "Temperature of the DC/AC Accessory Inverter Coolant measured at the output of the accessory inverter.…";
CM_ SG_ 2566628350 DCACAssrInvrtr3CntrllrTmprtr "Temperature of the DC/AC Accessory Inverter (e.g, controller, circuit board, enclosure).…";
CM_ SG_ 2566628350 DCACAssrInvrtr3PwrEltrnsTmprtr "Temperature of the DC/AC Accessory Inverter power electronics components (e.g, switch or heatsink).…";
CM_ BO_ 2566629118 "DC/AC Accessory Inverter 3 Configuration 1";
CM_ SG_ 2566629118 DCACAssIvt3ACSdDtFqCdStt "Reports the active AC Side Default Frequency Command Setting of the DC/AC Accessory Inverter.  The setting may be requested by a separate device (via SPN 9525).…";
CM_ SG_ 2566629118 DCACAssIvt3ACSdRMSCtMxLtStt "Reports the active maximum limit on the AC side output RMS line current of the DC/AC Accessory Inverter.  The setting may be requested by a separate device (via…";
CM_ SG_ 2566629118 DCACAssIvt3ACSdRMSVtMxLtStt "Reports the active maximum limit on the AC Side output line to line RMS voltage of the DC/AC Accessory Inverter.  The setting may be requested by a separate dev…";
CM_ SG_ 2566629118 DCACAssIvt3DCSdCtMLtStt "Reports the active minimum limit on the DC Side input current of the DC/AC Accessory Inverter.  The setting may be requested by a separate device (via SPN 9542)…";
CM_ SG_ 2566629118 DCACAssIvt3DCSdCtMxLtStt "Reports the active maximum limit on the DC Side input current of the DC/AC Accessory Inverter.  The setting may be requested by a separate device (via SPN 9282)…";
CM_ SG_ 2566629118 DCACAssIvt3DCSdVtMLtStt "Reports the active minimum limit on the DC Side input voltage of the DC/AC Accessory Inverter.  The setting may be requested by a separate device (via SPN 9281)…";
CM_ SG_ 2566629118 DCACAssIvt3DCSdVtMxLtStt "Reports the active maximum limit on the DC Side input voltage of the DC/AC Accessory Inverter.  The setting may be requested by a separate device (via SPN 9541 …";
CM_ BO_ 2566629374 "DC/AC Accessory Inverter 3 Lifetime Data";
CM_ SG_ 2566629374 DCACAssrInvrtr3TtlDCInptChrg "Total lifetime charge converted by the DC/AC from the DC Side.  …";
CM_ SG_ 2566629374 DCACAssrInvrtr3TtlDCInptEnrg "Total lifetime energy converted by the DC/AC from the DC Side.…";
CM_ BO_ 2566629630 "DC/AC Accessory Inverter 4 Temperatures";
CM_ SG_ 2566629630 DCACAssIvt4IvtEtFtTpt "Temperature of the electronic components that make up the DC/AC Accessory Inverter filter.…";
CM_ SG_ 2566629630 DCACAssrInvrtr4ClntInTmprtr "Temperature of the DC/AC Accessory Inverter Coolant measured at the input of the accessory inverter.…";
CM_ SG_ 2566629630 DCACAssrInvrtr4ClntOtTmprtr "Temperature of the DC/AC Accessory Inverter Coolant measured at the output of the accessory inverter.…";
CM_ SG_ 2566629630 DCACAssrInvrtr4CntrllrTmprtr "Temperature of the DC/AC Accessory Inverter (e.g, controller, circuit board, enclosure).…";
CM_ SG_ 2566629630 DCACAssrInvrtr4PwrEltrnsTmprtr "Temperature of the DC/AC Accessory Inverter power electronics components (e.g, switch or heatsink).…";
CM_ BO_ 2566630398 "DC/AC Accessory Inverter 4 Configuration 1";
CM_ SG_ 2566630398 DCACAssIvt4ACSdDtFqCdStt "Reports the active AC Side Default Frequency Command Setting of the DC/AC Accessory Inverter.  The setting may be requested by a separate device (via SPN 9526).…";
CM_ SG_ 2566630398 DCACAssIvt4ACSdRMSCtMxLtStt "Reports the active maximum limit on the AC side output RMS line current of the DC/AC Accessory Inverter.  The setting may be requested by a separate device (via…";
CM_ SG_ 2566630398 DCACAssIvt4ACSdRMSVtMxLtStt "Reports the active maximum limit on the AC Side output line to line RMS voltage of the DC/AC Accessory Inverter.  The setting may be requested by a separate dev…";
CM_ SG_ 2566630398 DCACAssIvt4DCSdCtMLtStt "Reports the active minimum limit on the DC Side input current of the DC/AC Accessory Inverter.  The setting may be requested by a separate device (via SPN 9548)…";
CM_ SG_ 2566630398 DCACAssIvt4DCSdCtMxLtStt "Reports the active maximum limit on the DC Side input current of the DC/AC Accessory Inverter.  The setting may be requested by a separate device (via SPN 9312)…";
CM_ SG_ 2566630398 DCACAssIvt4DCSdVtMLtStt "Reports the active minimum limit on the DC Side input voltage of the DC/AC Accessory Inverter.  The setting may be requested by a separate device (via SPN 9311)…";
CM_ SG_ 2566630398 DCACAssIvt4DCSdVtMxLtStt "Reports the active maximum limit on the DC Side input voltage of the DC/AC Accessory Inverter.  The setting may be requested by a separate device (via SPN 9547)…";
CM_ BO_ 2566630654 "DC/AC Accessory Inverter 4 Lifetime Data";
CM_ SG_ 2566630654 DCACAssrInvrtr4TtlDCInptChrg "Total lifetime charge converted by the DC/AC from the DC Side.  …";
CM_ SG_ 2566630654 DCACAssrInvrtr4TtlDCInptEnrg "Total lifetime energy converted by the DC/AC from the DC Side.…";
CM_ BO_ 2566630910 "DC/AC Accessory Inverter 5 Temperatures";
CM_ SG_ 2566630910 DCACAssIvt5IvtEtFtTpt "Temperature of the electronic components that make up the DC/AC Accessory Inverter filter.…";
CM_ SG_ 2566630910 DCACAssrInvrtr5ClntInTmprtr "Temperature of the DC/AC Accessory Inverter Coolant measured at the input of the accessory inverter.…";
CM_ SG_ 2566630910 DCACAssrInvrtr5ClntOtTmprtr "Temperature of the DC/AC Accessory Inverter Coolant measured at the output of the accessory inverter.…";
CM_ SG_ 2566630910 DCACAssrInvrtr5CntrllrTmprtr "Temperature of the DC/AC Accessory Inverter (e.g, controller, circuit board, enclosure).…";
CM_ SG_ 2566630910 DCACAssrInvrtr5PwrEltrnsTmprtr "Temperature of the DC/AC Accessory Inverter power electronics components (e.g, switch or heatsink).…";
CM_ BO_ 2566631678 "DC/AC Accessory Inverter 5 Configuration 1";
CM_ SG_ 2566631678 DCACAssIvt5ACSdDtFqCdStt "Reports the active AC Side Default Frequency Command Setting of the DC/AC Accessory Inverter.  The setting may be requested by a separate device (via SPN 9527).…";
CM_ SG_ 2566631678 DCACAssIvt5ACSdRMSCtMxLtStt "Reports the active maximum limit on the AC side output RMS line current of the DC/AC Accessory Inverter.  The setting may be requested by a separate device (via…";
CM_ SG_ 2566631678 DCACAssIvt5ACSdRMSVtMxLtStt "Reports the active maximum limit on the AC Side output line to line RMS voltage of the DC/AC Accessory Inverter.  The setting may be requested by a separate dev…";
CM_ SG_ 2566631678 DCACAssIvt5DCSdCtMLtStt "Reports the active minimum limit on the DC Side input current of the DC/AC Accessory Inverter.  The setting may be requested by a separate device (via SPN 9554)…";
CM_ SG_ 2566631678 DCACAssIvt5DCSdCtMxLtStt "Reports the active maximum limit on the DC Side input current of the DC/AC Accessory Inverter.  The setting may be requested by a separate device (via SPN 9358)…";
CM_ SG_ 2566631678 DCACAssIvt5DCSdVtMLtStt "Reports the active minimum limit on the DC Side input voltage of the DC/AC Accessory Inverter.  The setting may be requested by a separate device (via SPN 9357)…";
CM_ SG_ 2566631678 DCACAssIvt5DCSdVtMxLtStt "Reports the active maximum limit on the DC Side input voltage of the DC/AC Accessory Inverter.  The setting may be requested by a separate device (via SPN 9553)…";
CM_ BO_ 2566631934 "DC/AC Accessory Inverter 5 Lifetime Data";
CM_ SG_ 2566631934 DCACAssrInvrtr5TtlDCInptChrg "Total lifetime charge converted by the DC/AC from the DC Side.  …";
CM_ SG_ 2566631934 DCACAssrInvrtr5TtlDCInptEnrg "Total lifetime energy converted by the DC/AC from the DC Side.…";
CM_ BO_ 2566632190 "Well Stimulation Pump Sensor Calibration Status";
CM_ SG_ 2566632190 WllStmltnPmpStnPrssrClrtnStPnt "Specifies the current suction pressure whose calibration status is being reported. Multipoint calibration of the suction pressure system is perfomed by increasi…";
CM_ SG_ 2566632190 WSttPpDsPssCtStPt "Specifies the current discharge pressure whose calibration status is being reported. Multipoint calibration of the discharge pressure system is perfomed by incr…";
CM_ SG_ 2566632190 WSttPpDsPssCtStPtStts "Indicates the state of the Calibrated Sensor.00b = Not OK01b = OK10b = Error11b = Not available…";
CM_ SG_ 2566632190 WSttPpStPssCtStPtStts "Indicates the state of the Calibrated Sensor.00b = Not OK01b = OK10b = Error11b = Not available…";
CM_ BO_ 2566632446 "Well Stimulation Pump Fluid Volume";
CM_ SG_ 2566632446 WllStmltnPmpTrpFldPmpd "Fluid pumped during all or part of a well stimulation operation.…";
CM_ SG_ 2566632446 WllStmltnPmpTtlFldPmpd "Accumulated amount of fluid pumped during well stimulation operation.…";
CM_ BO_ 2566632702 "Well Stimulation Pump Serial Number";
CM_ SG_ 2566632702 WllStmltnPmpFldEndSrlNmr "The serial number of the fluid end of a well stimulation pump.…";
CM_ SG_ 2566632702 WllStmltnPmpPwrEndSrlNmr "The serial number of the power end of a well stimulation pump.…";
CM_ BO_ 2566632958 "Well Stimulation Pump Trip Hours";
CM_ SG_ 2566632958 WllStmltnPmpFldEndTrpHrs "The hours accumulated since the last fluid end replacement on the well stimulation pump (since the last reset of the trip meter).This value will be reset by the…";
CM_ SG_ 2566632958 WllStmltnPmpPwrEndTrpHrs "The hours accumulated since the last power end replacement on the well stimulation pump (since the last reset of the trip meter).This value will be reset by the…";
CM_ BO_ 2566633214 "Aftertreatment 1 Outlet Gas 4";
CM_ SG_ 2566633214 Aftrtrtmnt1OtltOxgnPmpngCrrnt "Electrical pumping current directly measured from a Lambda sensor for the purpose of calculating an air/fuel ratio.  This sensor is located closest to the outle…";
CM_ BO_ 2566633470 "Aftertreatment 1 Intake Gas 4";
CM_ SG_ 2566633470 Aftrtrtmnt1IntkOxgnPmpngCrrnt "Electrical pumping current directly measured from a Lambda sensor for the purpose of calculating an air/fuel ratio.  This sensor is located furthest upstream of…";
CM_ BO_ 2566633726 "DC/DC Converter 4 Lifetime Data";
CM_ SG_ 2566633726 DCDC4TotalHighSideCharge "Indicates the total lifetime charge converted by the DC/DC from the high side (e.g. HVES) during buck mode.  …";
CM_ SG_ 2566633726 DCDC4TotalHighSideEnergy "Indicates the total lifetime energy converted by the DC/DC from the high side (e.g. HVES) during buck mode.…";
CM_ SG_ 2566633726 DCDC4TotalLowSideCharge "Indicates the total lifetime charge converted by the DC/DC  from the low side (e.g. SLI battery) during boost mode.…";
CM_ SG_ 2566633726 DCDC4TotalLowSideEnergy "Indicates the total lifetime energy converted by the DC/DC  from the low side (e.g. SLI battery) during boost mode.…";
CM_ BO_ 2566633982 "DC/DC Converter 4 Configuration 1";
CM_ SG_ 2566633982 DCDC4HghSdCrrntMxmmLmtSttng "Reports the active maximum limit on the high side current of the DC/DC Converter.  The setting may be requested by a separate device (see SPN 9056) or determine…";
CM_ SG_ 2566633982 DCDC4HghSdVltgMnmmLmtSttng "Reports the active minimum limit on the high side voltage of the DC/DC Converter.  The setting may be requested by a separate device (see SPN 9054) or determine…";
CM_ SG_ 2566633982 DCDC4HghSdVltgMxmmLmtSttng "Reports the active maximum limit on the high side voltage of the DC/DC Converter.  The setting may be requested by a separate device (see SPN 9055) or determine…";
CM_ SG_ 2566633982 DCDC4LwSdCrrntMxmmLmtSttng "Reports the active maximum limit on the low side current of the DC/DC Converter.  The setting may be requested by a separate device (see SPN 9053) or determined…";
CM_ SG_ 2566633982 DCDC4LwSdVltgBkDfltSttng "Reports the converter active Low Side Voltage Buck Default Setting.  The default may be requested by a separate device (via SPN 9518).Note: Report Not Available…";
CM_ SG_ 2566633982 DCDC4LwSdVltgMnmmLmtSttng "Reports the active minimum limit on the low side voltage of the DC/DC Converter.  The setting may be requested by a separate device(see SPN 9051) or determined …";
CM_ SG_ 2566633982 DCDC4LwSdVltgMxmmLmtSttng "Reports the active maximum limit on the low side voltage of the DC/DC Converter.  The setting may be requested by a separate device (see SPN 9052) or determined…";
CM_ SG_ 2566633982 DCDC4SLIBttrTmprtrMxmmLmtSttng "Reports the active SLI Battery Temperature maximum limit.  The setting may be requested by a separate device (see SPN 9045) or determined by the DC/DC Controlle…";
CM_ SG_ 2566633982 DCDC4SLIBttTCCtMxLtStt "Reports the active SLI Battery charging current maximum limit (at the battery terminals).  The setting may be requested by a separate device (see SPN 9044) or d…";
CM_ SG_ 2566633982 DCDC4SLIBttTVtMxLtStt "Reports the active SLI Battery Voltage maximum limit (at the battery terminals).  The setting may be requested by a separate device (see SPN 9043) or determined…";
CM_ BO_ 2566635262 "DC/DC Converter 3 Lifetime Data";
CM_ SG_ 2566635262 DCDC3TotalHighSideCharge "Indicates the total lifetime charge converted by the DC/DC from the high side (e.g. HVES) during buck mode.  …";
CM_ SG_ 2566635262 DCDC3TotalHighSideEnergy "Indicates the total lifetime energy converted by the DC/DC from the high side (e.g. HVES) during buck mode.…";
CM_ SG_ 2566635262 DCDC3TotalLowSideCharge "Indicates the total lifetime charge converted by the DC/DC  from the low side (e.g. SLI battery) during boost mode.…";
CM_ SG_ 2566635262 DCDC3TotalLowSideEnergy "Indicates the total lifetime energy converted by the DC/DC  from the low side (e.g. SLI battery) during boost mode.…";
CM_ BO_ 2566635518 "DC/DC Converter 3 Configuration 1";
CM_ SG_ 2566635518 DCDC3HghSdCrrntMxmmLmtSttng "Reports the active maximum limit on the high side current of the DC/DC Converter.  The setting may be requested by a separate device (see SPN 9001) or determine…";
CM_ SG_ 2566635518 DCDC3HghSdVltgMnmmLmtSttng "Reports the active minimum limit on the high side voltage of the DC/DC Converter.  The setting may be requested by a separate device (see SPN 8999) or determine…";
CM_ SG_ 2566635518 DCDC3HghSdVltgMxmmLmtSttng "Reports the active maximum limit on the high side voltage of the DC/DC Converter.  The setting may be requested by a separate device (see SPN 9000) or determine…";
CM_ SG_ 2566635518 DCDC3LwSdCrrntMxmmLmtSttng "Reports the active maximum limit on the low side current of the DC/DC Converter.  The setting may be requested by a separate device (see SPN 8998) or determined…";
CM_ SG_ 2566635518 DCDC3LwSdVltgBkDfltSttng "Reports the converter active Low Side Voltage Buck Default Setting.  The default may be requested by a separate device (via SPN 9517).Note: Report Not Available…";
CM_ SG_ 2566635518 DCDC3LwSdVltgMnmmLmtSttng "Reports the active minimum limit on the low side voltage of the DC/DC Converter.  The setting may be requested by a separate device(see SPN 8996) or determined …";
CM_ SG_ 2566635518 DCDC3LwSdVltgMxmmLmtSttng "Reports the active maximum limit on the low side voltage of the DC/DC Converter.  The setting may be requested by a separate device (see SPN 8997) or determined…";
CM_ SG_ 2566635518 DCDC3SLIBttrTmprtrMxmmLmtSttng "Reports the active SLI Battery Temperature maximum limit.  The setting may be requested by a separate device (see SPN 8990) or determined by the DC/DC Controlle…";
CM_ SG_ 2566635518 DCDC3SLIBttTCCtMxLtStt "Reports the active SLI Battery charging current maximum limit (at the battery terminals).  The setting may be requested by a separate device (see SPN 8989) or d…";
CM_ SG_ 2566635518 DCDC3SLIBttTVtMxLtStt "Reports the active SLI Battery Voltage maximum limit (at the battery terminals).  The setting may be requested by a separate device (see SPN 8988) or determined…";
CM_ BO_ 2566636798 "DC/DC Converter 2 Lifetime Data";
CM_ SG_ 2566636798 DCDC2TotalHighSideCharge "Indicates the total lifetime charge converted by the DC/DC from the high side (e.g. HVES) during buck mode.  …";
CM_ SG_ 2566636798 DCDC2TotalHighSideEnergy "Indicates the total lifetime energy converted by the DC/DC from the high side (e.g. HVES) during buck mode.…";
CM_ SG_ 2566636798 DCDC2TotalLowSideCharge "Indicates the total lifetime charge converted by the DC/DC  from the low side (e.g. SLI battery) during boost mode.…";
CM_ SG_ 2566636798 DCDC2TotalLowSideEnergy "Indicates the total lifetime energy converted by the DC/DC  from the low side (e.g. SLI battery) during boost mode.…";
CM_ BO_ 2566637054 "DC/DC Converter 2 Configuration 1";
CM_ SG_ 2566637054 DCDC2HghSdCrrntMxmmLmtSttng "Reports the active maximum limit on the high side current of the DC/DC Converter.  The setting may be requested by a separate device (see SPN 8946) or determine…";
CM_ SG_ 2566637054 DCDC2HghSdVltgMnmmLmtSttng "Reports the active minimum limit on the high side voltage of the DC/DC Converter.  The setting may be requested by a separate device (see SPN 8944) or determine…";
CM_ SG_ 2566637054 DCDC2HghSdVltgMxmmLmtSttng "Reports the active maximum limit on the high side voltage of the DC/DC Converter.  The setting may be requested by a separate device (see SPN 8945) or determine…";
CM_ SG_ 2566637054 DCDC2LwSdCrrntMxmmLmtSttng "Reports the active maximum limit on the low side current of the DC/DC Converter.  The setting may be requested by a separate device (see SPN 8943) or determined…";
CM_ SG_ 2566637054 DCDC2LwSdVltgBkDfltSttng "Reports the converter active Low Side Voltage Buck Default Setting.  The default may be requested by a separate device (via SPN 9516).Note: Report Not Available…";
CM_ SG_ 2566637054 DCDC2LwSdVltgMnmmLmtSttng "Reports the active minimum limit on the low side voltage of the DC/DC Converter.  The setting may be requested by a separate device(see SPN 8941) or determined …";
CM_ SG_ 2566637054 DCDC2LwSdVltgMxmmLmtSttng "Reports the active maximum limit on the low side voltage of the DC/DC Converter.  The setting may be requested by a separate device (see SPN 8942) or determined…";
CM_ SG_ 2566637054 DCDC2SLIBttrTmprtrMxmmLmtSttng "Reports the active SLI Battery Temperature maximum limit.  The setting may be requested by a separate device (see SPN 8935) or determined by the DC/DC Controlle…";
CM_ SG_ 2566637054 DCDC2SLIBttTCCtMxLtStt "Reports the active SLI Battery charging current maximum limit (at the battery terminals).  The setting may be requested by a separate device (see SPN 8934) or d…";
CM_ SG_ 2566637054 DCDC2SLIBttTVtMxLtStt "Reports the active SLI Battery Voltage maximum limit (at the battery terminals).  The setting may be requested by a separate device (see SPN 8933) or determined…";
CM_ BO_ 2566638590 "Engine Exhaust Particulate Control System Info";
CM_ SG_ 2566638590 ExhstPrtltCntrlSstmDgnstCnt "The total occurrences of diagnostic codes for the exhaust particulate control system that have been active above a predetermined time threshold. A code that has…";
CM_ SG_ 2566638590 ExhstPrtltCntrlSstmDgnstTm "The total time the exhaust particulate control diagnostic codes have been active. Total time only includes the active time for codes which have been active abov…";
CM_ BO_ 2566638846 "Well Stimulation Pump Hours";
CM_ SG_ 2566638846 WllStmltnPmpMntnnIntrvlHrs "The hours accumulated since the last maintenance interval on the well stimulation pump.…";
CM_ SG_ 2566638846 WllStmltnPmpPkngOprtnHrs "The hours accumulated since the last time a packing replacement was performed on the well stimulation pump.…";
CM_ SG_ 2566638846 WllStmltnPmpVlvOprtnHrs "The hours accumulated since the last time a valve replacement was performed on the well stimulation pump.…";
CM_ SG_ 2566638846 WllStmltnPmpVlvStOprtnHrs "The hours accumulated since the last time a valve seat replacement was performed on the well stimulation pump.…";
CM_ BO_ 2566639102 "Well Stimulation Pump System Configuration Status";
CM_ SG_ 2566639102 WllStmltnPmpPlngrFrngOrdrSttng "Well stimulation pump plunger firing order0000b = Firing order 1-2-30001b = Firing order 1-5-2-3-40010b = Reserved0011b = Reserved0100b = Reserved0101b = Reserv…";
CM_ SG_ 2566639102 WllStmltnPmpRdLdHghThrshldSttng "Rod load force at which the rod load is considered at the highest acceptable force.…";
CM_ SG_ 2566639102 WSttPpCstSpdHTsdStt "Configurable well stimulation pump crankshaft speed that has been considered to be the highest acceptable speed.…";
CM_ SG_ 2566639102 WSttPpCstSpdLwTsdStt "Configurable well stimulation pump crankshaft speed that has been considered to be the lowest acceptable speed.…";
CM_ SG_ 2566639102 WSttPpDsPssHTsdStt "Configurable pressure at which the discharge pressure is considered at the highest acceptable pressure.…";
CM_ SG_ 2566639102 WSttPpGBxOPssHTsdStt "Configurable pressure at which the gearbox oil pressure is considered at the highest acceptable pressure.…";
CM_ SG_ 2566639102 WSttPpGBxOPssLwTsdStt "Configurable pressure at which the gearbox oil pressure is considered at the lowest acceptable pressure.…";
CM_ SG_ 2566639102 WSttPpGBxOTptHTsdStt "Configurable temperature at which the gearbox oil temperature is considered at the highest acceptable temperature.…";
CM_ SG_ 2566639102 WSttPpGBxOTptLwTsdStt "Configurable temperature at which the gearbox oil temperature is considered at the lowest acceptable temperature.…";
CM_ SG_ 2566639102 WSttPpStPssHTsdStt "Configurable pressure at which the suction pressure is considered at the highest acceptable pressure.…";
CM_ SG_ 2566639102 WSttPpStPssLwTsdStt "Configurable pressure at which the suction pressure is considered at the lowest acceptable pressure.…";
CM_ BO_ 2566639614 "DC/DC Converter 1 Lifetime Data";
CM_ SG_ 2566639614 DCDC1TotalHighSideCharge "Indicates the total lifetime charge converted by the DC/DC from the high side (e.g. HVES) during buck mode.  …";
CM_ SG_ 2566639614 DCDC1TotalHighSideEnergy "Indicates the total lifetime energy converted by the DC/DC from the high side (e.g. HVES) during buck mode.…";
CM_ SG_ 2566639614 DCDC1TotalLowSideCharge "Indicates the total lifetime charge converted by the DC/DC  from the low side (e.g. SLI battery) during boost mode.…";
CM_ SG_ 2566639614 DCDC1TotalLowSideEnergy "Indicates the total lifetime energy converted by the DC/DC  from the low side (e.g. SLI battery) during boost mode.…";
CM_ BO_ 2566639870 "DC/DC Converter 1 Configuration 1";
CM_ SG_ 2566639870 DCDC1HghSdCrrntMxmmLmtSttng "Reports the active maximum limit on the high side current of the DC/DC Converter.  The setting may be requested by a separate device (via SPN 8565) or determine…";
CM_ SG_ 2566639870 DCDC1HghSdVltgMnmmLmtSttng "Reports the active minimum limit on the high side voltage of the DC/DC Converter.  The setting may be requested by a separate device (via SPN 8563) or determine…";
CM_ SG_ 2566639870 DCDC1HghSdVltgMxmmLmtSttng "Reports the active maximum limit on the high side voltage of the DC/DC Converter.  The setting may be requested by a separate device (via SPN 8564) or determine…";
CM_ SG_ 2566639870 DCDC1LwSdCrrntMxmmLmtSttng "Reports the active maximum limit on the low side current of the DC/DC Converter.  The setting may be requested by a separate device (via SPN 8568) or determined…";
CM_ SG_ 2566639870 DCDC1LwSdVltgBkDfltSttng "Reports the converter active Low Side Voltage Buck Default Setting.  The default may be requested by a separate device (via SPN 9515).Note: Report Not Available…";
CM_ SG_ 2566639870 DCDC1LwSdVltgMnmmLmtSttng "Reports the active minimum limit on the low side voltage of the DC/DC Converter.  The setting may be requested by a separate device (via SPN 8566) or determined…";
CM_ SG_ 2566639870 DCDC1LwSdVltgMxmmLmtSttng "Reports the active maximum limit on the low side voltage of the DC/DC Converter.  The setting may be requested by a separate device (via SPN 8567) or determined…";
CM_ SG_ 2566639870 DCDC1SLIBttrTmprtrMxmmLmtSttng "Reports the active SLI Battery Temperature maximum limit.  The setting may be requested by a separate device (via SPN 8819) or determined by the DC/DC Controlle…";
CM_ SG_ 2566639870 DCDC1SLIBttTCCtMxLtStt "Reports the active SLI Battery charging current maximum limit (at the battery terminals).  The setting may be requested by a separate device (via SPN 8818) or d…";
CM_ SG_ 2566639870 DCDC1SLIBttTVtMxLtStt "Reports the active SLI Battery Voltage maximum limit (at the battery terminals).  The setting may be requested by a separate device (via SPN 8817) or determined…";
CM_ BO_ 2566640382 "Pump Oil Message";
CM_ SG_ 2566640382 WellStimulationPumpOilDensity "Density of the well stimulation pump oil.…";
CM_ SG_ 2566640382 WellStimulationPumpOilViscosity "Dynamic viscosity of the well stimulation pump oil.…";
CM_ SG_ 2566640382 WllStmltnPmpOlRltvDltrt "Well stimulation pump oil relative dielectricity used to describe the well stimulation pump oil quality.…";
CM_ SG_ 2566640382 WllStmltnPmpOlTmprtr "Temperature of the well stimulation pump lubricant.…";
CM_ BO_ 2566641150 "Aftercooler and Oil Cooler Fluids 2";
CM_ SG_ 2566641150 AltrntrBrngHdrIntkPrssr "Pressure of the lube oil at the intake of alternator bearing header.…";
CM_ SG_ 2566641150 AltrntrOlClrDshrgPmpPrssr "Pressure of the lube oil at the alternator oil cooler discharge pump.…";
CM_ SG_ 2566641150 EngnOlClrDshrgPmpPrssr "Pressure of the lube oil at engine oil cooler discharge pump.…";
CM_ SG_ 2566641150 EngnOlClrIntkTmprtr "Temperature of lube oil at engine cooler intake.…";
CM_ BO_ 2566641406 "Electronic Engine Controller 21";
CM_ SG_ 2566641406 EngnExhstMnfldAsltPrssr1 "Absolute pressure of the exhaust gasses as measured at the engine exhaust manifold, location 1.…";
CM_ SG_ 2566641406 EngnExhstMnfldAsltPrssr2 "Absolute pressure of the exhaust gasses as measured at the engine exhaust manifold, location 2.…";
BA_DEF_ SG_  "SPN" INT 0 524287;
BA_DEF_ BO_  "VFrameFormat" ENUM  "StandardCAN","ExtendedCAN","reserved","J1939PG";
BA_DEF_DEF_  "SPN" 0;
BA_DEF_DEF_  "VFrameFormat" "J1939PG";
BA_ "SPN" SG_ 2561146622 AuxiliaryIO17 3840;
BA_ "SPN" SG_ 2561146622 AuxiliaryIO18 3841;
BA_ "SPN" SG_ 2561146622 AuxiliaryIO19 3842;
BA_ "SPN" SG_ 2561146622 AuxiliaryIO20 3843;
BA_ "SPN" SG_ 2561146622 AuxiliaryIO21 3844;
BA_ "SPN" SG_ 2561146622 AuxiliaryIO22 3845;
BA_ "SPN" SG_ 2561146622 AuxiliaryIO23 3846;
BA_ "SPN" SG_ 2561146622 AuxiliaryIO24 3847;
BA_ "SPN" SG_ 2561146622 AuxiliaryIO25 3848;
BA_ "SPN" SG_ 2561146622 AuxiliaryIO26 3849;
BA_ "SPN" SG_ 2561146622 AuxiliaryIO27 3850;
BA_ "SPN" SG_ 2561146622 AuxiliaryIO28 3851;
BA_ "SPN" SG_ 2561146622 AuxiliaryIO29 3852;
BA_ "SPN" SG_ 2561146622 AuxiliaryIO30 3853;
BA_ "SPN" SG_ 2561146622 AuxiliaryIO31 3854;
BA_ "SPN" SG_ 2561146622 AuxiliaryIO32 3855;
BA_ "SPN" SG_ 2561146622 AuxiliaryIO33 3856;
BA_ "SPN" SG_ 2561146622 AuxiliaryIO34 3857;
BA_ "SPN" SG_ 2561146622 AuxiliaryIO35 3858;
BA_ "SPN" SG_ 2561146622 AuxiliaryIO36 3859;
BA_ "SPN" SG_ 2561146622 AuxiliaryIO37 3860;
BA_ "SPN" SG_ 2561146622 AuxiliaryIO38 3861;
BA_ "SPN" SG_ 2561146622 AuxiliaryIO39 3862;
BA_ "SPN" SG_ 2561146622 AuxiliaryIO40 3863;
BA_ "SPN" SG_ 2561146622 AuxiliaryIO41 3864;
BA_ "SPN" SG_ 2561146622 AuxiliaryIO42 3865;
BA_ "SPN" SG_ 2561146622 AuxiliaryIO43 3866;
BA_ "SPN" SG_ 2561146622 AuxiliaryIO44 3867;
BA_ "SPN" SG_ 2561146622 AuxiliaryIO45 3868;
BA_ "SPN" SG_ 2561146622 AuxiliaryIO46 3869;
BA_ "SPN" SG_ 2561146622 AuxiliaryIO47 3870;
BA_ "SPN" SG_ 2561146622 AuxiliaryIO48 3871;
BA_ "SPN" SG_ 2561212158 TextDisplayIndex 3614;
BA_ "SPN" SG_ 2561212158 TextDisplayInstructions 3613;
BA_ "SPN" SG_ 2561277694 CurrentRegion 8133;
BA_ "SPN" SG_ 2561277694 CurrentSubRegion 8134;
BA_ "SPN" SG_ 2561277694 LnDprtrWrnngEnlCmmnd 3564;
BA_ "SPN" SG_ 2561277694 LaneKeepingAssistEnableCommand 9751;
BA_ "SPN" SG_ 2561277694 LaneCenteringEnableCommand 9752;
BA_ "SPN" SG_ 2561277694 RqstdAtvStrngDrvrPrfrnMd 9760;
BA_ "SPN" SG_ 2561605374 ReferenceTirePressureSetting 3193;
BA_ "SPN" SG_ 2561605374 TireLocation 3192;
BA_ "SPN" SG_ 2563768062 EngnSpdLmtRqstMnmmCntns 1784;
BA_ "SPN" SG_ 2563768062 EngnSpdLmtRqstMxmmCntns 1785;
BA_ "SPN" SG_ 2563768062 EngnTrqLmtRqstMnmmCntns 1786;
BA_ "SPN" SG_ 2563768062 EngnTrqLmtRqstMxmmCntns 1787;
BA_ "SPN" SG_ 2563768062 MnmmCntnsRtrdrSpdLmtRqst 1788;
BA_ "SPN" SG_ 2563768062 MnmmCntnsRtrdrTrqLmtRqst 1790;
BA_ "SPN" SG_ 2563768062 MxmmCntnsRtrdrSpdLmtRqst 1789;
BA_ "SPN" SG_ 2563768062 MxmmCntnsRtrdrTrqLmtRqst 1791;
BA_ "SPN" SG_ 2563833598 IlluminationBrightnessPercent 1487;
BA_ "SPN" SG_ 2563833598 SwthBklghtIllmntnBrghtnssPrnt 5532;
BA_ "SPN" SG_ 2563833598 SwthIndtnIllmntnBrghtnssPrnt 6820;
BA_ "SPN" SG_ 2564161278 Adjustday 1607;
BA_ "SPN" SG_ 2564161278 Adjusthours 1605;
BA_ "SPN" SG_ 2564161278 Adjustlocalhouroffset 1610;
BA_ "SPN" SG_ 2564161278 Adjustlocalminuteoffset 1609;
BA_ "SPN" SG_ 2564161278 Adjustminutes 1604;
BA_ "SPN" SG_ 2564161278 Adjustmonth 1606;
BA_ "SPN" SG_ 2564161278 Adjustseconds 1603;
BA_ "SPN" SG_ 2564161278 Adjustyear 1608;
BA_ "SPN" SG_ 2564882174 AftrtrtmntRgnrtnFrSwth 3696;
BA_ "SPN" SG_ 2564882174 AftrtrtmntRgnrtnInhtSwth 3695;
BA_ "SPN" SG_ 2564882174 AtmtGrShftngEnlSwth 1666;
BA_ "SPN" SG_ 2564882174 AuxiliaryHeaterModeRequest 1683;
BA_ "SPN" SG_ 2564882174 AxlrHtrClntPmpRqst 1684;
BA_ "SPN" SG_ 2564882174 BatteryMainSwitchHoldRequest 1682;
BA_ "SPN" SG_ 2564882174 CabInteriorTemperatureCommand 1691;
BA_ "SPN" SG_ 2564882174 EngineFan1RequestedPercentSpeed 986;
BA_ "SPN" SG_ 2564882174 EngnAtmtStrtEnlSwth 1656;
BA_ "SPN" SG_ 2564882174 OperatorSeatDirectionSwitch 1714;
BA_ "SPN" SG_ 2564882174 ParkBrakeCommand 5630;
BA_ "SPN" SG_ 2564882174 RequestCabZoneHeating 1686;
BA_ "SPN" SG_ 2564882174 RequestEngineZoneHeating 1685;
BA_ "SPN" SG_ 2564882174 SeatBeltSwitch 1856;
BA_ "SPN" SG_ 2564882174 SltdMxmmVhlSpdLmt 2596;
BA_ "SPN" SG_ 2564882174 VhlLmtngSpdGvrnrDrmntSwth 1655;
BA_ "SPN" SG_ 2564882174 VhlLmtngSpdGvrnrEnlSwth 1653;
BA_ "SPN" SG_ 2564882174 VhlLmtngSpdGvrnrInrmntSwth 1654;
BA_ "SPN" SG_ 2565865982 ABSEBSAmrWrnngSgnlPwrdVhl 1438;
BA_ "SPN" SG_ 2565865982 ABSFullyOperational 1243;
BA_ "SPN" SG_ 2565865982 ABSOffroadSwitch 575;
BA_ "SPN" SG_ 2565865982 AcceleratorInterlockSwitch 972;
BA_ "SPN" SG_ 2565865982 AntiLockBrakingABSActive 563;
BA_ "SPN" SG_ 2565865982 ASRBrakeControlActive 562;
BA_ "SPN" SG_ 2565865982 ASREngineControlActive 561;
BA_ "SPN" SG_ 2565865982 ASRHillHolderSwitch 577;
BA_ "SPN" SG_ 2565865982 ASROffroadSwitch 576;
BA_ "SPN" SG_ 2565865982 ATCASRInformationSignal 1793;
BA_ "SPN" SG_ 2565865982 BrakePedalPosition 521;
BA_ "SPN" SG_ 2565865982 EBSBrakeSwitch 1121;
BA_ "SPN" SG_ 2565865982 EBSRedWarningSignal 1439;
BA_ "SPN" SG_ 2565865982 EngineAuxiliaryShutdownSwitch 970;
BA_ "SPN" SG_ 2565865982 EngineDerateSwitch 971;
BA_ "SPN" SG_ 2565865982 EngineRetarderSelection 973;
BA_ "SPN" SG_ 2565865982 Haltbrakeswitch 2911;
BA_ "SPN" SG_ 2565865982 RailroadModeSwitch 7941;
BA_ "SPN" SG_ 2565865982 RemoteAcceleratorEnableSwitch 969;
BA_ "SPN" SG_ 2565865982 SrAddrssfCntrllngDvfrBrkCntrl 1481;
BA_ "SPN" SG_ 2565865982 TractionControlOverrideSwitch 1238;
BA_ "SPN" SG_ 2565865982 TrailerABSStatus 1836;
BA_ "SPN" SG_ 2565865982 TrtrMntdTrlrABSWrnngSgnl 1792;
BA_ "SPN" SG_ 2565867006 TransmissionActualGearRatio 526;
BA_ "SPN" SG_ 2565867006 TransmissionCurrentGear 523;
BA_ "SPN" SG_ 2565867006 TransmissionCurrentRange 163;
BA_ "SPN" SG_ 2565867006 TransmissionRequestedRange 162;
BA_ "SPN" SG_ 2565867006 TransmissionSelectedGear 524;
BA_ "SPN" SG_ 2565867262 DffrntlLkSttCntrlFrnt 565;
BA_ "SPN" SG_ 2565867262 DffrntlLkSttCntrlRr 566;
BA_ "SPN" SG_ 2565867262 DifferentialLockStateCentral 564;
BA_ "SPN" SG_ 2565867262 DifferentialLockStateFrontAxle1 567;
BA_ "SPN" SG_ 2565867262 DifferentialLockStateFrontAxle2 568;
BA_ "SPN" SG_ 2565867262 DifferentialLockStateRearAxle1 569;
BA_ "SPN" SG_ 2565867262 DifferentialLockStateRearAxle2 570;
BA_ "SPN" SG_ 2565867262 DifferentialLockStateRearAxle3 7716;
BA_ "SPN" SG_ 2565867262 Frontaxlegroupengagementstatus 3819;
BA_ "SPN" SG_ 2565867262 Location 927;
BA_ "SPN" SG_ 2565867262 Rearaxlegroupengagementstatus 3820;
BA_ "SPN" SG_ 2565867774 EngnHdrlPrssrGvrnrMdIndtr 1763;
BA_ "SPN" SG_ 2565867774 EngnHdrlPrssrGvrnrSwth 1764;
BA_ "SPN" SG_ 2565867774 FireApparatusPumpEngagement 2599;
BA_ "SPN" SG_ 2565867774 FrApprtsOkTPmpIntrlk 6702;
BA_ "SPN" SG_ 2565867774 HdrlDshrgPrssrStPnt 6708;
BA_ "SPN" SG_ 2565867774 HdrlPrssrGvrnrDrsSwth 6704;
BA_ "SPN" SG_ 2565867774 HdrlPrssrGvrnrIdlSwth 6705;
BA_ "SPN" SG_ 2565867774 HdrlPrssrGvrnrInrsSwth 6703;
BA_ "SPN" SG_ 2565867774 HdrlPrssrGvrnrPrstSwth 6706;
BA_ "SPN" SG_ 2565867774 HydraulicIntakePressure 6707;
BA_ "SPN" SG_ 2565867774 HydraulicPressure 1762;
BA_ "SPN" SG_ 2565868030 LateralAcceleration 1809;
BA_ "SPN" SG_ 2565868030 LongitudinalAcceleration 1810;
BA_ "SPN" SG_ 2565868030 SteeringWheelAngle 1807;
BA_ "SPN" SG_ 2565868030 SteeringWheelAngleSensorType 1812;
BA_ "SPN" SG_ 2565868030 SteeringWheelTurnCounter 1811;
BA_ "SPN" SG_ 2565868030 YawRate 1808;
BA_ "SPN" SG_ 2565868542 ActualInnerwheelsteeringangle 2927;
BA_ "SPN" SG_ 2565868542 AxleLocation 2928;
BA_ "SPN" SG_ 2565868542 StatusofSteeringAxle 2923;
BA_ "SPN" SG_ 2565868542 SteeringType 2924;
BA_ "SPN" SG_ 2565868542 StrlLftAxlLwrngInht 2922;
BA_ "SPN" SG_ 2565868542 TypeofSteeringForces 2925;
BA_ "SPN" SG_ 2565868542 TypeofSteeringTransmission 2926;
BA_ "SPN" SG_ 2565869310 Aftrtrtmnt1IntkGsSnsr1HtrCntrl 3223;
BA_ "SPN" SG_ 2565869310 Aftrtrtmnt1IntkGsSnsr1tTmprtr 3219;
BA_ "SPN" SG_ 2565869310 Atttt1ItGsSs1HtPFMI 3222;
BA_ "SPN" SG_ 2565869310 Atttt1ItOxSs1PFMI 3225;
BA_ "SPN" SG_ 2565869310 Atttt1ItWdRPtOx1RdSt 3221;
BA_ "SPN" SG_ 2565869310 EngineExhaust1NOx1 3216;
BA_ "SPN" SG_ 2565869310 EngineExhaust1NOx1ReadingStable 3220;
BA_ "SPN" SG_ 2565869310 EngnExhst1NOxSnsr1PrlmnrFMI 3224;
BA_ "SPN" SG_ 2565869310 EngnExhst1NOxSnsr1SlfdgnssStts 5714;
BA_ "SPN" SG_ 2565869310 EngineExhaust1PercentOxygen1 3217;
BA_ "SPN" SG_ 2565869310 EngnExhst1GsSnsr1PwrInRng 3218;
BA_ "SPN" SG_ 2565869566 Aftertreatment1OutletNOx1 3226;
BA_ "SPN" SG_ 2565869566 Aftrtrtmnt1OtltGsSnsr1HtrCntrl 3233;
BA_ "SPN" SG_ 2565869566 Aftrtrtmnt1OtltGsSnsr1PwrInRng 3228;
BA_ "SPN" SG_ 2565869566 Aftrtrtmnt1OtltGsSnsr1tTmprtr 3229;
BA_ "SPN" SG_ 2565869566 Aftrtrtmnt1OtltNOx1RdngStl 3230;
BA_ "SPN" SG_ 2565869566 Aftrtrtmnt1OtltPrntOxgn1 3227;
BA_ "SPN" SG_ 2565869566 Atttt1OttGsSs1HtPFMI 3232;
BA_ "SPN" SG_ 2565869566 Atttt1OttNOxSs1PFMI 3234;
BA_ "SPN" SG_ 2565869566 Atttt1OttNOxSs1SdssStts 5713;
BA_ "SPN" SG_ 2565869566 Atttt1OttOxSs1PFMI 3235;
BA_ "SPN" SG_ 2565869566 Atttt1OttWdRPtOx1RdSt 3231;
BA_ "SPN" SG_ 2565869822 Aftrtrtmnt2IntkGsSnsr1HtrCntrl 3262;
BA_ "SPN" SG_ 2565869822 Aftrtrtmnt2IntkGsSnsr1tTmprtr 3258;
BA_ "SPN" SG_ 2565869822 Atttt2ItGsSs1HtPFMI 3261;
BA_ "SPN" SG_ 2565869822 Atttt2ItOxSs1PFMI 3264;
BA_ "SPN" SG_ 2565869822 Atttt2ItWdRPtOx1RdSt 3260;
BA_ "SPN" SG_ 2565869822 EngineExhaust2NOx1 3255;
BA_ "SPN" SG_ 2565869822 EngineExhaust2NOx1ReadingStable 3259;
BA_ "SPN" SG_ 2565869822 EngnExhst2NOxSnsr1PrlmnrFMI 3263;
BA_ "SPN" SG_ 2565869822 EngnExhst2NOxSnsr1SlfdgnssStts 5716;
BA_ "SPN" SG_ 2565869822 EngineExhaust2PercentOxygen1 3256;
BA_ "SPN" SG_ 2565869822 EngnExhst2GsSnsr1PwrInRng 3257;
BA_ "SPN" SG_ 2565869822 EngnExhst2Intk2GsSnsrPwrSppl 8485;
BA_ "SPN" SG_ 2565870078 Aftertreatment2OutletNOx1 3265;
BA_ "SPN" SG_ 2565870078 Aftrtrtmnt2Otlt2GsSnsrPwrSppl 8486;
BA_ "SPN" SG_ 2565870078 Aftrtrtmnt2OtltGsSnsr1HtrCntrl 3272;
BA_ "SPN" SG_ 2565870078 Aftrtrtmnt2OtltGsSnsr1PwrInRng 3267;
BA_ "SPN" SG_ 2565870078 Aftrtrtmnt2OtltGsSnsr1tTmprtr 3268;
BA_ "SPN" SG_ 2565870078 Aftrtrtmnt2OtltNOx1RdngStl 3269;
BA_ "SPN" SG_ 2565870078 Aftrtrtmnt2OtltPrntOxgn1 3266;
BA_ "SPN" SG_ 2565870078 Atttt2OttGsSs1HtPFMI 3271;
BA_ "SPN" SG_ 2565870078 Atttt2OttNOxSs1PFMI 3273;
BA_ "SPN" SG_ 2565870078 Atttt2OttNOxSs1SdssStts 5715;
BA_ "SPN" SG_ 2565870078 Atttt2OttOxSs1PFMI 3274;
BA_ "SPN" SG_ 2565870078 Atttt2OttWdRPtOx1RdSt 3270;
BA_ "SPN" SG_ 2565870334 FifthWheelDrawbarForce 3309;
BA_ "SPN" SG_ 2565870334 FifthWheelRollMoment 3310;
BA_ "SPN" SG_ 2565870334 FifthWheelRollWarningIndicator 3317;
BA_ "SPN" SG_ 2565870334 FifthWheelVerticalForce 3308;
BA_ "SPN" SG_ 2565873150 MessageChecksum 3690;
BA_ "SPN" SG_ 2565873150 MessageCounter 3689;
BA_ "SPN" SG_ 2565873150 SteeringAngleSensorActiveMode 3687;
BA_ "SPN" SG_ 2565873150 SteeringAngleSensorCalibrated 3688;
BA_ "SPN" SG_ 2565873150 SteeringWheelAngle 3683;
BA_ "SPN" SG_ 2565873150 SteeringWheelAngleRange 3686;
BA_ "SPN" SG_ 2565873150 SteeringWheelAngleRangeCounter 3684;
BA_ "SPN" SG_ 2565873150 StrngWhlAnglRngCntrTp 3685;
BA_ "SPN" SG_ 2565874174 EngineSpeed1 4201;
BA_ "SPN" SG_ 2565874174 EngineSpeed2 723;
BA_ "SPN" SG_ 2565874174 EngineSpeed3 4202;
BA_ "SPN" SG_ 2565874174 EngnSpdSnsr1TmngPttrnStts 4203;
BA_ "SPN" SG_ 2565874174 EngnSpdSnsr2TmngPttrnStts 4204;
BA_ "SPN" SG_ 2565874174 EngnSpdSnsr3TmngPttrnStts 4205;
BA_ "SPN" SG_ 2565877502 EExstB1PssRtCtCd 649;
BA_ "SPN" SG_ 2565877502 EngnTrhrgrWstgtAttr1Cmmnd 5386;
BA_ "SPN" SG_ 2565877502 EngnTrhrgrWstgtAttr2Cmmnd 5387;
BA_ "SPN" SG_ 2565877502 ETCpssBwAtt1Cd 6201;
BA_ "SPN" SG_ 2565917438 DCACAssIvt1PwLtddtACSdRMSCt 9212;
BA_ "SPN" SG_ 2565917438 DCACAssIvt1PwLtddtCtTpt 9216;
BA_ "SPN" SG_ 2565917438 DCACAssIvt1PwLtddtDCSdCt 9211;
BA_ "SPN" SG_ 2565917438 DCACAssIvt1PwLtddtDCSdVtM 9213;
BA_ "SPN" SG_ 2565917438 DCACAssIvt1PwLtddtEtFtTpt 9217;
BA_ "SPN" SG_ 2565917438 DCACAssIvt1PwLtddtPwEtsTpt 9218;
BA_ "SPN" SG_ 2565917438 DCACAssIvt1PwLtddtRtCLt 9219;
BA_ "SPN" SG_ 2565917438 DCACAssIvt1PwLtddtUddRs 9220;
BA_ "SPN" SG_ 2565917438 DCACAssrInvrtr1FrqnCmmndlwMnmm 9214;
BA_ "SPN" SG_ 2565917438 DCACAssrInvrtr1FrqnCmmndxdsMxmm 9215;
BA_ "SPN" SG_ 2565918206 DCACAssIvt2PwLtddtACSdRMSCt 9242;
BA_ "SPN" SG_ 2565918206 DCACAssIvt2PwLtddtCtTpt 9246;
BA_ "SPN" SG_ 2565918206 DCACAssIvt2PwLtddtDCSdCt 9241;
BA_ "SPN" SG_ 2565918206 DCACAssIvt2PwLtddtDCSdVtM 9243;
BA_ "SPN" SG_ 2565918206 DCACAssIvt2PwLtddtEtFtTpt 9247;
BA_ "SPN" SG_ 2565918206 DCACAssIvt2PwLtddtPwEtsTpt 9248;
BA_ "SPN" SG_ 2565918206 DCACAssIvt2PwLtddtRtCLt 9249;
BA_ "SPN" SG_ 2565918206 DCACAssIvt2PwLtddtUddRs 9250;
BA_ "SPN" SG_ 2565918206 DCACAssrInvrtr2FrqnCmmndlwMnmm 9244;
BA_ "SPN" SG_ 2565918206 DCACAssrInvrtr2FrqnCmmndxdsMxmm 9245;
BA_ "SPN" SG_ 2565920510 DCACAssIvt1ACSdMtSttRMSVtRqst 9528;
BA_ "SPN" SG_ 2565920510 DCACAssrInvrtr1Dv1Stts 8334;
BA_ "SPN" SG_ 2565920510 DCACAssrInvrtr1Dv2Stts 8335;
BA_ "SPN" SG_ 2565920510 DCACAssrInvrtr1DvFrqnRtfChngLmt 8332;
BA_ "SPN" SG_ 2565920510 DCACAssrInvrtr1DvMnmmFrqn 8329;
BA_ "SPN" SG_ 2565920510 DCACAssrInvrtr1DvMxmmFrqn 8328;
BA_ "SPN" SG_ 2565920510 DCACAssrInvrtr1DvRtdFrqn 8330;
BA_ "SPN" SG_ 2565920510 DCACAssrInvrtr1DvRtdRMSVltg 8331;
BA_ "SPN" SG_ 2565920510 DCACAssrInvrtr1FrqnCmmnd 8333;
BA_ "SPN" SG_ 2565920510 DCACAssrInvrtr1OprtnlCmmnd 8336;
BA_ "SPN" SG_ 2565920766 DCACAccessoryInverter1Frequency 8337;
BA_ "SPN" SG_ 2565920766 DCACAssrInvrtr1ACSdPwr 8339;
BA_ "SPN" SG_ 2565920766 DCACAssrInvrtr1ACSdRMSCrrnt 9200;
BA_ "SPN" SG_ 2565920766 DCACAssrInvrtr1ACSdRMSVltg 8338;
BA_ "SPN" SG_ 2565920766 DCACAssrInvrtr1HVILStts 8851;
BA_ "SPN" SG_ 2565920766 DCACAssrInvrtr1LdshdRqst 8341;
BA_ "SPN" SG_ 2565920766 DCACAssrInvrtr1OprtnlStts 8340;
BA_ "SPN" SG_ 2565921534 DCACAssIvt2ACSdMtSttRMSVtRqst 9534;
BA_ "SPN" SG_ 2565921534 DCACAssrInvrtr2Dv1Stts 8348;
BA_ "SPN" SG_ 2565921534 DCACAssrInvrtr2Dv2Stts 8349;
BA_ "SPN" SG_ 2565921534 DCACAssrInvrtr2DvFrqnRtfChngLmt 8346;
BA_ "SPN" SG_ 2565921534 DCACAssrInvrtr2DvMnmmFrqn 8343;
BA_ "SPN" SG_ 2565921534 DCACAssrInvrtr2DvMxmmFrqn 8342;
BA_ "SPN" SG_ 2565921534 DCACAssrInvrtr2DvRtdFrqn 8344;
BA_ "SPN" SG_ 2565921534 DCACAssrInvrtr2DvRtdRMSVltg 8345;
BA_ "SPN" SG_ 2565921534 DCACAssrInvrtr2FrqnCmmnd 8347;
BA_ "SPN" SG_ 2565921534 DCACAssrInvrtr2OprtnlCmmnd 8350;
BA_ "SPN" SG_ 2565921790 DCACAccessoryInverter2Frequency 8351;
BA_ "SPN" SG_ 2565921790 DCACAssrInvrtr2ACSdPwr 8353;
BA_ "SPN" SG_ 2565921790 DCACAssrInvrtr2ACSdRMSCrrnt 9201;
BA_ "SPN" SG_ 2565921790 DCACAssrInvrtr2ACSdRMSVltg 8352;
BA_ "SPN" SG_ 2565921790 DCACAssrInvrtr2HVILStts 8852;
BA_ "SPN" SG_ 2565921790 DCACAssrInvrtr2LdshdRqst 8355;
BA_ "SPN" SG_ 2565921790 DCACAssrInvrtr2OprtnlStts 8354;
BA_ "SPN" SG_ 2565922558 DCACAssIvt3ACSdMtSttRMSVtRqst 9540;
BA_ "SPN" SG_ 2565922558 DCACAssrInvrtr3Dv1Stts 8362;
BA_ "SPN" SG_ 2565922558 DCACAssrInvrtr3Dv2Stts 8363;
BA_ "SPN" SG_ 2565922558 DCACAssrInvrtr3DvFrqnRtfChngLmt 8360;
BA_ "SPN" SG_ 2565922558 DCACAssrInvrtr3DvMnmmFrqn 8357;
BA_ "SPN" SG_ 2565922558 DCACAssrInvrtr3DvMxmmFrqn 8356;
BA_ "SPN" SG_ 2565922558 DCACAssrInvrtr3DvRtdFrqn 8358;
BA_ "SPN" SG_ 2565922558 DCACAssrInvrtr3DvRtdRMSVltg 8359;
BA_ "SPN" SG_ 2565922558 DCACAssrInvrtr3FrqnCmmnd 8361;
BA_ "SPN" SG_ 2565922558 DCACAssrInvrtr3OprtnlCmmnd 8364;
BA_ "SPN" SG_ 2565922814 DCACAccessoryInverter3Frequency 8365;
BA_ "SPN" SG_ 2565922814 DCACAssrInvrtr3ACSdPwr 8367;
BA_ "SPN" SG_ 2565922814 DCACAssrInvrtr3ACSdRMSCrrnt 9202;
BA_ "SPN" SG_ 2565922814 DCACAssrInvrtr3ACSdRMSVltg 8366;
BA_ "SPN" SG_ 2565922814 DCACAssrInvrtr3HVILStts 8853;
BA_ "SPN" SG_ 2565922814 DCACAssrInvrtr3LdshdRqst 8369;
BA_ "SPN" SG_ 2565922814 DCACAssrInvrtr3OprtnlStts 8368;
BA_ "SPN" SG_ 2565923582 DCACAssIvt4ACSdMtSttRMSVtRqst 9546;
BA_ "SPN" SG_ 2565923582 DCACAssrInvrtr4Dv1Stts 8376;
BA_ "SPN" SG_ 2565923582 DCACAssrInvrtr4Dv2Stts 8377;
BA_ "SPN" SG_ 2565923582 DCACAssrInvrtr4DvFrqnRtfChngLmt 8374;
BA_ "SPN" SG_ 2565923582 DCACAssrInvrtr4DvMnmmFrqn 8371;
BA_ "SPN" SG_ 2565923582 DCACAssrInvrtr4DvMxmmFrqn 8370;
BA_ "SPN" SG_ 2565923582 DCACAssrInvrtr4DvRtdFrqn 8372;
BA_ "SPN" SG_ 2565923582 DCACAssrInvrtr4DvRtdRMSVltg 8373;
BA_ "SPN" SG_ 2565923582 DCACAssrInvrtr4FrqnCmmnd 8375;
BA_ "SPN" SG_ 2565923582 DCACAssrInvrtr4OprtnlCmmnd 8378;
BA_ "SPN" SG_ 2565923838 DCACAccessoryInverter4Frequency 8379;
BA_ "SPN" SG_ 2565923838 DCACAssrInvrtr4ACSdPwr 8381;
BA_ "SPN" SG_ 2565923838 DCACAssrInvrtr4ACSdRMSCrrnt 9203;
BA_ "SPN" SG_ 2565923838 DCACAssrInvrtr4ACSdRMSVltg 8380;
BA_ "SPN" SG_ 2565923838 DCACAssrInvrtr4HVILStts 8854;
BA_ "SPN" SG_ 2565923838 DCACAssrInvrtr4LdshdRqst 8383;
BA_ "SPN" SG_ 2565923838 DCACAssrInvrtr4OprtnlStts 8382;
BA_ "SPN" SG_ 2565925374 Aftrtrtmnt1IntkGsSnsr2HtrCntrl 7656;
BA_ "SPN" SG_ 2565925374 Aftrtrtmnt1IntkGsSnsr2PwrInRng 7651;
BA_ "SPN" SG_ 2565925374 Aftrtrtmnt1IntkGsSnsr2tTmprtr 7652;
BA_ "SPN" SG_ 2565925374 Aftrtrtmnt1IntkPrntOxgn2 7650;
BA_ "SPN" SG_ 2565925374 Atttt1ItGsSs2HtPFMI 7655;
BA_ "SPN" SG_ 2565925374 Atttt1ItOxSs2PFMI 7659;
BA_ "SPN" SG_ 2565925374 Atttt1ItWdRPtOx2RdSt 7654;
BA_ "SPN" SG_ 2565925374 EngineExhaust1NOx2 7649;
BA_ "SPN" SG_ 2565925374 EngineExhaust1NOx2ReadingStable 7653;
BA_ "SPN" SG_ 2565925374 EngnExhst1NOxSnsr2PrlmnrFMI 7657;
BA_ "SPN" SG_ 2565925374 EngnExhst1NOxSnsr2SlfdgnssStts 7658;
BA_ "SPN" SG_ 2565925630 Aftertreatment1OutletNOx2 7660;
BA_ "SPN" SG_ 2565925630 Aftrtrtmnt1OtltGsSnsr2HtrCntrl 7667;
BA_ "SPN" SG_ 2565925630 Aftrtrtmnt1OtltGsSnsr2PwrInRng 7662;
BA_ "SPN" SG_ 2565925630 Aftrtrtmnt1OtltGsSnsr2tTmprtr 7663;
BA_ "SPN" SG_ 2565925630 Aftrtrtmnt1OtltNOx2RdngStl 7664;
BA_ "SPN" SG_ 2565925630 Aftrtrtmnt1OtltPrntOxgn2 7661;
BA_ "SPN" SG_ 2565925630 Atttt1OttGsSs2HtPFMI 7666;
BA_ "SPN" SG_ 2565925630 Atttt1OttNOxSs2PFMI 7668;
BA_ "SPN" SG_ 2565925630 Atttt1OttNOxSs2SdssStts 7669;
BA_ "SPN" SG_ 2565925630 Atttt1OttOxSs2PFMI 7670;
BA_ "SPN" SG_ 2565925630 Atttt1OttWdRPtOx2RdSt 7665;
BA_ "SPN" SG_ 2565925886 Aftrtrtmnt2IntkGsSnsr2HtrCntrl 7678;
BA_ "SPN" SG_ 2565925886 Aftrtrtmnt2IntkGsSnsr2PwrInRng 7673;
BA_ "SPN" SG_ 2565925886 Aftrtrtmnt2IntkGsSnsr2tTmprtr 7674;
BA_ "SPN" SG_ 2565925886 Aftrtrtmnt2IntkPrntOxgn2 7672;
BA_ "SPN" SG_ 2565925886 Atttt2ItGsSs2HtPFMI 7677;
BA_ "SPN" SG_ 2565925886 Atttt2ItOxSs2PFMI 7681;
BA_ "SPN" SG_ 2565925886 Atttt2ItWdRPtOx2RdSt 7676;
BA_ "SPN" SG_ 2565925886 EExst2ItNOxSs2SdssStts 7680;
BA_ "SPN" SG_ 2565925886 EngineExhaust2NOx2 7671;
BA_ "SPN" SG_ 2565925886 EngineExhaust2NOx2ReadingStable 7675;
BA_ "SPN" SG_ 2565925886 EngnExhst2NOxSnsr2PrlmnrFMI 7679;
BA_ "SPN" SG_ 2565926142 Aftertreatment2OutletNOx2 7682;
BA_ "SPN" SG_ 2565926142 Aftrtrtmnt2OtltGsSnsr2HtrCntrl 7689;
BA_ "SPN" SG_ 2565926142 Aftrtrtmnt2OtltGsSnsr2PwrInRng 7684;
BA_ "SPN" SG_ 2565926142 Aftrtrtmnt2OtltGsSnsr2tTmprtr 7685;
BA_ "SPN" SG_ 2565926142 Aftrtrtmnt2OtltNOx2RdngStl 7686;
BA_ "SPN" SG_ 2565926142 Aftrtrtmnt2OtltPrntOxgn2 7683;
BA_ "SPN" SG_ 2565926142 Atttt2OttGsSs2HtPFMI 7688;
BA_ "SPN" SG_ 2565926142 Atttt2OttNOxSs2PFMI 7690;
BA_ "SPN" SG_ 2565926142 Atttt2OttNOxSs2SdssStts 7691;
BA_ "SPN" SG_ 2565926142 Atttt2OttOxSs2PFMI 7692;
BA_ "SPN" SG_ 2565926142 Atttt2OttWdRPtOx2RdSt 7687;
BA_ "SPN" SG_ 2565932286 EngineSpeed4 7846;
BA_ "SPN" SG_ 2565932798 WllStmltnPmpDshrgPrssr 8155;
BA_ "SPN" SG_ 2565932798 WllStmltnPmpStnPrssr 8154;
BA_ "SPN" SG_ 2565933054 WellStimulationPumpSpeed 8158;
BA_ "SPN" SG_ 2565933054 WllStmltnPmpGrBxOlPrssr 8156;
BA_ "SPN" SG_ 2565933054 WllStmltnPmpGrBxOlTmprtr 8157;
BA_ "SPN" SG_ 2565934590 EngnFlVlv2DffrntlPrssr 6885;
BA_ "SPN" SG_ 2565942014 DCACAssIvt3PwLtddtACSdRMSCt 9272;
BA_ "SPN" SG_ 2565942014 DCACAssIvt3PwLtddtCtTpt 9276;
BA_ "SPN" SG_ 2565942014 DCACAssIvt3PwLtddtDCSdCt 9271;
BA_ "SPN" SG_ 2565942014 DCACAssIvt3PwLtddtDCSdVtM 9273;
BA_ "SPN" SG_ 2565942014 DCACAssIvt3PwLtddtEtFtTpt 9277;
BA_ "SPN" SG_ 2565942014 DCACAssIvt3PwLtddtPwEtsTpt 9278;
BA_ "SPN" SG_ 2565942014 DCACAssIvt3PwLtddtRtCLt 9279;
BA_ "SPN" SG_ 2565942014 DCACAssIvt3PwLtddtUddRs 9280;
BA_ "SPN" SG_ 2565942014 DCACAssrInvrtr3FrqnCmmndlwMnmm 9274;
BA_ "SPN" SG_ 2565942014 DCACAssrInvrtr3FrqnCmmndxdsMxmm 9275;
BA_ "SPN" SG_ 2565942782 DCACAssIvt4PwLtddtACSdRMSCt 9302;
BA_ "SPN" SG_ 2565942782 DCACAssIvt4PwLtddtCtTpt 9306;
BA_ "SPN" SG_ 2565942782 DCACAssIvt4PwLtddtDCSdCt 9301;
BA_ "SPN" SG_ 2565942782 DCACAssIvt4PwLtddtDCSdVtM 9303;
BA_ "SPN" SG_ 2565942782 DCACAssIvt4PwLtddtEtFtTpt 9307;
BA_ "SPN" SG_ 2565942782 DCACAssIvt4PwLtddtPwEtsTpt 9308;
BA_ "SPN" SG_ 2565942782 DCACAssIvt4PwLtddtRtCLt 9309;
BA_ "SPN" SG_ 2565942782 DCACAssIvt4PwLtddtUddRs 9310;
BA_ "SPN" SG_ 2565942782 DCACAssrInvrtr4FrqnCmmndlwMnmm 9304;
BA_ "SPN" SG_ 2565942782 DCACAssrInvrtr4FrqnCmmndxdsMxmm 9305;
BA_ "SPN" SG_ 2565943038 DCACAssIvt5ACSdMtSttRMSVtRqst 9552;
BA_ "SPN" SG_ 2565943038 DCACAssrInvrtr5Dv1Stts 9327;
BA_ "SPN" SG_ 2565943038 DCACAssrInvrtr5Dv2Stts 9328;
BA_ "SPN" SG_ 2565943038 DCACAssrInvrtr5DvFrqnRtfChngLmt 9325;
BA_ "SPN" SG_ 2565943038 DCACAssrInvrtr5DvMnmmFrqn 9322;
BA_ "SPN" SG_ 2565943038 DCACAssrInvrtr5DvMxmmFrqn 9321;
BA_ "SPN" SG_ 2565943038 DCACAssrInvrtr5DvRtdFrqn 9323;
BA_ "SPN" SG_ 2565943038 DCACAssrInvrtr5DvRtdRMSVltg 9324;
BA_ "SPN" SG_ 2565943038 DCACAssrInvrtr5FrqnCmmnd 9326;
BA_ "SPN" SG_ 2565943038 DCACAssrInvrtr5OprtnlCmmnd 9329;
BA_ "SPN" SG_ 2565943294 DCACAccessoryInverter5Frequency 9330;
BA_ "SPN" SG_ 2565943294 DCACAssrInvrtr5ACSdPwr 9332;
BA_ "SPN" SG_ 2565943294 DCACAssrInvrtr5ACSdRMSCrrnt 9333;
BA_ "SPN" SG_ 2565943294 DCACAssrInvrtr5ACSdRMSVltg 9331;
BA_ "SPN" SG_ 2565943294 DCACAssrInvrtr5HVILStts 9336;
BA_ "SPN" SG_ 2565943294 DCACAssrInvrtr5LdshdRqst 9335;
BA_ "SPN" SG_ 2565943294 DCACAssrInvrtr5OprtnlStts 9334;
BA_ "SPN" SG_ 2565944062 DCACAssIvt5PwLtddtACSdRMSCt 9348;
BA_ "SPN" SG_ 2565944062 DCACAssIvt5PwLtddtCtTpt 9352;
BA_ "SPN" SG_ 2565944062 DCACAssIvt5PwLtddtDCSdCt 9347;
BA_ "SPN" SG_ 2565944062 DCACAssIvt5PwLtddtDCSdVtM 9349;
BA_ "SPN" SG_ 2565944062 DCACAssIvt5PwLtddtEtFtTpt 9353;
BA_ "SPN" SG_ 2565944062 DCACAssIvt5PwLtddtPwEtsTpt 9354;
BA_ "SPN" SG_ 2565944062 DCACAssIvt5PwLtddtRtCLt 9355;
BA_ "SPN" SG_ 2565944062 DCACAssIvt5PwLtddtUddRs 9356;
BA_ "SPN" SG_ 2565944062 DCACAssrInvrtr5FrqnCmmndlwMnmm 9350;
BA_ "SPN" SG_ 2565944062 DCACAssrInvrtr5FrqnCmmndxdsMxmm 9351;
BA_ "SPN" SG_ 2566624510 EngnExhstGsRrltn1ClrIntkPrssr 9379;
BA_ "SPN" SG_ 2566624766 EngnIdlMngmntAtvTtlTm 9377;
BA_ "SPN" SG_ 2566625022 InstntnsEstmtdEngnPwrRtLmt 9375;
BA_ "SPN" SG_ 2566625278 SLIBttrPk1Bttr1CptSttng 9368;
BA_ "SPN" SG_ 2566625278 SLIBttrPk1Bttr2CptSttng 9369;
BA_ "SPN" SG_ 2566625278 SLIBttrPk1Bttr3CptSttng 9370;
BA_ "SPN" SG_ 2566625278 SLIBttrPk1Bttr4CptSttng 9371;
BA_ "SPN" SG_ 2566625790 DCACAssIvt1IvtEtFtTpt 9205;
BA_ "SPN" SG_ 2566625790 DCACAssrInvrtr1ClntInTmprtr 9207;
BA_ "SPN" SG_ 2566625790 DCACAssrInvrtr1ClntOtTmprtr 9208;
BA_ "SPN" SG_ 2566625790 DCACAssrInvrtr1CntrllrTmprtr 9204;
BA_ "SPN" SG_ 2566625790 DCACAssrInvrtr1PwrEltrnsTmprtr 9206;
BA_ "SPN" SG_ 2566626558 DCACAssIvt1ACSdDtFqCdStt 9533;
BA_ "SPN" SG_ 2566626558 DCACAssIvt1ACSdRMSCtMxLtStt 9228;
BA_ "SPN" SG_ 2566626558 DCACAssIvt1ACSdRMSVtMxLtStt 9227;
BA_ "SPN" SG_ 2566626558 DCACAssIvt1DCSdCtMLtStt 9532;
BA_ "SPN" SG_ 2566626558 DCACAssIvt1DCSdCtMxLtStt 9226;
BA_ "SPN" SG_ 2566626558 DCACAssIvt1DCSdVtMLtStt 9225;
BA_ "SPN" SG_ 2566626558 DCACAssIvt1DCSdVtMxLtStt 9531;
BA_ "SPN" SG_ 2566626814 DCACAssrInvrtr1TtlDCInptChrg 9229;
BA_ "SPN" SG_ 2566626814 DCACAssrInvrtr1TtlDCInptEnrg 9230;
BA_ "SPN" SG_ 2566627070 DCACAssIvt2IvtEtFtTpt 9232;
BA_ "SPN" SG_ 2566627070 DCACAssrInvrtr2ClntInTmprtr 9234;
BA_ "SPN" SG_ 2566627070 DCACAssrInvrtr2ClntOtTmprtr 9235;
BA_ "SPN" SG_ 2566627070 DCACAssrInvrtr2CntrllrTmprtr 9231;
BA_ "SPN" SG_ 2566627070 DCACAssrInvrtr2PwrEltrnsTmprtr 9233;
BA_ "SPN" SG_ 2566627838 DCACAssIvt2ACSdDtFqCdStt 9539;
BA_ "SPN" SG_ 2566627838 DCACAssIvt2ACSdRMSCtMxLtStt 9258;
BA_ "SPN" SG_ 2566627838 DCACAssIvt2ACSdRMSVtMxLtStt 9257;
BA_ "SPN" SG_ 2566627838 DCACAssIvt2DCSdCtMLtStt 9538;
BA_ "SPN" SG_ 2566627838 DCACAssIvt2DCSdCtMxLtStt 9256;
BA_ "SPN" SG_ 2566627838 DCACAssIvt2DCSdVtMLtStt 9255;
BA_ "SPN" SG_ 2566627838 DCACAssIvt2DCSdVtMxLtStt 9537;
BA_ "SPN" SG_ 2566628094 DCACAssrInvrtr2TtlDCInptChrg 9259;
BA_ "SPN" SG_ 2566628094 DCACAssrInvrtr2TtlDCInptEnrg 9260;
BA_ "SPN" SG_ 2566628350 DCACAssIvt3IvtEtFtTpt 9262;
BA_ "SPN" SG_ 2566628350 DCACAssrInvrtr3ClntInTmprtr 9264;
BA_ "SPN" SG_ 2566628350 DCACAssrInvrtr3ClntOtTmprtr 9265;
BA_ "SPN" SG_ 2566628350 DCACAssrInvrtr3CntrllrTmprtr 9261;
BA_ "SPN" SG_ 2566628350 DCACAssrInvrtr3PwrEltrnsTmprtr 9263;
BA_ "SPN" SG_ 2566629118 DCACAssIvt3ACSdDtFqCdStt 9545;
BA_ "SPN" SG_ 2566629118 DCACAssIvt3ACSdRMSCtMxLtStt 9288;
BA_ "SPN" SG_ 2566629118 DCACAssIvt3ACSdRMSVtMxLtStt 9287;
BA_ "SPN" SG_ 2566629118 DCACAssIvt3DCSdCtMLtStt 9544;
BA_ "SPN" SG_ 2566629118 DCACAssIvt3DCSdCtMxLtStt 9286;
BA_ "SPN" SG_ 2566629118 DCACAssIvt3DCSdVtMLtStt 9285;
BA_ "SPN" SG_ 2566629118 DCACAssIvt3DCSdVtMxLtStt 9543;
BA_ "SPN" SG_ 2566629374 DCACAssrInvrtr3TtlDCInptChrg 9289;
BA_ "SPN" SG_ 2566629374 DCACAssrInvrtr3TtlDCInptEnrg 9290;
BA_ "SPN" SG_ 2566629630 DCACAssIvt4IvtEtFtTpt 9292;
BA_ "SPN" SG_ 2566629630 DCACAssrInvrtr4ClntInTmprtr 9294;
BA_ "SPN" SG_ 2566629630 DCACAssrInvrtr4ClntOtTmprtr 9295;
BA_ "SPN" SG_ 2566629630 DCACAssrInvrtr4CntrllrTmprtr 9291;
BA_ "SPN" SG_ 2566629630 DCACAssrInvrtr4PwrEltrnsTmprtr 9293;
BA_ "SPN" SG_ 2566630398 DCACAssIvt4ACSdDtFqCdStt 9551;
BA_ "SPN" SG_ 2566630398 DCACAssIvt4ACSdRMSCtMxLtStt 9318;
BA_ "SPN" SG_ 2566630398 DCACAssIvt4ACSdRMSVtMxLtStt 9317;
BA_ "SPN" SG_ 2566630398 DCACAssIvt4DCSdCtMLtStt 9550;
BA_ "SPN" SG_ 2566630398 DCACAssIvt4DCSdCtMxLtStt 9316;
BA_ "SPN" SG_ 2566630398 DCACAssIvt4DCSdVtMLtStt 9315;
BA_ "SPN" SG_ 2566630398 DCACAssIvt4DCSdVtMxLtStt 9549;
BA_ "SPN" SG_ 2566630654 DCACAssrInvrtr4TtlDCInptChrg 9319;
BA_ "SPN" SG_ 2566630654 DCACAssrInvrtr4TtlDCInptEnrg 9320;
BA_ "SPN" SG_ 2566630910 DCACAssIvt5IvtEtFtTpt 9338;
BA_ "SPN" SG_ 2566630910 DCACAssrInvrtr5ClntInTmprtr 9340;
BA_ "SPN" SG_ 2566630910 DCACAssrInvrtr5ClntOtTmprtr 9341;
BA_ "SPN" SG_ 2566630910 DCACAssrInvrtr5CntrllrTmprtr 9337;
BA_ "SPN" SG_ 2566630910 DCACAssrInvrtr5PwrEltrnsTmprtr 9339;
BA_ "SPN" SG_ 2566631678 DCACAssIvt5ACSdDtFqCdStt 9557;
BA_ "SPN" SG_ 2566631678 DCACAssIvt5ACSdRMSCtMxLtStt 9364;
BA_ "SPN" SG_ 2566631678 DCACAssIvt5ACSdRMSVtMxLtStt 9363;
BA_ "SPN" SG_ 2566631678 DCACAssIvt5DCSdCtMLtStt 9556;
BA_ "SPN" SG_ 2566631678 DCACAssIvt5DCSdCtMxLtStt 9362;
BA_ "SPN" SG_ 2566631678 DCACAssIvt5DCSdVtMLtStt 9361;
BA_ "SPN" SG_ 2566631678 DCACAssIvt5DCSdVtMxLtStt 9555;
BA_ "SPN" SG_ 2566631934 DCACAssrInvrtr5TtlDCInptChrg 9365;
BA_ "SPN" SG_ 2566631934 DCACAssrInvrtr5TtlDCInptEnrg 9366;
BA_ "SPN" SG_ 2566632190 WllStmltnPmpStnPrssrClrtnStPnt 9193;
BA_ "SPN" SG_ 2566632190 WSttPpDsPssCtStPt 9195;
BA_ "SPN" SG_ 2566632190 WSttPpDsPssCtStPtStts 9196;
BA_ "SPN" SG_ 2566632190 WSttPpStPssCtStPtStts 9194;
BA_ "SPN" SG_ 2566632446 WllStmltnPmpTrpFldPmpd 9192;
BA_ "SPN" SG_ 2566632446 WllStmltnPmpTtlFldPmpd 9191;
BA_ "SPN" SG_ 2566632702 WllStmltnPmpFldEndSrlNmr 9190;
BA_ "SPN" SG_ 2566632702 WllStmltnPmpPwrEndSrlNmr 9189;
BA_ "SPN" SG_ 2566632958 WllStmltnPmpFldEndTrpHrs 9187;
BA_ "SPN" SG_ 2566632958 WllStmltnPmpPwrEndTrpHrs 9188;
BA_ "SPN" SG_ 2566633214 Aftrtrtmnt1OtltOxgnPmpngCrrnt 9178;
BA_ "SPN" SG_ 2566633470 Aftrtrtmnt1IntkOxgnPmpngCrrnt 9177;
BA_ "SPN" SG_ 2566633726 DCDC4TotalHighSideCharge 9032;
BA_ "SPN" SG_ 2566633726 DCDC4TotalHighSideEnergy 9030;
BA_ "SPN" SG_ 2566633726 DCDC4TotalLowSideCharge 9033;
BA_ "SPN" SG_ 2566633726 DCDC4TotalLowSideEnergy 9031;
BA_ "SPN" SG_ 2566633982 DCDC4HghSdCrrntMxmmLmtSttng 9036;
BA_ "SPN" SG_ 2566633982 DCDC4HghSdVltgMnmmLmtSttng 9034;
BA_ "SPN" SG_ 2566633982 DCDC4HghSdVltgMxmmLmtSttng 9035;
BA_ "SPN" SG_ 2566633982 DCDC4LwSdCrrntMxmmLmtSttng 9039;
BA_ "SPN" SG_ 2566633982 DCDC4LwSdVltgBkDfltSttng 9522;
BA_ "SPN" SG_ 2566633982 DCDC4LwSdVltgMnmmLmtSttng 9037;
BA_ "SPN" SG_ 2566633982 DCDC4LwSdVltgMxmmLmtSttng 9038;
BA_ "SPN" SG_ 2566633982 DCDC4SLIBttrTmprtrMxmmLmtSttng 9042;
BA_ "SPN" SG_ 2566633982 DCDC4SLIBttTCCtMxLtStt 9041;
BA_ "SPN" SG_ 2566633982 DCDC4SLIBttTVtMxLtStt 9040;
BA_ "SPN" SG_ 2566635262 DCDC3TotalHighSideCharge 8977;
BA_ "SPN" SG_ 2566635262 DCDC3TotalHighSideEnergy 8975;
BA_ "SPN" SG_ 2566635262 DCDC3TotalLowSideCharge 8978;
BA_ "SPN" SG_ 2566635262 DCDC3TotalLowSideEnergy 8976;
BA_ "SPN" SG_ 2566635518 DCDC3HghSdCrrntMxmmLmtSttng 8981;
BA_ "SPN" SG_ 2566635518 DCDC3HghSdVltgMnmmLmtSttng 8979;
BA_ "SPN" SG_ 2566635518 DCDC3HghSdVltgMxmmLmtSttng 8980;
BA_ "SPN" SG_ 2566635518 DCDC3LwSdCrrntMxmmLmtSttng 8984;
BA_ "SPN" SG_ 2566635518 DCDC3LwSdVltgBkDfltSttng 9521;
BA_ "SPN" SG_ 2566635518 DCDC3LwSdVltgMnmmLmtSttng 8982;
BA_ "SPN" SG_ 2566635518 DCDC3LwSdVltgMxmmLmtSttng 8983;
BA_ "SPN" SG_ 2566635518 DCDC3SLIBttrTmprtrMxmmLmtSttng 8987;
BA_ "SPN" SG_ 2566635518 DCDC3SLIBttTCCtMxLtStt 8986;
BA_ "SPN" SG_ 2566635518 DCDC3SLIBttTVtMxLtStt 8985;
BA_ "SPN" SG_ 2566636798 DCDC2TotalHighSideCharge 8922;
BA_ "SPN" SG_ 2566636798 DCDC2TotalHighSideEnergy 8920;
BA_ "SPN" SG_ 2566636798 DCDC2TotalLowSideCharge 8923;
BA_ "SPN" SG_ 2566636798 DCDC2TotalLowSideEnergy 8921;
BA_ "SPN" SG_ 2566637054 DCDC2HghSdCrrntMxmmLmtSttng 8926;
BA_ "SPN" SG_ 2566637054 DCDC2HghSdVltgMnmmLmtSttng 8924;
BA_ "SPN" SG_ 2566637054 DCDC2HghSdVltgMxmmLmtSttng 8925;
BA_ "SPN" SG_ 2566637054 DCDC2LwSdCrrntMxmmLmtSttng 8929;
BA_ "SPN" SG_ 2566637054 DCDC2LwSdVltgBkDfltSttng 9520;
BA_ "SPN" SG_ 2566637054 DCDC2LwSdVltgMnmmLmtSttng 8927;
BA_ "SPN" SG_ 2566637054 DCDC2LwSdVltgMxmmLmtSttng 8928;
BA_ "SPN" SG_ 2566637054 DCDC2SLIBttrTmprtrMxmmLmtSttng 8932;
BA_ "SPN" SG_ 2566637054 DCDC2SLIBttTCCtMxLtStt 8931;
BA_ "SPN" SG_ 2566637054 DCDC2SLIBttTVtMxLtStt 8930;
BA_ "SPN" SG_ 2566638590 ExhstPrtltCntrlSstmDgnstCnt 8888;
BA_ "SPN" SG_ 2566638590 ExhstPrtltCntrlSstmDgnstTm 8887;
BA_ "SPN" SG_ 2566638846 WllStmltnPmpMntnnIntrvlHrs 8882;
BA_ "SPN" SG_ 2566638846 WllStmltnPmpPkngOprtnHrs 8884;
BA_ "SPN" SG_ 2566638846 WllStmltnPmpVlvOprtnHrs 8883;
BA_ "SPN" SG_ 2566638846 WllStmltnPmpVlvStOprtnHrs 8885;
BA_ "SPN" SG_ 2566639102 WllStmltnPmpPlngrFrngOrdrSttng 8881;
BA_ "SPN" SG_ 2566639102 WllStmltnPmpRdLdHghThrshldSttng 8880;
BA_ "SPN" SG_ 2566639102 WSttPpCstSpdHTsdStt 8879;
BA_ "SPN" SG_ 2566639102 WSttPpCstSpdLwTsdStt 8878;
BA_ "SPN" SG_ 2566639102 WSttPpDsPssHTsdStt 8877;
BA_ "SPN" SG_ 2566639102 WSttPpGBxOPssHTsdStt 8872;
BA_ "SPN" SG_ 2566639102 WSttPpGBxOPssLwTsdStt 8871;
BA_ "SPN" SG_ 2566639102 WSttPpGBxOTptHTsdStt 8874;
BA_ "SPN" SG_ 2566639102 WSttPpGBxOTptLwTsdStt 8873;
BA_ "SPN" SG_ 2566639102 WSttPpStPssHTsdStt 8876;
BA_ "SPN" SG_ 2566639102 WSttPpStPssLwTsdStt 8875;
BA_ "SPN" SG_ 2566639614 DCDC1TotalHighSideCharge 8835;
BA_ "SPN" SG_ 2566639614 DCDC1TotalHighSideEnergy 8833;
BA_ "SPN" SG_ 2566639614 DCDC1TotalLowSideCharge 8836;
BA_ "SPN" SG_ 2566639614 DCDC1TotalLowSideEnergy 8834;
BA_ "SPN" SG_ 2566639870 DCDC1HghSdCrrntMxmmLmtSttng 8826;
BA_ "SPN" SG_ 2566639870 DCDC1HghSdVltgMnmmLmtSttng 8824;
BA_ "SPN" SG_ 2566639870 DCDC1HghSdVltgMxmmLmtSttng 8825;
BA_ "SPN" SG_ 2566639870 DCDC1LwSdCrrntMxmmLmtSttng 8829;
BA_ "SPN" SG_ 2566639870 DCDC1LwSdVltgBkDfltSttng 9519;
BA_ "SPN" SG_ 2566639870 DCDC1LwSdVltgMnmmLmtSttng 8827;
BA_ "SPN" SG_ 2566639870 DCDC1LwSdVltgMxmmLmtSttng 8828;
BA_ "SPN" SG_ 2566639870 DCDC1SLIBttrTmprtrMxmmLmtSttng 8832;
BA_ "SPN" SG_ 2566639870 DCDC1SLIBttTCCtMxLtStt 8831;
BA_ "SPN" SG_ 2566639870 DCDC1SLIBttTVtMxLtStt 8830;
BA_ "SPN" SG_ 2566640382 WellStimulationPumpOilDensity 8661;
BA_ "SPN" SG_ 2566640382 WellStimulationPumpOilViscosity 8660;
BA_ "SPN" SG_ 2566640382 WllStmltnPmpOlRltvDltrt 8662;
BA_ "SPN" SG_ 2566640382 WllStmltnPmpOlTmprtr 8663;
BA_ "SPN" SG_ 2566641150 AltrntrBrngHdrIntkPrssr 8635;
BA_ "SPN" SG_ 2566641150 AltrntrOlClrDshrgPmpPrssr 8636;
BA_ "SPN" SG_ 2566641150 EngnOlClrDshrgPmpPrssr 8637;
BA_ "SPN" SG_ 2566641150 EngnOlClrIntkTmprtr 8638;
BA_ "SPN" SG_ 2566641406 EngnExhstMnfldAsltPrssr1 8619;
BA_ "SPN" SG_ 2566641406 EngnExhstMnfldAsltPrssr2 8620;
